VERSION "HNNBNNNYNNNNNNNNNNNNNNNNNNNNNNNNNNNNNNNNNN/4/%%%/4/'%**4NNN///"

NS_ :

BS_:

BU_: Frontradar Frontsensorik

BO_ 930 PSD_02: 8 Vector__XXX
 SG_ PSD_Multiplex M : 0|2@1+ (1,0) [0|3] ""  Frontsensorik
 SG_ PSD_Sys_Segment_ID m0 : 2|6@1+ (1,0) [2|63] ""  Frontsensorik
 SG_ PSD_Abz_Segment_ID m1 : 2|6@1+ (1,0) [2|63] ""  Frontsensorik
 SG_ PSD_Ges_Segment_ID m2 : 2|6@1+ (1,0) [2|63] ""  Frontsensorik
 SG_ PSD_Ort_Laenge_VZ m3 : 2|1@1+ (1,0) [0|1] ""  Frontsensorik
 SG_ PSD_Ort_Laenge m3 : 3|25@1+ (1E-005,0) [0|180] "Unit_DegreOfArc"  Frontsensorik
 SG_ PSD_Sys_Laendercode m0 : 8|8@1+ (1,0) [0|255] ""  Frontsensorik
 SG_ PSD_Abz_Segmentlaenge m1 : 8|7@1+ (2,0) [0|254] "Unit_Meter"  Frontsensorik
 SG_ PSD_Ges_Geschwindigkeit m2 : 8|5@1+ (1,0) [0|31] ""  Frontsensorik
 SG_ PSD_Ges_Geschwindigkeit_Typ m2 : 13|1@1+ (1,0) [0|1] ""  Frontsensorik
 SG_ PSD_Ges_Geschwindigkeit_Gespann m2 : 14|2@1+ (1,0) [0|3] ""  Frontsensorik
 SG_ PSD_Abz_Vorgaenger_Segment_ID m1 : 15|6@1+ (1,0) [2|63] ""  Frontsensorik
 SG_ PSD_Sys_Geschwindigkeit_Einheit m0 : 16|1@1+ (1,0) [0|1] ""  Frontsensorik
 SG_ PSD_Ges_Geschwindigkeit_Witter m2 : 16|2@1+ (1,0) [0|3] ""  Frontsensorik
 SG_ PSD_Sys_Verkehrsrichtung m0 : 17|1@1+ (1,0) [0|1] ""  Frontsensorik
 SG_ PSD_Sys_Release_Monat m0 : 18|4@1+ (1,0) [1|12] "Unit_Month"  Frontsensorik
 SG_ PSD_Ges_Geschwindigkeit_Tag_Anf m2 : 18|3@1+ (1,0) [0|7] ""  Frontsensorik
 SG_ PSD_Abz_Geschwindigkeit m1 : 21|5@1+ (1,0) [0|31] ""  Frontsensorik
 SG_ PSD_Ges_Geschwindigkeit_Tag_Ende m2 : 21|3@1+ (1,0) [0|7] ""  Frontsensorik
 SG_ PSD_Sys_Release_Jahr m0 : 22|5@1+ (1,2000) [2000|2031] "Unit_Year"  Frontsensorik
 SG_ PSD_Ges_Geschwindigkeit_Std_Anf m2 : 24|5@1+ (1,0) [0|24] "Unit_Hours"  Frontsensorik
 SG_ PSD_Abz_Geschwindigkeit_Typ m1 : 26|1@1+ (1,0) [0|1] ""  Frontsensorik
 SG_ PSD_Sys_Tunnel m0 : 27|1@1+ (1,0) [0|1] ""  Frontsensorik
 SG_ PSD_Abz_Strassenklasse m1 : 27|2@1+ (1,0) [0|3] ""  Frontsensorik
 SG_ PSD_Sys_Bruecke m0 : 28|1@1+ (1,0) [0|1] ""  Frontsensorik
 SG_ PSD_Ort_Breite_VZ m3 : 28|1@1+ (1,0) [0|1] ""  Frontsensorik
 SG_ PSD_Sys_Fahrsp_Gegenr m0 : 29|2@1+ (1,0) [0|3] ""  Frontsensorik
 SG_ PSD_Abz_ADAS_Qualitaet m1 : 29|1@1+ (1,0) [0|1] ""  Frontsensorik
 SG_ PSD_Ges_Geschwindigkeit_Std_Ende m2 : 29|5@1+ (1,0) [0|24] "Unit_Hours"  Frontsensorik
 SG_ PSD_Ort_Breite m3 : 29|24@1+ (1E-005,0) [0|90] "Unit_DegreOfArc"  Frontsensorik
 SG_ PSD_Abz_Abzweigerichtung m1 : 30|1@1+ (1,0) [0|1] ""  Frontsensorik
 SG_ PSD_Sys_TMC_Baustelle m0 : 31|1@1+ (1,0) [0|1] ""  Frontsensorik
 SG_ PSD_Abz_Abzweigewinkel m1 : 31|4@1+ (1,0) [0|15] ""  Frontsensorik
 SG_ PSD_Sys_TMC_Stau m0 : 32|1@1+ (1,0) [0|1] ""  Frontsensorik
 SG_ PSD_Sys_Bauliche_Trennung m0 : 33|2@1+ (1,0) [0|3] ""  Frontsensorik
 SG_ PSD_Ges_alter_Geschw m2 : 34|5@1+ (1,0) [0|31] ""  Frontsensorik
 SG_ PSD_Sys_Geometrieguete m0 : 35|2@1+ (1,0) [0|3] ""  Frontsensorik
 SG_ PSD_Abz_Rampe m1 : 35|2@1+ (1,0) [0|3] ""  Frontsensorik
 SG_ PSD_Sys_Maut m0 : 37|1@1+ (1,0) [0|1] ""  Frontsensorik
 SG_ PSD_Abz_Anfangskruemmung m1 : 37|8@1+ (1,0) [0|254] "Unit_None"  Frontsensorik
 SG_ PSD_Sys_Strassensituation m0 : 38|2@1+ (1,0) [0|3] ""  Frontsensorik
 SG_ PSD_Ges_alter_Geschw_Gespann m2 : 39|2@1+ (1,0) [0|3] ""  Frontsensorik
 SG_ PSD_Sys_StrKlassen_erweitert m0 : 40|3@1+ (1,0) [0|7] ""  Frontsensorik
 SG_ PSD_Ges_alter_Geschw_Witter m2 : 41|2@1+ (1,0) [0|3] ""  Frontsensorik
 SG_ PSD_Sys_Ortsschild m0 : 43|1@1+ (1,0) [0|1] ""  Frontsensorik
 SG_ PSD_Ges_alter_Geschw_Tag_Anf m2 : 43|3@1+ (1,0) [0|7] ""  Frontsensorik
 SG_ PSD_Abz_Anfangskruemmung_Vorz m1 : 45|1@1+ (1,0) [0|1] ""  Frontsensorik
 SG_ PSD_Sys_Anfangskruemmung m0 : 46|8@1+ (1,0) [0|254] "Unit_None"  Frontsensorik
 SG_ PSD_Abz_Endkruemmung m1 : 46|8@1+ (1,0) [0|254] "Unit_None"  Frontsensorik
 SG_ PSD_Ges_alter_Geschw_Tag_Ende m2 : 46|3@1+ (1,0) [0|7] ""  Frontsensorik
 SG_ PSD_Ges_alter_Geschw_Std_Anf m2 : 49|5@1+ (1,0) [0|24] "Unit_Hours"  Frontsensorik
 SG_ PSD_Ort_Hoehe m3 : 53|11@1+ (5,-1000) [-1000|8000] "Unit_Meter"  Frontsensorik
 SG_ PSD_Sys_Anfangskruemmung_Vorz m0 : 54|1@1+ (1,0) [0|1] ""  Frontsensorik
 SG_ PSD_Abz_Endkruemmung_Vorz m1 : 54|1@1+ (1,0) [0|1] ""  Frontsensorik
 SG_ PSD_Ges_alter_Geschw_Std_Ende m2 : 54|5@1+ (1,0) [0|24] "Unit_Hours"  Frontsensorik
 SG_ PSD_Sys_Anfangssteigung m0 : 55|5@1+ (0.5,0) [0|14.5] "Unit_PerCent"  Frontsensorik
 SG_ PSD_Abz_Endsteigung m1 : 55|5@1+ (0.5,0) [0|14.5] "Unit_PerCent"  Frontsensorik
 SG_ PSD_Ges_Ueberholverbot m2 : 59|2@1+ (1,0) [0|3] ""  Frontsensorik
 SG_ PSD_Sys_Anfangssteigung_Vorz m0 : 60|1@1+ (1,0) [0|1] ""  Frontsensorik
 SG_ PSD_Abz_Endsteigung_Vorz m1 : 60|1@1+ (1,0) [0|1] ""  Frontsensorik
 SG_ PSD_Sys_Ortschaft m0 : 61|1@1+ (1,0) [0|1] ""  Frontsensorik
 SG_ PSD_Abz_Fahrspuren m1 : 61|2@1+ (1,0) [0|3] ""  Frontsensorik
 SG_ PSD_Ges_Wechselverkehrszeichen m2 : 61|3@1+ (1,0) [0|7] ""  Frontsensorik
 SG_ PSD_Sys_Digitalisierung m0 : 62|1@1+ (1,0) [0|1] ""  Frontsensorik
 SG_ PSD_Sys_Zielfuehrung m0 : 63|1@1+ (1,0) [0|1] ""  Frontsensorik
 SG_ PSD_Abz_wahrscheinlichster_Pfad m1 : 63|1@1+ (1,0) [0|1] ""  Frontsensorik

BO_ 1122 PSD_04: 8 Vector__XXX
 SG_ PSD_Segment_ID : 0|6@1+ (1,0) [2|63] ""  Frontradar,Frontsensorik
 SG_ PSD_Vorgaenger_Segment_ID : 6|6@1+ (1,0) [2|63] ""  Frontradar,Frontsensorik
 SG_ PSD_Segmentlaenge : 12|7@1+ (2,0) [0|254] "Unit_Meter"  Frontradar,Frontsensorik
 SG_ PSD_Strassenkategorie : 19|3@1+ (1,0) [0|7] ""  Frontradar,Frontsensorik
 SG_ PSD_Endkruemmung : 22|8@1+ (1,0) [0|254] "Unit_None"  Frontradar,Frontsensorik
 SG_ PSD_Endkruemmung_Vorz : 30|1@1+ (1,0) [0|1] ""  Frontradar,Frontsensorik
 SG_ PSD_Idenditaets_ID : 31|6@1+ (1,0) [2|63] ""  Frontradar,Frontsensorik
 SG_ PSD_ADAS_Qualitaet : 37|1@1+ (1,0) [0|1] ""  Frontradar,Frontsensorik
 SG_ PSD_wahrscheinlichster_Pfad : 38|1@1+ (1,0) [0|1] ""  Frontradar,Frontsensorik
 SG_ PSD_Geradester_Pfad : 39|1@1+ (1,0) [0|1] ""  Frontradar,Frontsensorik
 SG_ PSD_Fahrspuren_Anzahl : 40|3@1+ (1,0) [0|7] ""  Frontradar,Frontsensorik
 SG_ PSD_Bebauung : 43|1@1+ (1,0) [0|1] ""  Frontradar,Frontsensorik
 SG_ PSD_Segment_Komplett : 44|1@1+ (1,0) [0|1] ""  Frontradar,Frontsensorik
 SG_ PSD_Rampe : 45|2@1+ (1,0) [0|3] ""  Frontradar,Frontsensorik
 SG_ PSD_Anfangskruemmung : 47|8@1+ (1,0) [0|254] ""  Frontradar,Frontsensorik
 SG_ PSD_Anfangskruemmung_Vorz : 55|1@1+ (1,0) [0|1] ""  Frontradar,Frontsensorik
 SG_ PSD_Abzweigerichtung : 56|1@1+ (1,0) [0|1] ""  Frontradar,Frontsensorik
 SG_ PSD_Abzweigewinkel : 57|7@1+ (1.417323,0) [0|180.000021] ""  Frontradar,Frontsensorik

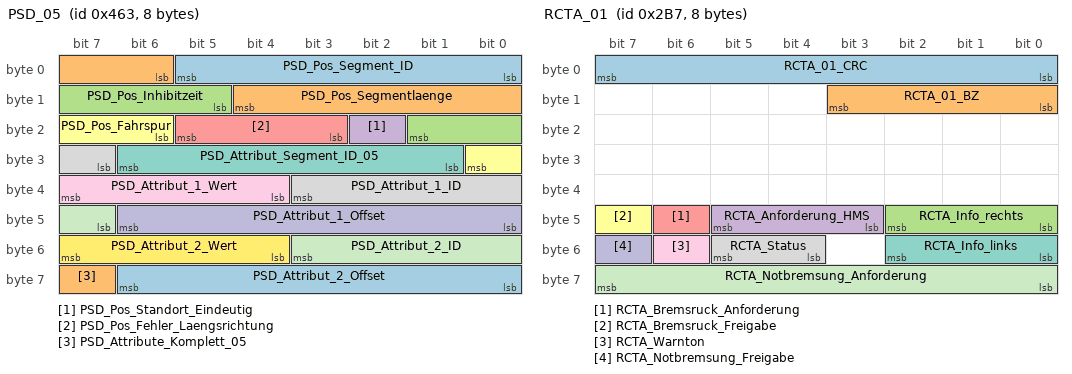
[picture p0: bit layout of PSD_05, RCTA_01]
BO_ 1123 PSD_05: 8 Vector__XXX
 SG_ PSD_Pos_Segment_ID : 0|6@1+ (1,0) [2|63] ""  Frontradar,Frontsensorik
 SG_ PSD_Pos_Segmentlaenge : 6|7@1+ (2,0) [0|254] "Unit_Meter"  Frontradar,Frontsensorik
 SG_ PSD_Pos_Inhibitzeit : 13|5@1+ (10,0) [0|310] "Unit_MilliSecon"  Frontradar,Frontsensorik
 SG_ PSD_Pos_Standort_Eindeutig : 18|1@1+ (1,0) [0|1] ""  Frontradar,Frontsensorik
 SG_ PSD_Pos_Fehler_Laengsrichtung : 19|3@1+ (1,0) [0|7] ""  Frontradar,Frontsensorik
 SG_ PSD_Pos_Fahrspur : 22|3@1+ (1,0) [0|7] ""  Frontradar,Frontsensorik
 SG_ PSD_Attribut_Segment_ID_05 : 25|6@1+ (1,0) [2|63] ""  Frontradar,Frontsensorik
 SG_ PSD_Attribut_1_ID : 31|5@1+ (1,0) [1|31] ""  Frontradar,Frontsensorik
 SG_ PSD_Attribut_1_Wert : 36|4@1+ (1,0) [0|15] ""  Frontradar,Frontsensorik
 SG_ PSD_Attribut_1_Offset : 40|7@1+ (2,0) [0|254] "Unit_Meter"  Frontradar,Frontsensorik
 SG_ PSD_Attribut_2_ID : 47|5@1+ (1,0) [1|31] ""  Frontradar,Frontsensorik
 SG_ PSD_Attribut_2_Wert : 52|4@1+ (1,0) [0|15] ""  Frontradar,Frontsensorik
 SG_ PSD_Attribut_2_Offset : 56|7@1+ (2,0) [0|254] "Unit_Meter"  Frontradar,Frontsensorik
 SG_ PSD_Attribute_Komplett_05 : 63|1@1+ (1,0) [0|1] ""  Frontradar,Frontsensorik

BO_ 1124 PSD_06: 8 Vector__XXX
 SG_ PSD_06_Mux M : 0|3@1+ (1,0) [0|7] ""  Frontradar,Frontsensorik
 SG_ PSD_Sys_Segment_ID m0 : 3|6@1+ (1,0) [2|63] ""  Frontradar,Frontsensorik
 SG_ PSD_Attribut_Segment_ID m1 : 3|6@1+ (1,0) [2|63] ""  Frontradar,Frontsensorik
 SG_ PSD_Ges_Segment_ID m2 : 3|6@1+ (1,0) [2|63] ""  Frontradar,Frontsensorik
 SG_ PSD_Baum_Laenge_VZ m3 : 3|1@1+ (1,0) [0|1] ""  Frontradar,Frontsensorik
 SG_ PSD_Steigung_1_Segment_ID m4 : 3|6@1+ (1,0) [2|63] ""  Frontradar,Frontsensorik
 SG_ PSD_Baum_Laenge m3 : 4|25@1+ (1E-005,0) [0|180] "Unit_DegreOfArc"  Frontradar,Frontsensorik
 SG_ PSD_Sys_Laendercode m0 : 9|8@1+ (1,0) [0|255] ""  Frontradar,Frontsensorik
 SG_ PSD_Attribut_3_ID m1 : 9|5@1+ (1,0) [1|31] ""  Frontradar,Frontsensorik
 SG_ PSD_Ges_Offset m2 : 9|7@1+ (2,0) [0|254] "Unit_Meter"  Frontradar,Frontsensorik
 SG_ PSD_Steigung_1_A_Steigung m4 : 9|7@1+ (0.12,0) [0|15] "Unit_PerCent"  Frontradar,Frontsensorik
 SG_ PSD_Attribut_3_Offset m1 : 14|7@1+ (2,0) [0|254] "Unit_Meter"  Frontradar,Frontsensorik
 SG_ PSD_Ges_Geschwindigkeit m2 : 16|5@1+ (1,0) [0|31] ""  Frontradar,Frontsensorik
 SG_ PSD_Steigung_1_A_Vorz m4 : 16|1@1+ (1,0) [0|1] ""  Frontradar,Frontsensorik
 SG_ PSD_Sys_Geschwindigkeit_Einheit m0 : 17|1@1+ (1,0) [0|1] ""  Frontradar,Frontsensorik
 SG_ PSD_Steigung_1_A_Offset m4 : 17|7@1+ (2,0) [0|254] "Unit_Meter"  Frontradar,Frontsensorik
 SG_ PSD_Sys_Verkehrsrichtung m0 : 18|1@1+ (1,0) [0|1] ""  Frontradar,Frontsensorik
 SG_ PSD_Sys_Geometrieguete m0 : 19|2@1+ (1,0) [0|3] ""  Frontradar,Frontsensorik
 SG_ PSD_Sys_Mapmatchingguete m0 : 21|2@1+ (1,0) [0|3] ""  Frontradar,Frontsensorik
 SG_ PSD_Attribut_3_Wert m1 : 21|4@1+ (1,0) [0|15] ""  Frontradar,Frontsensorik
 SG_ PSD_Ges_Typ m2 : 21|2@1+ (1,0) [0|3] ""  Frontradar,Frontsensorik
 SG_ PSD_Sys_Alter_Karte m0 : 23|3@1+ (1,0) [0|7] ""  Frontradar,Frontsensorik
 SG_ PSD_Ges_Spur_Geschw_Begrenzung m2 : 23|6@1+ (1,0) [0|63] ""  Frontradar,Frontsensorik
 SG_ PSD_Steigung_1_B_Steigung m4 : 24|7@1+ (0.12,0) [0|15] "Unit_PerCent"  Frontradar,Frontsensorik
 SG_ PSD_Attribut_4_ID m1 : 25|5@1+ (1,0) [1|31] ""  Frontradar,Frontsensorik
 SG_ PSD_Sys_Zielfuehrung m0 : 26|1@1+ (1,0) [0|1] ""  Frontradar,Frontsensorik
 SG_ PSD_Sys_US_State m0 : 27|6@1+ (1,0) [0|63] ""  Frontradar,Frontsensorik
 SG_ PSD_Ges_Geschwindigkeit_Gespann m2 : 29|2@1+ (1,0) [0|3] ""  Frontradar,Frontsensorik
 SG_ PSD_Baum_Breite_VZ m3 : 29|1@1+ (1,0) [0|1] ""  Frontradar,Frontsensorik
 SG_ PSD_Attribut_4_Wert m1 : 30|4@1+ (1,0) [0|15] ""  Frontradar,Frontsensorik
 SG_ PSD_Baum_Breite m3 : 30|24@1+ (1E-005,0) [0|90] "Unit_DegreOfArc"  Frontradar,Frontsensorik
 SG_ PSD_Ges_Geschwindigkeit_Witter m2 : 31|2@1+ (1,0) [0|3] ""  Frontradar,Frontsensorik
 SG_ PSD_Steigung_1_B_Vorz m4 : 31|1@1+ (1,0) [0|1] ""  Frontradar,Frontsensorik
 SG_ PSD_Steigung_1_B_Offset m4 : 32|7@1+ (2,0) [0|254] "Unit_Meter"  Frontradar,Frontsensorik
 SG_ PSD_Ges_Geschwindigkeit_Tag_Anf m2 : 33|3@1+ (1,0) [0|7] ""  Frontradar,Frontsensorik
 SG_ PSD_Attribut_4_Offset m1 : 34|7@1+ (2,0) [0|254] "Unit_Meter"  Frontradar,Frontsensorik
 SG_ PSD_Ges_Geschwindigkeit_Tag_Ende m2 : 36|3@1+ (1,0) [0|7] ""  Frontradar,Frontsensorik
 SG_ PSD_Ges_Geschwindigkeit_Std_Anf m2 : 39|5@1+ (1,0) [0|24] "Unit_Hours"  Frontradar,Frontsensorik
 SG_ PSD_Steigung_1_Attribute_kompl m4 : 39|1@1+ (1,0) [0|1] ""  Frontradar,Frontsensorik
 SG_ PSD_Steigung_2_Segment_ID m4 : 40|6@1+ (1,0) [2|63] ""  Frontradar,Frontsensorik
 SG_ PSD_Attribut_5_ID m1 : 41|5@1+ (1,0) [1|31] ""  Frontradar,Frontsensorik
 SG_ PSD_Ges_Geschwindigkeit_Std_Ende m2 : 44|5@1+ (1,0) [0|24] "Unit_Hours"  Frontradar,Frontsensorik
 SG_ PSD_Attribut_5_Offset m1 : 46|7@1+ (2,0) [0|254] "Unit_Meter"  Frontradar,Frontsensorik
 SG_ PSD_Steigung_2_Steigung m4 : 46|7@1+ (0.12,0) [0|15] "Unit_PerCent"  Frontradar,Frontsensorik
 SG_ PSD_Ges_Ueberholverbot m2 : 49|2@1+ (1,0) [0|3] ""  Frontradar,Frontsensorik
 SG_ PSD_Ges_Wechselverkehrszeichen m2 : 51|3@1+ (1,0) [0|7] ""  Frontradar,Frontsensorik
 SG_ PSD_Attribut_5_Wert m1 : 53|4@1+ (1,0) [0|15] ""  Frontradar,Frontsensorik
 SG_ PSD_Steigung_2_Vorz m4 : 53|1@1+ (1,0) [0|1] ""  Frontradar,Frontsensorik
 SG_ PSD_Wechselverkehrszeichen_Typ m2 : 54|2@1+ (1,0) [0|3] ""  Frontradar,Frontsensorik
 SG_ PSD_Baum_Ausrichtung m3 : 54|10@1+ (0.3515625,0) [0|359.6484375] "Unit_DegreOfArc"  Frontradar,Frontsensorik
 SG_ PSD_Steigung_2_Offset m4 : 54|7@1+ (2,0) [0|254] "Unit_Meter"  Frontradar,Frontsensorik
 SG_ PSD_Ges_Gesetzlich_Kategorie m2 : 56|3@1+ (1,0) [0|7] ""  Frontradar,Frontsensorik
 SG_ PSD_Attribute_Komplett_06 m1 : 57|1@1+ (1,0) [0|1] ""  Frontradar,Frontsensorik
 SG_ PSD_Ges_Gesetzlich_Zusatz m2 : 59|2@1+ (1,0) [0|3] ""  Frontradar,Frontsensorik
 SG_ PSD_Ges_Verkehrszeichen_Quelle m2 : 61|2@1+ (1,0) [0|3] ""  Frontradar,Frontsensorik
 SG_ PSD_Steigung_2_Attribute_kompl m4 : 61|1@1+ (1,0) [0|1] ""  Frontradar,Frontsensorik
 SG_ PSD_Ges_Attribute_Komplett m2 : 63|1@1+ (1,0) [0|1] ""  Frontradar,Frontsensorik

BO_ 695 RCTA_01: 8 Vector__XXX
 SG_ RCTA_01_CRC : 0|8@1+ (1,0) [0|255] "" Vector__XXX
 SG_ RCTA_01_BZ : 8|4@1+ (1,0) [0|15] "" Vector__XXX
 SG_ RCTA_Info_rechts : 40|3@1+ (1,0) [0|7] "" Vector__XXX
 SG_ RCTA_Anforderung_HMS : 43|3@1+ (1,0) [0|7] "" Vector__XXX
 SG_ RCTA_Bremsruck_Anforderung : 46|1@1+ (1,0) [0|1] "" Vector__XXX
 SG_ RCTA_Bremsruck_Freigabe : 47|1@1+ (1,0) [0|1] "" Vector__XXX
 SG_ RCTA_Info_links : 48|3@1+ (1,0) [0|7] "" Vector__XXX
 SG_ RCTA_Status : 52|2@1+ (1,0) [0|3] "" Vector__XXX
 SG_ RCTA_Warnton : 54|1@1+ (1,0) [0|1] "" Vector__XXX
 SG_ RCTA_Notbremsung_Freigabe : 55|1@1+ (1,0) [0|1] "" Vector__XXX
 SG_ RCTA_Notbremsung_Anforderung : 56|8@1+ (0.078,-19.812) [-19.734|0] "Unit_MeterPerSeconSquar" Vector__XXX

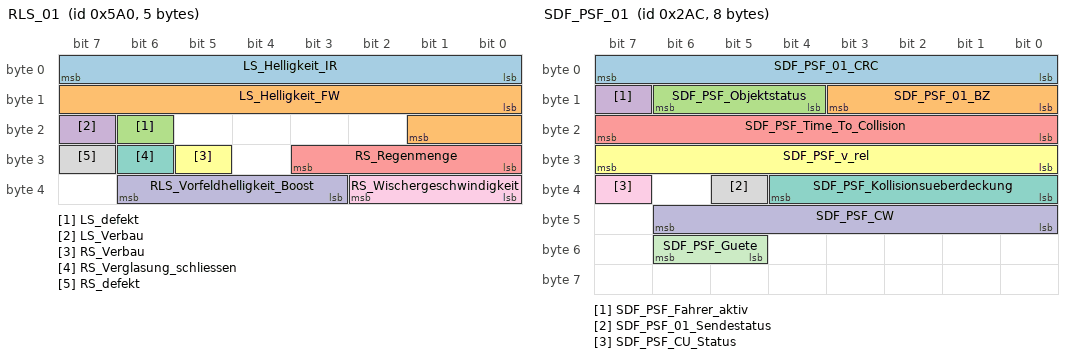
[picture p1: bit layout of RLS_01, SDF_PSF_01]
BO_ 1440 RLS_01: 5 Vector__XXX
 SG_ LS_Helligkeit_IR : 0|8@1+ (400,0) [0|101200] "Unit_Lux" Vector__XXX
 SG_ LS_Helligkeit_FW : 8|10@1+ (6,0) [0|6126] "Unit_Lux" Vector__XXX
 SG_ LS_defekt : 22|1@1+ (1,0) [0|1] "" Vector__XXX
 SG_ LS_Verbau : 23|1@1+ (1,0) [0|1] "" Vector__XXX
 SG_ RS_Regenmenge : 24|4@1+ (10,0) [0|100] "Unit_PerCent"  Frontsensorik
 SG_ RS_Verbau : 29|1@1+ (1,0) [0|1] "" Vector__XXX
 SG_ RS_Verglasung_schliessen : 30|1@1+ (1,0) [0|1] "" Vector__XXX
 SG_ RS_defekt : 31|1@1+ (1,0) [0|1] "" Vector__XXX
 SG_ RS_Wischergeschwindigkeit : 32|3@1+ (1,0) [0|7] ""  Frontsensorik
 SG_ RLS_Vorfeldhelligkeit_Boost : 35|4@1+ (1,0) [0|15] "" Vector__XXX

BO_ 684 SDF_PSF_01: 8 Frontradar
 SG_ SDF_PSF_01_CRC : 0|8@1+ (1,0) [0|255] "" Vector__XXX
 SG_ SDF_PSF_01_BZ : 8|4@1+ (1,0) [0|15] "" Vector__XXX
 SG_ SDF_PSF_Objektstatus : 12|3@1+ (1,0) [0|7] "" Vector__XXX
 SG_ SDF_PSF_Fahrer_aktiv : 15|1@1+ (1,0) [0|1] "" Vector__XXX
 SG_ SDF_PSF_Time_To_Collision : 16|8@1+ (0.01,0) [0|2.5] "Unit_Secon" Vector__XXX
 SG_ SDF_PSF_v_rel : 24|8@1+ (0.4,0) [0.4|101.2] "Unit_MeterPerSecon" Vector__XXX
 SG_ SDF_PSF_Kollisionsueberdeckung : 32|5@1+ (0.1,0) [0.1|2.8] "Unit_Meter" Vector__XXX
 SG_ SDF_PSF_01_Sendestatus : 37|1@1+ (1,0) [0|1] "" Vector__XXX
 SG_ SDF_PSF_CU_Status : 39|1@1+ (1,0) [0|1] "" Vector__XXX
 SG_ SDF_PSF_CW : 40|7@1+ (1,0) [0|100] "" Vector__XXX
 SG_ SDF_PSF_Guete : 53|2@1+ (1,0) [0|3] "" Vector__XXX

BO_ 783 SWA_01: 8 Vector__XXX
 SG_ SWA_01_CRC : 0|8@1+ (1,0) [0|255] ""  Frontradar
 SG_ SWA_01_BZ : 8|4@1+ (1,0) [0|15] ""  Frontradar
 SG_ SWA_Anzeigen : 12|4@1+ (1,0) [0|15] "" Vector__XXX
 SG_ SWA_Blindheit_erkannt : 16|1@1+ (1,0) [0|1] ""  Frontradar
 SG_ SWA_rel_Nichtverf : 17|1@1+ (1,0) [0|1] ""  Frontradar
 SG_ SWA_rel_Fehler : 18|1@1+ (1,0) [0|1] ""  Frontradar
 SG_ SWA_Sta_aktiv : 19|1@1+ (1,0) [0|1] "" Vector__XXX
 SG_ SWA_Sta_passiv : 20|1@1+ (1,0) [0|1] "" Vector__XXX
 SG_ SWA_FT_RueckLED : 21|1@1+ (1,0) [0|1] "" Vector__XXX
 SG_ ASW_Status : 22|2@1+ (1,0) [0|3] "" Vector__XXX
 SG_ SWA_Standziele_li : 24|1@1+ (1,0) [0|1] ""  Frontradar
 SG_ SWA_Kolonne_li : 25|1@1+ (1,0) [0|1] ""  Frontradar
 SG_ SWA_Infostufe_SWA_li : 26|1@1+ (1,0) [0|1] ""  Frontradar,Frontsensorik
 SG_ SWA_Warnung_SWA_li : 27|1@1+ (1,0) [0|1] ""  Frontradar,Frontsensorik
 SG_ ASW_Warnung_FS : 28|1@1+ (1,0) [0|1] "" Vector__XXX
 SG_ ASW_Warnung_BFS : 29|1@1+ (1,0) [0|1] "" Vector__XXX
 SG_ ASW_Kombitexte : 30|3@1+ (1,0) [0|7] "" Vector__XXX
 SG_ SWA_Kolonne_mi : 33|1@1+ (1,0) [0|1] ""  Frontradar
 SG_ SWA_Standziele_re : 40|1@1+ (1,0) [0|1] ""  Frontradar
 SG_ SWA_Kolonne_re : 41|1@1+ (1,0) [0|1] ""  Frontradar
 SG_ SWA_Infostufe_SWA_re : 42|1@1+ (1,0) [0|1] ""  Frontradar,Frontsensorik
 SG_ SWA_Warnung_SWA_re : 43|1@1+ (1,0) [0|1] ""  Frontradar,Frontsensorik
 SG_ HRE_Anzeigetexte : 44|4@1+ (1,0) [0|15] "" Vector__XXX
 SG_ SWA_Gischtzaehler : 48|7@1+ (1,0) [0|100] "Unit_PerCent"  Frontsensorik
 SG_ Heckradar_Kombitexte : 56|5@1+ (1,0) [0|31] "" Vector__XXX
 SG_ RCTA_Kombitexte : 61|3@1+ (1,0) [0|7] "" Vector__XXX

BO_ 1413 Systeminfo_01: 8 Vector__XXX
 SG_ SI_Sammel_SG_Fehler : 0|6@1+ (1,0) [0|60] "" Vector__XXX
 SG_ SI_Diagnose_Aktiv : 7|1@1+ (1,0) [0|1] "" Vector__XXX
 SG_ SI_QRS_Mode : 8|1@1+ (1,0) [0|1] "" Vector__XXX
 SG_ SI_T_Mode : 9|1@1+ (1,0) [0|1] "" Vector__XXX
 SG_ SI_NWDF : 10|1@1+ (1,0) [0|1] ""  Frontradar,Frontsensorik
 SG_ SI_NWDF_gueltig : 11|1@1+ (1,0) [0|1] ""  Frontradar,Frontsensorik
 SG_ SI_Sammelfehler : 12|1@1+ (1,0) [0|1] "" Vector__XXX
 SG_ GW_KD_Fehler : 13|1@1+ (1,0) [0|1] "" Vector__XXX
 SG_ SI_T_Schutz : 14|1@1+ (1,0) [0|1] ""  Frontradar
 SG_ SI_BUS_01 : 16|1@1+ (1,0) [0|1] "" Vector__XXX
 SG_ SI_BUS_02 : 17|1@1+ (1,0) [0|1] "" Vector__XXX
 SG_ SI_BUS_03 : 18|1@1+ (1,0) [0|1] "" Vector__XXX
 SG_ SI_BUS_04 : 19|1@1+ (1,0) [0|1] "" Vector__XXX
 SG_ SI_BUS_05 : 20|1@1+ (1,0) [0|1] "" Vector__XXX
 SG_ SI_BUS_06 : 21|1@1+ (1,0) [0|1] "" Vector__XXX
 SG_ SI_BUS_07 : 22|1@1+ (1,0) [0|1] "" Vector__XXX
 SG_ SI_BUS_08 : 23|1@1+ (1,0) [0|1] "" Vector__XXX
 SG_ SI_BUS_09 : 24|1@1+ (1,0) [0|1] "" Vector__XXX
 SG_ SI_BUS_10 : 25|1@1+ (1,0) [0|1] "" Vector__XXX
 SG_ SI_BUS_11 : 26|1@1+ (1,0) [0|1] "" Vector__XXX
 SG_ SI_BUS_12 : 27|1@1+ (1,0) [0|1] "" Vector__XXX
 SG_ SI_BUS_13 : 28|1@1+ (1,0) [0|1] "" Vector__XXX
 SG_ SI_BUS_14 : 29|1@1+ (1,0) [0|1] "" Vector__XXX
 SG_ SI_BUS_15 : 30|1@1+ (1,0) [0|1] "" Vector__XXX
 SG_ SI_Bus_Identifikation : 32|8@1+ (1,0) [0|255] "" Vector__XXX

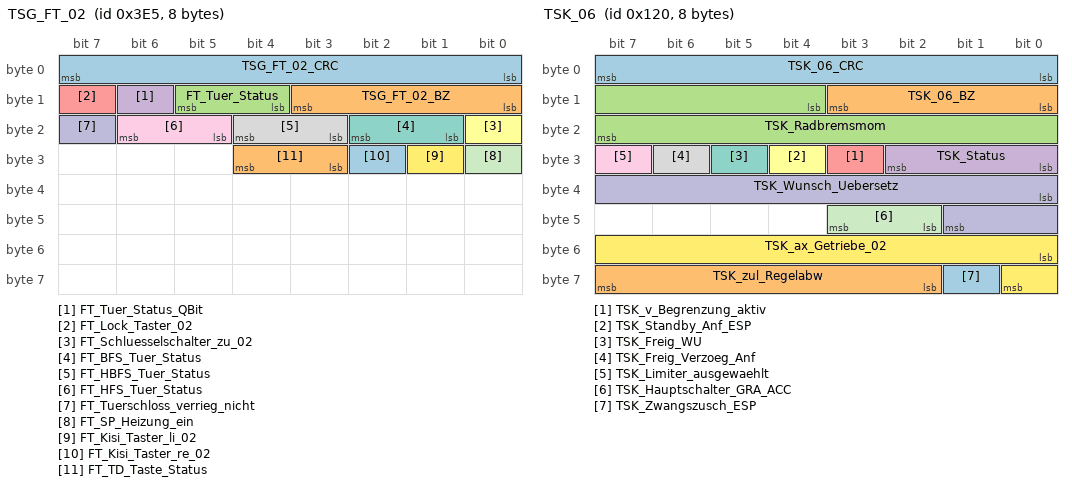
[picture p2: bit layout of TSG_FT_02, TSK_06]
BO_ 997 TSG_FT_02: 8 Vector__XXX
 SG_ TSG_FT_02_CRC : 0|8@1+ (1,0) [0|255] ""  Frontradar
 SG_ TSG_FT_02_BZ : 8|4@1+ (1,0) [0|15] ""  Frontradar
 SG_ FT_Tuer_Status : 12|2@1+ (1,0) [0|3] ""  Frontradar
 SG_ FT_Tuer_Status_QBit : 14|1@1+ (1,0) [0|1] ""  Frontradar
 SG_ FT_Lock_Taster_02 : 15|1@1+ (1,0) [0|1] "" Vector__XXX
 SG_ FT_Schluesselschalter_zu_02 : 16|1@1+ (1,0) [0|1] "" Vector__XXX
 SG_ FT_BFS_Tuer_Status : 17|2@1+ (1,0) [0|3] "" Vector__XXX
 SG_ FT_HBFS_Tuer_Status : 19|2@1+ (1,0) [0|3] "" Vector__XXX
 SG_ FT_HFS_Tuer_Status : 21|2@1+ (1,0) [0|3] "" Vector__XXX
 SG_ FT_Tuerschloss_verrieg_nicht : 23|1@1+ (1,0) [0|1] "" Vector__XXX
 SG_ FT_SP_Heizung_ein : 24|1@1+ (1,0) [0|1] "" Vector__XXX
 SG_ FT_Kisi_Taster_li_02 : 25|1@1+ (1,0) [0|1] "" Vector__XXX
 SG_ FT_Kisi_Taster_re_02 : 26|1@1+ (1,0) [0|1] "" Vector__XXX
 SG_ FT_TD_Taste_Status : 27|2@1+ (1,0) [0|3] "" Vector__XXX

BO_ 288 TSK_06: 8 Vector__XXX
 SG_ TSK_06_CRC : 0|8@1+ (1,0) [0|255] ""  Frontradar,Frontsensorik
 SG_ TSK_06_BZ : 8|4@1+ (1,0) [0|15] ""  Frontradar,Frontsensorik
 SG_ TSK_Radbremsmom : 12|12@1+ (8,0) [0|32760] "Unit_NewtoMeter" Vector__XXX
 SG_ TSK_Status : 24|3@1+ (1,0) [0|7] ""  Frontradar,Frontsensorik
 SG_ TSK_v_Begrenzung_aktiv : 27|1@1+ (1,0) [0|1] "" Vector__XXX
 SG_ TSK_Standby_Anf_ESP : 28|1@1+ (1,0) [0|1] "" Vector__XXX
 SG_ TSK_Freig_WU : 29|1@1+ (1,0) [0|1] "" Vector__XXX
 SG_ TSK_Freig_Verzoeg_Anf : 30|1@1+ (1,0) [0|1] "" Vector__XXX
 SG_ TSK_Limiter_ausgewaehlt : 31|1@1+ (1,0) [0|1] ""  Frontradar
 SG_ TSK_Wunsch_Uebersetz : 32|10@1+ (0.0245,0) [0.0245|25.0635] "" Vector__XXX
 SG_ TSK_Hauptschalter_GRA_ACC : 42|2@1+ (1,0) [0|3] ""  Frontradar
 SG_ TSK_ax_Getriebe_02 : 48|9@1+ (0.024,-2.016) [-2.016|10.224] "Unit_MeterPerSeconSquar" Vector__XXX
 SG_ TSK_Zwangszusch_ESP : 57|1@1+ (1,0) [0|1] "" Vector__XXX
 SG_ TSK_zul_Regelabw : 58|6@1+ (0.024,0) [0|1.512] "Unit_MeterPerSeconSquar" Vector__XXX

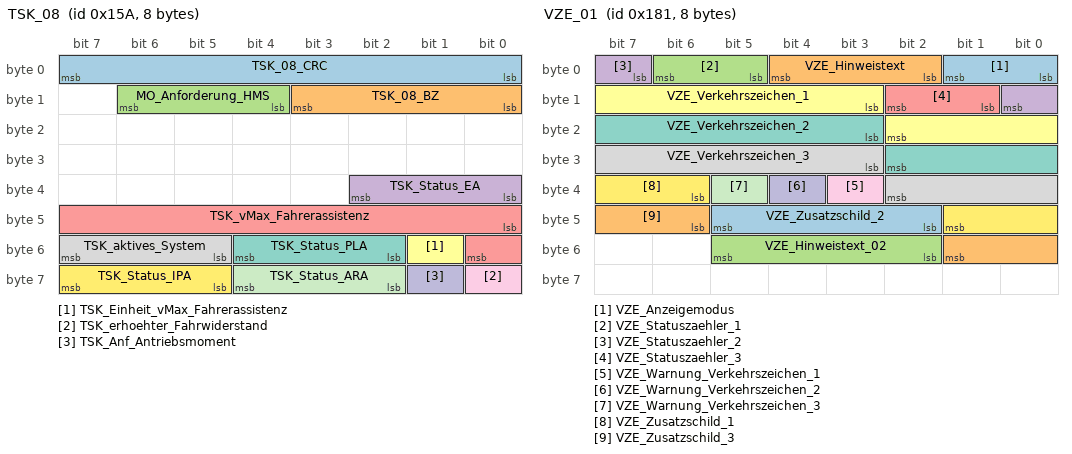
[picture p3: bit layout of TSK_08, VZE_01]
BO_ 346 TSK_08: 8 Vector__XXX
 SG_ TSK_08_CRC : 0|8@1+ (1,0) [0|255] ""  Frontradar
 SG_ TSK_08_BZ : 8|4@1+ (1,0) [0|15] ""  Frontradar
 SG_ MO_Anforderung_HMS : 12|3@1+ (1,0) [0|7] "" Vector__XXX
 SG_ TSK_Status_EA : 32|3@1+ (1,0) [0|7] "" Vector__XXX
 SG_ TSK_vMax_Fahrerassistenz : 40|9@1+ (1,0) [0|510] ""  Frontradar
 SG_ TSK_Einheit_vMax_Fahrerassistenz : 49|1@1+ (1,0) [0|1] ""  Frontradar
 SG_ TSK_Status_PLA : 50|3@1+ (1,0) [0|7] "" Vector__XXX
 SG_ TSK_aktives_System : 53|3@1+ (1,0) [0|7] "" Vector__XXX
 SG_ TSK_erhoehter_Fahrwiderstand : 56|1@1+ (1,0) [0|1] "" Vector__XXX
 SG_ TSK_Anf_Antriebsmoment : 57|1@1+ (1,0) [0|1] "" Vector__XXX
 SG_ TSK_Status_ARA : 58|3@1+ (1,0) [0|7] "" Vector__XXX
 SG_ TSK_Status_IPA : 61|3@1+ (1,0) [0|7] "" Vector__XXX

BO_ 1019 TSK_Ausrollkurve_01: 8 Vector__XXX
 SG_ TSK_Ausrollkurve_Schub_Reku_01 m0 : 0|7@1+ (2,0) [0|252] "Unit_KiloMeterPerHour"  Frontradar
 SG_ TSK_Ausrollkurve_Schub_Reku_05 m1 : 0|7@1+ (2,0) [0|252] "Unit_KiloMeterPerHour"  Frontradar
 SG_ TSK_Ausrollkurve_Schub_Reku_09 m2 : 0|7@1+ (2,0) [0|252] "Unit_KiloMeterPerHour"  Frontradar
 SG_ TSK_Ausrollkurve_Schub_Reku_13 m3 : 0|7@1+ (2,0) [0|252] "Unit_KiloMeterPerHour"  Frontradar
 SG_ TSK_Ausrollkurve_Schub_Reku_17 m4 : 0|7@1+ (2,0) [0|252] "Unit_KiloMeterPerHour"  Frontradar
 SG_ TSK_Ausrollkurve_Schub_Reku_02 m0 : 7|7@1+ (2,0) [0|252] "Unit_KiloMeterPerHour"  Frontradar
 SG_ TSK_Ausrollkurve_Schub_Reku_06 m1 : 7|7@1+ (2,0) [0|252] "Unit_KiloMeterPerHour"  Frontradar
 SG_ TSK_Ausrollkurve_Schub_Reku_10 m2 : 7|7@1+ (2,0) [0|252] "Unit_KiloMeterPerHour"  Frontradar
 SG_ TSK_Ausrollkurve_Schub_Reku_14 m3 : 7|7@1+ (2,0) [0|252] "Unit_KiloMeterPerHour"  Frontradar
 SG_ TSK_Ausrollkurve_Schub_Reku_18 m4 : 7|7@1+ (2,0) [0|252] "Unit_KiloMeterPerHour"  Frontradar
 SG_ TSK_Ausrollkurve_Schub_Reku_03 m0 : 14|7@1+ (2,0) [0|252] "Unit_KiloMeterPerHour"  Frontradar
 SG_ TSK_Ausrollkurve_Schub_Reku_07 m1 : 14|7@1+ (2,0) [0|252] "Unit_KiloMeterPerHour"  Frontradar
 SG_ TSK_Ausrollkurve_Schub_Reku_11 m2 : 14|7@1+ (2,0) [0|252] "Unit_KiloMeterPerHour"  Frontradar
 SG_ TSK_Ausrollkurve_Schub_Reku_15 m3 : 14|7@1+ (2,0) [0|252] "Unit_KiloMeterPerHour"  Frontradar
 SG_ TSK_Ausrollkurve_Schub_Reku_19 m4 : 14|7@1+ (2,0) [0|252] "Unit_KiloMeterPerHour"  Frontradar
 SG_ TSK_Ausrollkurve_Schub_Reku_04 m0 : 21|7@1+ (2,0) [0|252] "Unit_KiloMeterPerHour"  Frontradar
 SG_ TSK_Ausrollkurve_Schub_Reku_08 m1 : 21|7@1+ (2,0) [0|252] "Unit_KiloMeterPerHour"  Frontradar
 SG_ TSK_Ausrollkurve_Schub_Reku_12 m2 : 21|7@1+ (2,0) [0|252] "Unit_KiloMeterPerHour"  Frontradar
 SG_ TSK_Ausrollkurve_Schub_Reku_16 m3 : 21|7@1+ (2,0) [0|252] "Unit_KiloMeterPerHour"  Frontradar
 SG_ TSK_Ausrollkurve_Schub_Reku_20 m4 : 21|7@1+ (2,0) [0|252] "Unit_KiloMeterPerHour"  Frontradar
 SG_ TSK_Ausrollkurve_Segeln_01 m0 : 28|7@1+ (2,0) [0|252] "Unit_KiloMeterPerHour"  Frontradar
 SG_ TSK_Ausrollkurve_Segeln_05 m1 : 28|7@1+ (2,0) [0|252] "Unit_KiloMeterPerHour"  Frontradar
 SG_ TSK_Ausrollkurve_Segeln_09 m2 : 28|7@1+ (2,0) [0|252] "Unit_KiloMeterPerHour"  Frontradar
 SG_ TSK_Ausrollkurve_Segeln_13 m3 : 28|7@1+ (2,0) [0|252] "Unit_KiloMeterPerHour"  Frontradar
 SG_ TSK_Ausrollkurve_Segeln_17 m4 : 28|7@1+ (2,0) [0|252] "Unit_KiloMeterPerHour"  Frontradar
 SG_ TSK_Ausrollkurve_Segeln_02 m0 : 35|7@1+ (2,0) [0|252] "Unit_KiloMeterPerHour"  Frontradar
 SG_ TSK_Ausrollkurve_Segeln_06 m1 : 35|7@1+ (2,0) [0|252] "Unit_KiloMeterPerHour"  Frontradar
 SG_ TSK_Ausrollkurve_Segeln_10 m2 : 35|7@1+ (2,0) [0|252] "Unit_KiloMeterPerHour"  Frontradar
 SG_ TSK_Ausrollkurve_Segeln_14 m3 : 35|7@1+ (2,0) [0|252] "Unit_KiloMeterPerHour"  Frontradar
 SG_ TSK_Ausrollkurve_Segeln_18 m4 : 35|7@1+ (2,0) [0|252] "Unit_KiloMeterPerHour"  Frontradar
 SG_ TSK_Ausrollkurve_Segeln_03 m0 : 42|7@1+ (2,0) [0|252] "Unit_KiloMeterPerHour"  Frontradar
 SG_ TSK_Ausrollkurve_Segeln_07 m1 : 42|7@1+ (2,0) [0|252] "Unit_KiloMeterPerHour"  Frontradar
 SG_ TSK_Ausrollkurve_Segeln_11 m2 : 42|7@1+ (2,0) [0|252] "Unit_KiloMeterPerHour"  Frontradar
 SG_ TSK_Ausrollkurve_Segeln_15 m3 : 42|7@1+ (2,0) [0|252] "Unit_KiloMeterPerHour"  Frontradar
 SG_ TSK_Ausrollkurve_Segeln_19 m4 : 42|7@1+ (2,0) [0|252] "Unit_KiloMeterPerHour"  Frontradar
 SG_ TSK_Ausrollkurve_Segeln_04 m0 : 49|7@1+ (2,0) [0|252] "Unit_KiloMeterPerHour"  Frontradar
 SG_ TSK_Ausrollkurve_Segeln_08 m1 : 49|7@1+ (2,0) [0|252] "Unit_KiloMeterPerHour"  Frontradar
 SG_ TSK_Ausrollkurve_Segeln_12 m2 : 49|7@1+ (2,0) [0|252] "Unit_KiloMeterPerHour"  Frontradar
 SG_ TSK_Ausrollkurve_Segeln_16 m3 : 49|7@1+ (2,0) [0|252] "Unit_KiloMeterPerHour"  Frontradar
 SG_ TSK_Ausrollkurve_Segeln_20 m4 : 49|7@1+ (2,0) [0|252] "Unit_KiloMeterPerHour"  Frontradar
 SG_ TSK_Ausrollkurve_Mux M : 56|3@1+ (1,0) [0|7] ""  Frontradar
 SG_ TSK_Ausrollkurve_Reku : 59|1@1+ (1,0) [0|1] ""  Frontradar
 SG_ TSK_Ausrollkurve_Schrittweite : 60|1@1+ (1,0) [0|1] ""  Frontradar
 SG_ TSK_Ausrollkurve_Zaehler : 61|2@1+ (1,0) [0|3] ""  Frontradar

BO_ 1716 VIN_01: 8 Vector__XXX
 SG_ VIN_01_MUX M : 0|2@1+ (1,0) [0|3] ""  Frontradar,Frontsensorik
 SG_ KS_Geheimnis_1 m0 : 8|8@1+ (1,0) [0|255] ""  Frontradar
 SG_ VIN_4 m1 : 8|8@1+ (1,0) [0|255] ""  Frontradar,Frontsensorik
 SG_ VIN_11 m2 : 8|8@1+ (1,0) [0|255] ""  Frontradar,Frontsensorik
 SG_ KS_Geheimnis_2 m0 : 16|8@1+ (1,0) [0|255] ""  Frontradar
 SG_ VIN_5 m1 : 16|8@1+ (1,0) [0|255] ""  Frontradar,Frontsensorik
 SG_ VIN_12 m2 : 16|8@1+ (1,0) [0|255] ""  Frontradar,Frontsensorik
 SG_ KS_Geheimnis_3 m0 : 24|8@1+ (1,0) [0|255] ""  Frontradar
 SG_ VIN_6 m1 : 24|8@1+ (1,0) [0|255] ""  Frontradar,Frontsensorik
 SG_ VIN_13 m2 : 24|8@1+ (1,0) [0|255] ""  Frontradar,Frontsensorik
 SG_ KS_Geheimnis_4 m0 : 32|8@1+ (1,0) [0|255] ""  Frontradar
 SG_ VIN_7 m1 : 32|8@1+ (1,0) [0|255] ""  Frontradar,Frontsensorik
 SG_ VIN_14 m2 : 32|8@1+ (1,0) [0|255] ""  Frontradar,Frontsensorik
 SG_ VIN_1 m0 : 40|8@1+ (1,0) [0|255] ""  Frontradar,Frontsensorik
 SG_ VIN_8 m1 : 40|8@1+ (1,0) [0|255] ""  Frontradar,Frontsensorik
 SG_ VIN_15 m2 : 40|8@1+ (1,0) [0|255] ""  Frontradar,Frontsensorik
 SG_ VIN_2 m0 : 48|8@1+ (1,0) [0|255] ""  Frontradar,Frontsensorik
 SG_ VIN_9 m1 : 48|8@1+ (1,0) [0|255] ""  Frontradar,Frontsensorik
 SG_ VIN_16 m2 : 48|8@1+ (1,0) [0|255] ""  Frontradar,Frontsensorik
 SG_ VIN_3 m0 : 56|8@1+ (1,0) [0|255] ""  Frontradar,Frontsensorik
 SG_ VIN_10 m1 : 56|8@1+ (1,0) [0|255] ""  Frontradar,Frontsensorik
 SG_ VIN_17 m2 : 56|8@1+ (1,0) [0|255] ""  Frontradar,Frontsensorik

BO_ 385 VZE_01: 8 Vector__XXX
 SG_ VZE_Anzeigemodus : 0|2@1+ (1,0) [0|3] ""  Frontradar
 SG_ VZE_Hinweistext : 2|3@1+ (1,0) [1|7] ""  Frontradar
 SG_ VZE_Statuszaehler_1 : 5|2@1+ (1,0) [0|3] ""  Frontradar
 SG_ VZE_Statuszaehler_2 : 7|2@1+ (1,0) [0|3] ""  Frontradar
 SG_ VZE_Statuszaehler_3 : 9|2@1+ (1,0) [0|3] ""  Frontradar
 SG_ VZE_Verkehrszeichen_1 : 11|8@1+ (1,0) [1|255] ""  Frontradar
 SG_ VZE_Verkehrszeichen_2 : 19|8@1+ (1,0) [1|255] ""  Frontradar
 SG_ VZE_Verkehrszeichen_3 : 27|8@1+ (1,0) [1|255] ""  Frontradar
 SG_ VZE_Warnung_Verkehrszeichen_1 : 35|1@1+ (1,0) [0|1] ""  Frontradar
 SG_ VZE_Warnung_Verkehrszeichen_2 : 36|1@1+ (1,0) [0|1] ""  Frontradar
 SG_ VZE_Warnung_Verkehrszeichen_3 : 37|1@1+ (1,0) [0|1] ""  Frontradar
 SG_ VZE_Zusatzschild_1 : 38|4@1+ (1,0) [1|15] ""  Frontradar
 SG_ VZE_Zusatzschild_2 : 42|4@1+ (1,0) [1|15] ""  Frontradar
 SG_ VZE_Zusatzschild_3 : 46|4@1+ (1,0) [1|15] ""  Frontradar
 SG_ VZE_Hinweistext_02 : 50|4@1+ (1,0) [1|15] ""  Frontradar

BO_ 668 VZE_02: 8 Vector__XXX
 SG_ VZE_Statuszaehler_4 : 5|2@1+ (1,0) [0|3] ""  Frontradar
 SG_ VZE_Statuszaehler_5 : 7|2@1+ (1,0) [0|3] ""  Frontradar
 SG_ VZE_Zeichen_05_KameraWied : 9|1@1+ (1,0) [0|1] "" Vector__XXX
 SG_ VZE_Zeichen_05_Kamera : 10|1@1+ (1,0) [0|1] "" Vector__XXX
 SG_ VZE_Verkehrszeichen_4 : 11|8@1+ (1,0) [1|255] ""  Frontradar
 SG_ VZE_Verkehrszeichen_5 : 19|8@1+ (1,0) [1|255] ""  Frontradar
 SG_ VZE_Anhaenger_Vmax : 27|4@1+ (10,10) [10|140] "Unit_KiloMeterPerHour" Vector__XXX
 SG_ VZE_Zeichen_04_Gesetz : 31|1@1+ (1,0) [0|1] "" Vector__XXX
 SG_ VZE_Zeichen_04_Kamera : 32|1@1+ (1,0) [0|1] "" Vector__XXX
 SG_ VZE_Zeichen_04_KameraWied : 33|1@1+ (1,0) [0|1] "" Vector__XXX
 SG_ VZE_Zeichen_04_Karte : 34|1@1+ (1,0) [0|1] "" Vector__XXX
 SG_ VZE_Warnung_Verkehrszeichen_4 : 35|1@1+ (1,0) [0|1] ""  Frontradar
 SG_ VZE_Warnung_Verkehrszeichen_5 : 36|1@1+ (1,0) [0|1] ""  Frontradar
 SG_ VZE_Zeichen_05_Gesetz : 37|1@1+ (1,0) [0|1] "" Vector__XXX
 SG_ VZE_Zusatzschild_4 : 38|4@1+ (1,0) [1|15] ""  Frontradar
 SG_ VZE_Zusatzschild_5 : 42|4@1+ (1,0) [1|15] ""  Frontradar
 SG_ VZE_Baustelle : 46|2@1+ (1,0) [0|3] "" Vector__XXX
 SG_ VZE_Zeichen_05_Karte : 48|1@1+ (1,0) [0|1] "" Vector__XXX

CM_ BO_ 930 "Auf diese Botschaft darf bis auf Weiteres keine Botschaftsüberwachung durchgeführt werden (unsicherer Quellbus).";
CM_ SG_ 930 PSD_Multiplex "Identifieziert den Multiplex der Botschaft.";
CM_ SG_ 930 PSD_Sys_Segment_ID "Identifier des prädiktiven Streckensegments ab dem die Systeminformationen gültig sind.
";
CM_ SG_ 930 PSD_Abz_Segment_ID "Identifier des prädiktiven abzweigenden Streckensegments.
";
CM_ SG_ 930 PSD_Ges_Segment_ID "Identifier des prädiktiven Streckensegments ab dem die Geschwindigkeitsbegrenzungen und mögliche Einschränkungen gelten.
";
CM_ SG_ 930 PSD_Ort_Laenge_VZ "Vorzeichen Laengengrad";
CM_ SG_ 930 PSD_Ort_Laenge "Laengengrad in WGS84 aus Koppelnavigation";
CM_ SG_ 930 PSD_Sys_Laendercode "Ländercode
";
CM_ SG_ 930 PSD_Abz_Segmentlaenge "Länge des aktuell übermittelten Streckensegments der Abzweigung.

";
CM_ SG_ 930 PSD_Ges_Geschwindigkeit_Typ "Typ der Geschwindigkeitsbegrenzung";
CM_ SG_ 930 PSD_Ges_Geschwindigkeit_Gespann "Gilt diese Einschränkung der Geschwindigkeit für alle Fahrzeuge oder ausschließlich für PKW mit Gespann oder für LKW, Buss, etc.";
CM_ SG_ 930 PSD_Abz_Vorgaenger_Segment_ID "Identifier des prädiktiven Streckensegments an dessen Ende die Abzweigung angeheftet ist.
";
CM_ SG_ 930 PSD_Sys_Geschwindigkeit_Einheit "Unterscheidung zwischen km/h und miles/h";
CM_ SG_ 930 PSD_Ges_Geschwindigkeit_Witter "Witterungsabhängigkeit der Geschwindigkeitsbegrenzung";
CM_ SG_ 930 PSD_Sys_Verkehrsrichtung "Unterscheidung zwischen Linksverkehr und Rechtsverkehr";
CM_ SG_ 930 PSD_Sys_Release_Monat "Release Datum der Daten DVD: Monat 01¿12";
CM_ SG_ 930 PSD_Ges_Geschwindigkeit_Tag_Anf "Wochentag, an dem die tägliche Geschwindigkeitsbegrenzung beginnt";
CM_ SG_ 930 PSD_Ges_Geschwindigkeit_Tag_Ende "Wochentag, an dem die tägliche Geschwindigkeitsbegrenzung endet";
CM_ SG_ 930 PSD_Sys_Release_Jahr "Release Datum der Daten DVD Jahr 2000 - 2031
";
CM_ SG_ 930 PSD_Ges_Geschwindigkeit_Std_Anf "Stunde, zu der die stündliche Geschwindigkeitsbegrenzung beginnt
0h.. 24h";
CM_ SG_ 930 PSD_Abz_Geschwindigkeit_Typ "Typ der Geschwindigkeitsbegrenzung";
CM_ SG_ 930 PSD_Sys_Tunnel "Tunnel";
CM_ SG_ 930 PSD_Abz_Strassenklasse "Die Klassifizierung des abzweigenden Streckensegments.";
CM_ SG_ 930 PSD_Sys_Bruecke "Bruecke";
CM_ SG_ 930 PSD_Sys_Fahrsp_Gegenr "Fahrspuren in Gegenrichtung";
CM_ SG_ 930 PSD_Abz_ADAS_Qualitaet "ADAS Qualtität des abzweigenden Streckensegments.";
CM_ SG_ 930 PSD_Ges_Geschwindigkeit_Std_Ende "Stunde, an der die stündliche Geschwindigkeitsbegrenzung endet
0h.. 24h";
CM_ SG_ 930 PSD_Ort_Breite "Breitengrad in WGS84 aus Koppelnavigation";
CM_ SG_ 930 PSD_Abz_Abzweigerichtung "Richtung, in die die Abzweigung von der Hauptroute abzweigt.";
CM_ SG_ 930 PSD_Sys_TMC_Baustelle "TMC Signal fuer Baustellenbereich";
CM_ SG_ 930 PSD_Abz_Abzweigewinkel "Winkel, unter dem die Abzweigung von der Hauptroute abzweigt.";
CM_ SG_ 930 PSD_Sys_TMC_Stau "TMC Signal fuer Stauinformation";
CM_ SG_ 930 PSD_Sys_Bauliche_Trennung "Trennung der Spuren in Fahrtrichtung zu den Spuren in Gegenrichtung.";
CM_ SG_ 930 PSD_Sys_Geometrieguete "Maß für die Güte der Klothoidengeometrie.";
CM_ SG_ 930 PSD_Sys_Maut "Erkennen von Mautstellen.";
CM_ SG_ 930 PSD_Abz_Anfangskruemmung "Anfangskrümmung des abzweigenden Streckensegments.
Krümmung = 1/(1+0,155*x²)  [1/m]";
CM_ SG_ 930 PSD_Sys_Strassensituation "Besondere Straßensituationen, wie z.B. Kreisverkehr, Parkbuchten, etc.";
CM_ SG_ 930 PSD_Ges_alter_Geschw_Gespann "Gilt diese alternative Einschränkung der Geschwindigkeit für alle Fahrzeuge oder ausschließlich für PKW mit Gespann oder LKW, Busse, etc. 
0x0 = alle Fahrzeuge
0x1 = PKW mit Gespann
0x2 = LKW, Busse, etc.";
CM_ SG_ 930 PSD_Sys_StrKlassen_erweitert "Differenzierte Strassenklassen Aufteilung";
CM_ SG_ 930 PSD_Ges_alter_Geschw_Witter "Witterungsabhängigkeit der alternativen Geschwindigkeitsbegrenzung.";
CM_ SG_ 930 PSD_Sys_Ortsschild "Ortsschild als Begrenzung von Ortschaften.";
CM_ SG_ 930 PSD_Ges_alter_Geschw_Tag_Anf "Wochentag, an dem die tägliche alternative Geschwindigkeitsbegrenzung beginnt";
CM_ SG_ 930 PSD_Sys_Anfangskruemmung "Anfangskrümmung des entsprechenden Streckensegments.
Krümmung = 1/(1+0,155*x²)  [1/m]

";
CM_ SG_ 930 PSD_Abz_Endkruemmung "Endkrümmung des abzweigenden Streckensegments.
Krümmung = 1/(1+0,155*x²)  [1/m]";
CM_ SG_ 930 PSD_Ges_alter_Geschw_Tag_Ende "Wochentag, an dem die tägliche alternative Geschwindigkeitsbegrenzung endet.";
CM_ SG_ 930 PSD_Ges_alter_Geschw_Std_Anf "Stunde, zu der die stündliche alternative Geschwindigkeitsbegrenzung beginnt
0h.. 24h.";
CM_ SG_ 930 PSD_Ort_Hoehe "Hoehe ueber NN an der";
CM_ SG_ 930 PSD_Ges_alter_Geschw_Std_Ende "Stunde an der die stündliche alternative Geschwindigkeitsbegrenzung endet
0h.. 24h";
CM_ SG_ 930 PSD_Sys_Anfangssteigung "Anfangssteigung des Streckensegments. ";
CM_ SG_ 930 PSD_Abz_Endsteigung "Endsteigung des Streckensegments. ";
CM_ SG_ 930 PSD_Sys_Ortschaft "Die Grenze wird nicht durch das Ortsschild, sondern durch den Beginn der Bebauung markiert.";
CM_ SG_ 930 PSD_Abz_Fahrspuren "Fahrspuren der abzweigenden Strecke in Fahrtrichtung.";
CM_ SG_ 930 PSD_Ges_Wechselverkehrszeichen "Am Beginn des Segments ist ein Wechselverkehrszeichen angebracht.";
CM_ SG_ 930 PSD_Sys_Digitalisierung "Qualität des Kartenmaterials.
In digitalisierten Karten sind sämtliche Straßen erfasst. 
In teildigitalisierten Karten können einzelne Straßen nicht erfasst sein. Dies kann zu Fehlinterpretationen beim MapMatching innerhalb des Navigationssystems führen";
CM_ SG_ 930 PSD_Sys_Zielfuehrung "Zielfuehrung im Navigationssystem. Damit lässt sich der wahrscheinlichste Pfad des Fahrzeuges zuverlässig angeben.";
CM_ SG_ 930 PSD_Abz_wahrscheinlichster_Pfad "Identifiziert den vom Navigationssystem berechneten wahrscheinlichsten Pfad des Fahrzeuges für die abzweigende Strecke.";
CM_ SG_ 1122 PSD_Segment_ID "Identifier des prädiktiven Streckensegments
";
CM_ SG_ 1122 PSD_Vorgaenger_Segment_ID "An dem Streckensegment mit diesem Identifier schließt sich das neue Segment mit der ID 'PSD_01_Segment_ID' an.
";
CM_ SG_ 1122 PSD_Segmentlaenge "Gesamtlänge des prädiktiven Streckensegments";
CM_ SG_ 1122 PSD_Strassenkategorie "Klassifizierung der Straße des beschriebenen Segments
";
CM_ SG_ 1122 PSD_Endkruemmung "'Endkrümmung der Klotoide des übermittelten Streckensegments. Die Anfangskrümmung des folgenden Streckensegments entspricht der Endkrümmung dieses Segments. Krümmung = 1/(1+0.155 * x²) [1/m]

";
CM_ SG_ 1122 PSD_Idenditaets_ID "Identifier auf ein Streckensegment, dass mit dem aktuell übertragenen geometrisch identisch ist.";
CM_ SG_ 1122 PSD_ADAS_Qualitaet "ADAS Qualtität des Streckensegments.";
CM_ SG_ 1122 PSD_wahrscheinlichster_Pfad "Identifiziert den vom Navigationssystem berechneten wahrscheinlichsten Pfad des Fahrzeuges. ";
CM_ SG_ 1122 PSD_Geradester_Pfad "Segment ist Teil des geradesten Pfades";
CM_ SG_ 1122 PSD_Fahrspuren_Anzahl "Anzahl der Fahrspuren in Fahrtrichtung
";
CM_ SG_ 1122 PSD_Bebauung "Segement befindet sich innerhalb bebauten Gebietes";
CM_ SG_ 1122 PSD_Segment_Komplett "Zeigt, ob alle Attribute für das Segment übertragen worden sind
";
CM_ SG_ 1122 PSD_Anfangskruemmung "Startkrümmung der Klothoide des übermittelten abzweigenden Streckensegments. 
1/(1+0.155 * x^2) {1/m}'
";
CM_ SG_ 1122 PSD_Anfangskruemmung_Vorz "Vorzeichen für die Startkrümmung bei Abzweigungen
";
CM_ SG_ 1122 PSD_Abzweigerichtung "Richtung, in der die Abzweigung von der Hauptroute abzweigt
";
CM_ SG_ 1122 PSD_Abzweigewinkel "Winkel, unter dem die Abzweigung von der Hauptroute abzweigt.
";
CM_ SG_ 1123 PSD_Pos_Segment_ID "Identifier des Streckensegments, auf dem sich das Fahrzeug aktuell befindet
";
CM_ SG_ 1123 PSD_Pos_Segmentlaenge "Verbleibende Länge des Streckensegments, auf dem sich das Fahrzeug aktuell befindet
";
CM_ SG_ 1123 PSD_Pos_Inhibitzeit "Zeitspanne zwischen Generierung der PSD Daten im Navigationssystem und Versand der Daten auf den Most
";
CM_ SG_ 1123 PSD_Pos_Standort_Eindeutig "Ist die Position des Fahrzeugs eindeutig dem aktuelle Segment zugeordnet, oder gibt es fahrbare alternative Segmente, die bei akteller GPS-Position ebenfalls als aktuelles Segment möglich wären.";
CM_ SG_ 1123 PSD_Pos_Fehler_Laengsrichtung "Laengsfehler der Positionierung";
CM_ SG_ 1123 PSD_Pos_Fahrspur "Spur, auf der sich das Fahrzeug aktuell befindet";
CM_ SG_ 1123 PSD_Attribut_Segment_ID_05 "Identifier des Streckensegments, für das die weiteren Attribute in der Botschaft gültig sind";
CM_ SG_ 1123 PSD_Attribut_1_ID "Identifier des ersten Attributes";
CM_ SG_ 1123 PSD_Attribut_1_Wert "Wert des ersten Attributes";
CM_ SG_ 1123 PSD_Attribut_1_Offset "Positionsoffset im Segment für die Position des Attributs";
CM_ SG_ 1123 PSD_Attribut_2_ID "Identifier des zweiten Attributes";
CM_ SG_ 1123 PSD_Attribut_2_Wert "Wert des zweiten Attributes";
CM_ SG_ 1123 PSD_Attribut_2_Offset "Positionsoffset im Segment für die Position des Attributs";
CM_ SG_ 1123 PSD_Attribute_Komplett_05 "Zeigt, ob alle Attribute für das Segment übertragen worden sind";
CM_ SG_ 1124 PSD_06_Mux "Multiplex Zähler für die PSD_06-Botschaft";
CM_ SG_ 1124 PSD_Sys_Segment_ID "Identifier des prädiktiven Streckensegments ab dem die Systeminformationen gültig sind.
";
CM_ SG_ 1124 PSD_Attribut_Segment_ID "Identifier des Streckensegments,für das die weiteren Attribute in der Botschaft gültig sind";
CM_ SG_ 1124 PSD_Ges_Segment_ID "Identifier des prädiktiven Streckensegments ab dem die Geschwindigkeitsbegrenzungen und mögliche Einschränkungen gelten.
";
CM_ SG_ 1124 PSD_Baum_Laenge_VZ "Vorzeichen WGS84 Laenge des Fahrzeugsegments";
CM_ SG_ 1124 PSD_Steigung_1_Segment_ID "Identifier des prädiktiven Streckensegments, zu dem die  ersten beiden Steigungswerte dieser Botschaft gehören";
CM_ SG_ 1124 PSD_Baum_Laenge "WGS84 Laenge des Fahrzeugsegments";
CM_ SG_ 1124 PSD_Sys_Laendercode "Ländercode
";
CM_ SG_ 1124 PSD_Attribut_3_ID "Identifier des dritten Attributes";
CM_ SG_ 1124 PSD_Ges_Offset "Positionsoffset im Segment für die Position des Attributs";
CM_ SG_ 1124 PSD_Steigung_1_A_Steigung "Steigung des Segments ab Offset 1A";
CM_ SG_ 1124 PSD_Attribut_3_Offset "Positionsoffset im Segment für die Position des Attributs";
CM_ SG_ 1124 PSD_Steigung_1_A_Vorz "Vorzeichen für Steigung 1 A";
CM_ SG_ 1124 PSD_Sys_Geschwindigkeit_Einheit "Unterscheidung zwischen km/h und miles/h";
CM_ SG_ 1124 PSD_Steigung_1_A_Offset "Positionsoffset im Segment für die Position der Steigung 1 A";
CM_ SG_ 1124 PSD_Sys_Verkehrsrichtung "Unterscheidung zwischen Linksverkehr und Rechtsverkehr";
CM_ SG_ 1124 PSD_Sys_Geometrieguete "Maß für die Güte der Klothoidengeometrie.";
CM_ SG_ 1124 PSD_Sys_Mapmatchingguete "Güte des Mapmatchings";
CM_ SG_ 1124 PSD_Attribut_3_Wert "Wert des dritten Attributes";
CM_ SG_ 1124 PSD_Ges_Typ "Typ der Geschwindigkeitsbegrenzung
";
CM_ SG_ 1124 PSD_Sys_Alter_Karte "Alter der Karte";
CM_ SG_ 1124 PSD_Ges_Spur_Geschw_Begrenzung "Definition der Spuren, für die das übertragene Gebot gilt";
CM_ SG_ 1124 PSD_Steigung_1_B_Steigung "Steigung des Segments ab Offset 1B";
CM_ SG_ 1124 PSD_Attribut_4_ID "Typ von Attribut 4";
CM_ SG_ 1124 PSD_Sys_Zielfuehrung "Zielfuehrung im Navigationssystem. Damit lässt sich der wahrscheinlichste Pfad des Fahrzeuges zuverlässig angeben.";
CM_ SG_ 1124 PSD_Sys_US_State "Name des USA-State";
CM_ SG_ 1124 PSD_Ges_Geschwindigkeit_Gespann "Gilt diese Einschränkung der Geschwindigkeit für alle Fahrzeuge oder ausschließlich für PKW mit Gespann oder für LKW, Buss, etc.";
CM_ SG_ 1124 PSD_Baum_Breite_VZ "Vorzeichen WGS84 Breite des Fahrzeugsegments";
CM_ SG_ 1124 PSD_Attribut_4_Wert "Wert von Attribut 4";
CM_ SG_ 1124 PSD_Baum_Breite "WGS84 Breite des Fahrzeugsegments";
CM_ SG_ 1124 PSD_Ges_Geschwindigkeit_Witter "Witterungsabhängigkeit der Geschwindigkeitsbegrenzung";
CM_ SG_ 1124 PSD_Steigung_1_B_Vorz "Vorzeichen für Steigung 1 B";
CM_ SG_ 1124 PSD_Steigung_1_B_Offset "Positionsoffset im Segment für die Position der Steigung 1 B";
CM_ SG_ 1124 PSD_Ges_Geschwindigkeit_Tag_Anf "Wochentag, an dem die tägliche Geschwindigkeitsbegrenzung beginnt";
CM_ SG_ 1124 PSD_Attribut_4_Offset "Offset von Attribut 4";
CM_ SG_ 1124 PSD_Ges_Geschwindigkeit_Tag_Ende "Wochentag, an dem die tägliche Geschwindigkeitsbegrenzung endet";
CM_ SG_ 1124 PSD_Ges_Geschwindigkeit_Std_Anf "Stunde, zu der die stündliche Geschwindigkeitsbegrenzung beginnt
0h.. 24h";
CM_ SG_ 1124 PSD_Steigung_1_Attribute_kompl "Alle Steigungsdaten für dieses Segment gesendet";
CM_ SG_ 1124 PSD_Steigung_2_Segment_ID "Identifier des prädiktiven Streckensegments, zu dem der dritte Steigungswert dieser Botschaft gehört";
CM_ SG_ 1124 PSD_Attribut_5_ID "Typ von Attribut 5";
CM_ SG_ 1124 PSD_Ges_Geschwindigkeit_Std_Ende "Stunde, an der die stündliche Geschwindigkeitsbegrenzung endet
0h.. 24h";
CM_ SG_ 1124 PSD_Attribut_5_Offset "Offset von Attribut 5";
CM_ SG_ 1124 PSD_Steigung_2_Steigung "Steigung des Segments ab Offset 2";
CM_ SG_ 1124 PSD_Ges_Wechselverkehrszeichen "Am Beginn des Segments ist ein Wechselverkehrszeichen angebracht.";
CM_ SG_ 1124 PSD_Attribut_5_Wert "Wert von Attribut 5";
CM_ SG_ 1124 PSD_Steigung_2_Vorz "Vorzeichen für Steigung 2";
CM_ SG_ 1124 PSD_Wechselverkehrszeichen_Typ "Typ des Wechselverkehrszeichen";
CM_ SG_ 1124 PSD_Baum_Ausrichtung "Ausrichtung des Fahrzeugsegments zu Nord";
CM_ SG_ 1124 PSD_Steigung_2_Offset "Positionsoffset im Segment für die Position der Steigung 2";
CM_ SG_ 1124 PSD_Ges_Gesetzlich_Kategorie "Kategorie für das legale Gebot";
CM_ SG_ 1124 PSD_Attribute_Komplett_06 "Zeigt, ob alle Attribute für das Segment übertragen worden sind
";
CM_ SG_ 1124 PSD_Ges_Gesetzlich_Zusatz "Zusatz für das legale Gebot";
CM_ SG_ 1124 PSD_Ges_Verkehrszeichen_Quelle "Quelle der Verkehrszeicheninformation";
CM_ SG_ 1124 PSD_Steigung_2_Attribute_kompl "Alle Steigungsdaten für dieses Segment gesendet";
CM_ SG_ 1124 PSD_Ges_Attribute_Komplett "Zeigt, ob alle Attribute für das Segment übertragen worden sind";
CM_ BO_ 695 "Rear Cross Traffic Assist";
CM_ SG_ 695 RCTA_01_CRC "Für MLB:
'Berechnung siehe Lastenheft 'Kommunikationsabsicherung für FlexRay und CAN''

Ab MQB und MLBevo:
'Berechnung siehe Lastenheft 'End-to-End Kommunikationsabsicherung''

Endwerte siehe Begleitdokument 'S-PDU Kennungsfolgen'";
CM_ SG_ 695 RCTA_01_BZ "4bit-Botschaftszaehler, wird in jeder Sendebotschaft inkrementiert";
CM_ SG_ 695 RCTA_Info_rechts "Das alte RCTA_Info wird aufgeteilt in RCTA_Info_links und RCTA_Info_rechts. Damit sollen Richtungsblinken oder ähnliches aufgrund der RCTA-Funtkion möglich gemacht werden.

Dieser Parameter ist eine zusätzliche Information zu RCTA. Andere Systeme können";
CM_ SG_ 695 RCTA_Anforderung_HMS "Nach einer Notbremsung durch RCTA muss das Fahrzeug halten. Deshalb ist eine HMS-Anforderung mit der Notbremsung erforderlich.";
CM_ SG_ 695 RCTA_Bremsruck_Anforderung "RCTA_Bremsruck_Anforderung  ist die Anforderung an das Bremssystem einen kurzen Bremsruck auszuführen. Mit dem Signal 'RCTA_Bremsruck_Freigabe' zusammen wird der Ruck ausgeführt. Dadurch soll der Fahrer auf eine mögliche Kollision hingewiesen und zum Brem";
CM_ SG_ 695 RCTA_Bremsruck_Freigabe "RCTA_Bremsruck_Freigabe ist die eigentliche Auforderung (mit dem Signal 'RCTA_Bremsruck_Anforderung') an das Bremssystem einen kurzen Bremsruck auszuführen. Dadurch soll der Fahrer auf eine mögliche Kollision hingewiesen und zum Bremsen animiert werden.";
CM_ SG_ 695 RCTA_Info_links "Das alte RCTA_Info wird aufgeteilt in RCTA_Info_links und RCTA_Info_rechts. Damit sollen Richtungsblinken oder ähnliches aufgrund der RCTA-Funtkion möglich gemacht werden.

Dieser Parameter ist eine zusätzliche Information zu RCTA. Andere Systeme können";
CM_ SG_ 695 RCTA_Status "RCTA_Status ist die Rückmeldung, ob das System überhaupt aktiv ist. Mögliche Zustände sind: Das System ist aus; Das System ist nur passiv (läuft, ist aber ohne Funktionalität); Das System ist aktiv; Das System ist fehlerhaft";
CM_ SG_ 695 RCTA_Warnton "Ansteuerung APS Tongeber für  Warnton von RCTA. (Dauerton)";
CM_ SG_ 695 RCTA_Notbremsung_Freigabe "RCTA_Notbremsung_Freigabe ist die eigentliche Auforderung (mit dem Signal 'Notbremsung_Anforderung_Wert') an das Bremssystem eine Notfallbremsung einzuleiten. Dadurch sollen größere Schäden am Fahrzeug vermieden werden.";
CM_ SG_ 695 RCTA_Notbremsung_Anforderung "RCTA_Notbremsung_Anforderung  ist die Anforderung der Funktion RCTA an das Bremssystem. Mit dem Signal 'Notbremsung_Freigabe' zusammen wird die Bremsung eingeleitet. Dadurch sollen größere Schäden am Fahrzeug verhindert werden.";
CM_ BO_ 1440 "LIN-CAN (1:1) Botschaften werden geroutet
-  wenn entsprechender Slave codiert ist
-  wenn fehlerfreie Kommunikation zum Slave besteht
-  bei fehlerhafter Kommunikation zum Slave wird die Botschaft für 4s mit den letzten gültigen Werten versendet

";
CM_ SG_ 1440 LS_defekt "Fehlererkennung Lichtsensor
";
CM_ SG_ 1440 LS_Verbau "Verbauinfo Lichtsensor
";
CM_ SG_ 1440 RS_Regenmenge "Regenmenge für intel. Heckleuchte ";
CM_ SG_ 1440 RS_Verbau "Verbauinfo Regensensor";
CM_ SG_ 1440 RS_Verglasung_schliessen "Anforderung: Verglasung schliessen
";
CM_ SG_ 1440 RS_defekt "Fehlererkennung Regensensor";
CM_ SG_ 1440 RS_Wischergeschwindigkeit "Wischergeschwindigkeit (Hübe/min)";
CM_ SG_ 1440 RLS_Vorfeldhelligkeit_Boost "erweiterte Helligkeitssensierung für HUD";
CM_ SG_ 684 SDF_PSF_01_CRC "Für MLB:
'Berechnung siehe Lastenheft 'Kommunikationsabsicherung für FlexRay und CAN''

Ab MQB und MLBevo:
'Berechnung siehe Lastenheft 'End-to-End Kommunikationsabsicherung''

Endwerte siehe Begleitdokument 'S-PDU Kennungsfolgen'";
CM_ SG_ 684 SDF_PSF_Objektstatus "Objektstatus";
CM_ SG_ 684 SDF_PSF_Fahrer_aktiv "Fahreraktivität";
CM_ SG_ 684 SDF_PSF_Time_To_Collision "Zeit bis zur Kollision";
CM_ SG_ 684 SDF_PSF_v_rel "Prädizierte Aufprallgeschwindigkeit";
CM_ SG_ 684 SDF_PSF_Kollisionsueberdeckung "Kollisionsueberdeckung in y-Richtung";
CM_ SG_ 684 SDF_PSF_01_Sendestatus "Gibt den Sendestatus der Botschaft SDF_PSF_01 an (notwendig für IL-Unterstützung)";
CM_ SG_ 684 SDF_PSF_CU_Status "Kollisionsvermeidbarkeit";
CM_ SG_ 684 SDF_PSF_CW "Kollisionswahrscheinlichkeit";
CM_ SG_ 684 SDF_PSF_Guete "Guete des Objektes";
CM_ BO_ 783 "ab MQB mit CRC-8";
CM_ SG_ 783 SWA_01_CRC "Für MLB:
'Berechnung siehe Lastenheft 'Kommunikationsabsicherung für FlexRay und CAN''

Ab MQB und MLBevo:
'Berechnung siehe Lastenheft 'End-to-End Kommunikationsabsicherung''

Endwerte siehe Begleitdokument 'S-PDU Kennungsfolgen'";
CM_ SG_ 783 SWA_01_BZ "Fehlende Beschreibung (Import)";
CM_ SG_ 783 SWA_Anzeigen "SWA- Texte und -Akustik zur Anzeige im Kombiinstrument
0x5-0xF = reserviert
";
CM_ SG_ 783 SWA_Blindheit_erkannt "SWA erkennt selbständig eigene Blindheit durch äußere Einflüsse.";
CM_ SG_ 783 SWA_rel_Nichtverf "SWA erkennt eine Nichtverfuegbarkeit, die Objektdetektion betreffend, ohne FSP-Eintrag";
CM_ SG_ 783 SWA_rel_Fehler "SWA erkennt einen Fehler, die Objektdetektion betreffend, mit FSP-Eintrag.";
CM_ SG_ 783 SWA_Sta_aktiv "SWA Status aktiv; Lampenansteuerung im Kombi";
CM_ SG_ 783 SWA_Sta_passiv "SWA Status passiv; Lampenansteuerung im Kombi";
CM_ SG_ 783 SWA_FT_RueckLED "SWA/ASW Rückmelde-LED. Zeigt den Aktivierungszustand der Funktionen SWA/ASW";
CM_ SG_ 783 ASW_Status "Funktionsstatus Ausstiegswarnung (ASW)";
CM_ SG_ 783 SWA_Standziele_li "Abstand zwischen Fahrzeug und Standziele links geringer als ein applizierbarer Wert.";
CM_ SG_ 783 SWA_Kolonne_li "Info, dass auf der entspr. Spur mehr als zwei Fahrzeuge zu finden sind. ";
CM_ SG_ 783 SWA_Infostufe_SWA_li "Aktion der SWA-Funktion auf der entsprechenden Fahrzeugseite";
CM_ SG_ 783 SWA_Warnung_SWA_li "Aktion der SWA-Funktion auf der entsprechenden Fahrzeugseite";
CM_ SG_ 783 ASW_Warnung_FS "Modus Beifahrerseite der Funktion Ausstiegswarnung (ASW)";
CM_ SG_ 783 ASW_Warnung_BFS "Modus Beifahrerseite der Funktion Ausstiegswarnung (ASW)";
CM_ SG_ 783 ASW_Kombitexte "ASW_Kombitexte bestimmt welcher Text im Kombi angezeigt wird. Darüber hinaus werden auch Kombi-Akkustik durch dieses Signal ausgelöst.

Dieses Signal ersetzt SWA_Anzeigen für den ASW-Anteil. Der SWA-Anteil des alten Signals findet sich in SWA-Kombitexte";
CM_ SG_ 783 SWA_Kolonne_mi "Info, dass auf der entspr. Spur mehr als zwei Fahrzeuge zu finden sind. ";
CM_ SG_ 783 SWA_Standziele_re "Abstand zwischen Fahrzeug und Standziele links geringer als ein applizierbarer Wert.";
CM_ SG_ 783 SWA_Kolonne_re "Info, dass auf der entspr. Spur mehr als zwei Fahrzeuge zu finden sind. ";
CM_ SG_ 783 SWA_Infostufe_SWA_re "Aktion der SWA-Funktion auf der entsprechenden Fahrzeugseite";
CM_ SG_ 783 SWA_Warnung_SWA_re "Aktion der SWA-Funktion auf der entsprechenden Fahrzeugseite";
CM_ SG_ 783 HRE_Anzeigetexte "HRE-Texte und -Akustik zur Anzeige im Kombiinstrument

0x9  - 0xF = reserviert";
CM_ SG_ 783 SWA_Gischtzaehler "Zähler, der die eigene Gischt bei nasser Fahrbahn misst (Kennwert)";
CM_ SG_ 783 Heckradar_Kombitexte "Heckradar_Kombitexte bestimmt welcher Text im Kombi angezeigt wird. Darüber hinaus werden auch Kombi-Akkustik durch dieses Signal ausgelöst.

Dieses Signal ersetzt SWA_Anzeigen und deckt alle Kombinationsmöglichkeiten der Heckradarfunktionen ab. Die Fun";
CM_ SG_ 783 RCTA_Kombitexte "RCTA_Kombitexte bestimmt welcher Text im Kombi angezeigt wird. Darüber hinaus werden auch Kombi-Akkustik durch dieses Signal ausgelöst.

0x7 =  reserviert";
CM_ BO_ 1413 "MQB, MLBevo";
CM_ SG_ 1413 SI_Sammel_SG_Fehler "Anzahl der gesetzten KD-Fehler direkt angeschlossener Steuergeräte der DK3 und DK4 gemäß 80127.
Hinweis: Ein Subbusmaster stellt nur die gesammelte Information der an ihn angeschlossenen Steuergeräte der DK3 und DK4 zur Verfügung.

Für ServiceKey Auswe";
CM_ SG_ 1413 SI_Diagnose_Aktiv "Gibt an ob Diagnose-Botschaften empfangen werden und somit eine Diagnose aktiv ist";
CM_ SG_ 1413 SI_T_Mode "0x0: Transportmodus nicht aktiv
0x1: Transportmodus aktiv";
CM_ SG_ 1413 SI_NWDF "Netzwerk-Diagnose Freigebe zur zentralen Aktivierung der Netzwerkdiagnose";
CM_ SG_ 1413 SI_NWDF_gueltig "Gültigkeitsbit zu SI_NWDF gemäß Lastenheft: Zentrale Aktivierung Netzwerkdiagnose";
CM_ SG_ 1413 SI_Sammelfehler "Sammelfehlermeldung zur Anzeige im Kombi - siehe Spez. Sammelfehlermeldung
Hinweis: Einzelne Steuergeräte können zur Anpassung an den Produktionsprozess im Gateway auskodiert werden!";
CM_ SG_ 1413 GW_KD_Fehler "Kundendienstfehlerbit Gateway zur Anzeige eines im Gateway abgelegten Fehlerspeichereintrages.";
CM_ SG_ 1413 SI_T_Schutz "Transportschutz-Signal, das bei Transportmodus und Motorlauf aktiv bleibt
0x0: Transportschutz nicht aktiv
0x1: Transportschutz aktiv";
CM_ SG_ 1413 SI_BUS_01 "MQB/PQ26: ACAN
MLBevo: HCAN";
CM_ SG_ 1413 SI_BUS_02 "MQB: FCAN
MLBevo: Frei";
CM_ SG_ 1413 SI_BUS_03 "MQB/PQ26: KCAN
MLBevo: KCAN";
CM_ SG_ 1413 SI_BUS_04 "MQB: ICAN
MLBevo: ICAN";
CM_ SG_ 1413 SI_BUS_05 "MQB/PQ26: DiagCAN
MLBevo: DiagCAN";
CM_ SG_ 1413 SI_BUS_06 "MQB/PQ26: ECAN
MLBevo: ECAN";
CM_ SG_ 1413 SI_BUS_07 "MQB: LIN1 (Energie)
MLBevo: LIN1 (Energie)";
CM_ SG_ 1413 SI_BUS_08 "MQB: LIN2 (MFL)
MLBevo: LIN2 (MFL)";
CM_ SG_ 1413 SI_BUS_09 "MQB: LIN3 (unbelegt)
MLBevo: LIN3 (Energie2)";
CM_ SG_ 1413 SI_BUS_10 "MLBevo: Flexray";
CM_ SG_ 1413 SI_BUS_11 "MLBevo: Ethernet";
CM_ SG_ 1413 SI_BUS_12 "MQB: unbelegt
MLBevo: K2CAN";
CM_ SG_ 1413 SI_BUS_13 "MQB: unbelegt
MLBevo: DCAN";
CM_ SG_ 1413 SI_Bus_Identifikation "Das Signal identifiziert den Bus eindeutig. Das Signal ist konstant auf jedem Bus.
Der Signalwert entspricht dem Wert 'Busnummer' aus der VW80127 Gateway_component_list_databus_identification (0x2A2D) 'Bus-Identifier'.";
CM_ SG_ 997 TSG_FT_02_CRC "Für MLB:
'Berechnung siehe Lastenheft 'Kommunikationsabsicherung für FlexRay und CAN''

Ab MQB und MLBevo:
'Berechnung siehe Lastenheft 'End-to-End Kommunikationsabsicherung''

Endwerte siehe Begleitdokument 'S-PDU Kennungsfolgen'";
CM_ SG_ 997 TSG_FT_02_BZ "4bit Botschaftszaehler, wird mit jeder Sendebotschaft inkrementiert";
CM_ SG_ 997 FT_Tuer_Status "Tür geöffnet oder Tür geschlossen";
CM_ SG_ 997 FT_Tuer_Status_QBit "Dieses Bit gibt die Zuverlässigkeit des Türkontakts an.";
CM_ SG_ 997 FT_Lock_Taster_02 "Lock-Taster betätigt";
CM_ SG_ 997 FT_Schluesselschalter_zu_02 "Schlüsselschalter für Schließen betätigt";
CM_ SG_ 997 FT_BFS_Tuer_Status "Gesammelte Türstatusbotschaft";
CM_ SG_ 997 FT_HBFS_Tuer_Status "Türstatus mit Fehler und Initwert";
CM_ SG_ 997 FT_HFS_Tuer_Status "Türstatus mit Fehler und Initwert";
CM_ SG_ 997 FT_Tuerschloss_verrieg_nicht "Die Fahrertür kann nicht verriegelt werden.";
CM_ SG_ 997 FT_SP_Heizung_ein "Dieses Signal zeigt die tatsächliche Ansteuerung der  Spiegelheizung incl. PWM an. 
Zudem wird aufgrund des Teilnetzbetriebs das Signal zur Ansteuerung der Beifahrer-Spiegelheizung benutzt.

";
CM_ SG_ 997 FT_Kisi_Taster_li_02 "Der Kindersicherungstaster hinten links aktiv.";
CM_ SG_ 997 FT_Kisi_Taster_re_02 "Der Kindersicherungstaster hinten rechts aktiv.";
CM_ SG_ 997 FT_TD_Taste_Status "Status Taste für Tankdeckel";
CM_ BO_ 288 "Vorschlag TSK-Schnittstelle MQB";
CM_ SG_ 288 TSK_06_CRC "Für MLB:
'Berechnung siehe Lastenheft 'Kommunikationsabsicherung für FlexRay und CAN''

Ab MQB und MLBevo:
'Berechnung siehe Lastenheft 'End-to-End Kommunikationsabsicherung''

Endwerte siehe Begleitdokument 'S-PDU Kennungsfolgen'";
CM_ SG_ 288 TSK_Radbremsmom "Bei der Schnittstelle vom TSK zum ESP soll in Folgeprojekten des B8 und insbesondere bei VW-Projekten die Ansteuerung der Bremse nicht über Sollbeschleunigung sondern Bremsmoment erfolgen.  Es handelt sich genauer um das Summenradbremsmoment, welches die ";
CM_ SG_ 288 TSK_Status "Betriebszustand des TSK-Reglers";
CM_ SG_ 288 TSK_v_Begrenzung_aktiv "Limiter oder HGB begrenzen die Beschleunigung/das Moment";
CM_ SG_ 288 TSK_Standby_Anf_ESP "Mit diesem Bit wird das aktive Bremssystem auf eine anstehende TSK-Verzögerungsanforderung vorbereitet (Überfahren Leerweg, Anlegen Bremsbeläge)";
CM_ SG_ 288 TSK_Freig_WU "Freigabe des TSK_Übersetzungswunsches bei ACC/GRA Betrieb bergab für die Verstellung nach kurz bzw. Rückschaltung im Getriebe.";
CM_ SG_ 288 TSK_Freig_Verzoeg_Anf "Freigabe der Verzögerungsanforderung der ACC oder ggf. GRA+ Funktion für ECD Regelung im ESP";
CM_ SG_ 288 TSK_Limiter_ausgewaehlt "ACC/GRA-Betrieb nur bei nicht ausgewähltem Limiter möglich";
CM_ SG_ 288 TSK_Wunsch_Uebersetz "Bei ACC/GRA Betrieb bergab teilt der TSK dem Getriebe mit, dass eine Drehzahlerhöhung erwünscht ist, um mehr Schleppmoment und damit verbunden die nötige Verzögerung zu erzeugen, um die Geschwindigkeit konstant zu halten. 

Nutzung im VL: das Getriebe v";
CM_ SG_ 288 TSK_Hauptschalter_GRA_ACC "Stellung des GRA/ACC Hauptschalters. Das Signal wird auch bei Fehlerabschaltungen von GRA/ACC weiterhin bedient und ermöglicht für ACC die Steuerung der ACC-Anzeige auch in Fehlerfällen.";
CM_ SG_ 288 TSK_ax_Getriebe_02 "Beschleunigungsanforderung des Beschleunigungsreglers (u. a. für ACC, GRA, Speed Limiter). Das Signal wird vom Getriebe benutzt, um die von GRA/ACC geforderte Sollbeschleunigung in dem verbrauchsgünstigsten Gang einzustellen.
MQB: Im MQB wird die Sollbes";
CM_ SG_ 288 TSK_Zwangszusch_ESP "Mit diesem Bit wird das ESP/ASR zwangsweise aktiviert. Bei gesetztem Bit ist ein ausgetastetes ESP (oder ASR) wieder aktiviert bzw. wird die Austastung verhindert.";
CM_ SG_ 288 TSK_zul_Regelabw "Anforderung der zulässigen Regelabweichung vom Triebstrangkoordinator. Zulässiger Betrag der Abweichung zwischen angeforderter 'TSK_Sollbeschleunigung_Getriebe' und umzusetzender Sollbeschleunigung  im Getriebe. Im TSK wird, abhängig vom Arbeitspunkt die ";
CM_ SG_ 346 TSK_08_CRC "Für MLB:
'Berechnung siehe Lastenheft 'Kommunikationsabsicherung für FlexRay und CAN''

Ab MQB und MLBevo:
'Berechnung siehe Lastenheft 'End-to-End Kommunikationsabsicherung''

Endwerte siehe Begleitdokument 'S-PDU Kennungsfolgen'";
CM_ SG_ 346 MO_Anforderung_HMS "Halteanforderung vom Motor an HMS";
CM_ SG_ 346 TSK_Status_EA "Funktionsstatus des Triebstrangkoordinators für den Anforderer Emergency Assist";
CM_ SG_ 346 TSK_vMax_Fahrerassistenz "maximale Sollgeschwindigkeit für GRA/ACC/Limiter
Hinweis: Signal ist mit Signal TSK_Einheit_vMax_Fahrerassistenz zu interpretieren.  Das Signal wird abwechselnd in km/h und mph gesendet.";
CM_ SG_ 346 TSK_Einheit_vMax_Fahrerassistenz "Einheit zu Signal TSK_vMax_Fahrerassistenz";
CM_ SG_ 346 TSK_Status_PLA "Funktionsstatus des Triebstrangkoordinators für den Speedlimiter des Parkassistenten";
CM_ SG_ 346 TSK_aktives_System "Anzeige der in der TSK-Längsführung aktiven Funktion";
CM_ SG_ 346 TSK_erhoehter_Fahrwiderstand "Rückmeldung vom Triebstrangkoordinator, dass eine große Reglerdifferenz detektiert wurde. Soll ermöglichen, einen ggfs. unbekannten Fahrwiderstand am Boden zu erkennen.";
CM_ SG_ 346 TSK_Anf_Antriebsmoment "Das Signal zeigt an, ob die TSK-Längsregelung aktuell Antriebsmoment anfordert, zur Verwendung in der ASR/EDS-Funktion";
CM_ SG_ 346 TSK_Status_ARA "Funktionsstatus des Triebstrangkoordinators für den Anhängerrangierassistenten";
CM_ SG_ 346 TSK_Status_IPA "Funktionsstatus des Triebstrangkoordinators für die Längsführung des Einparkassistenten";
CM_ SG_ 1019 TSK_Ausrollkurve_Schub_Reku_01 "Dieses Signal sendet die Stützstelle 1 der Schub-/Rekuausrollkurve.";
CM_ SG_ 1019 TSK_Ausrollkurve_Schub_Reku_05 "Dieses Signal sendet die Stützstelle 5 der Schub-/Rekuausrollkurve.";
CM_ SG_ 1019 TSK_Ausrollkurve_Schub_Reku_09 "Dieses Signal sendet die Stützstelle 9 der Schub-/Rekuausrollkurve.";
CM_ SG_ 1019 TSK_Ausrollkurve_Schub_Reku_13 "Dieses Signal sendet die Stützstelle 13 der Schub-/Rekuausrollkurve.";
CM_ SG_ 1019 TSK_Ausrollkurve_Schub_Reku_17 "Dieses Signal sendet die Stützstelle 17 der Schub-/Rekuausrollkurve.";
CM_ SG_ 1019 TSK_Ausrollkurve_Schub_Reku_02 "Dieses Signal sendet die Stützstelle 2 der Schub-/Rekuausrollkurve.";
CM_ SG_ 1019 TSK_Ausrollkurve_Schub_Reku_06 "Dieses Signal sendet die Stützstelle 6 der Schub-/Rekuausrollkurve.";
CM_ SG_ 1019 TSK_Ausrollkurve_Schub_Reku_10 "Dieses Signal sendet die Stützstelle 10 der Schub-/Rekuausrollkurve.";
CM_ SG_ 1019 TSK_Ausrollkurve_Schub_Reku_14 "Dieses Signal sendet die Stützstelle 14 der Schub-/Rekuausrollkurve.";
CM_ SG_ 1019 TSK_Ausrollkurve_Schub_Reku_18 "Dieses Signal sendet die Stützstelle 18 der Schub-/Rekuausrollkurve.";
CM_ SG_ 1019 TSK_Ausrollkurve_Schub_Reku_03 "Dieses Signal sendet die Stützstelle 3 der Schub-/Rekuausrollkurve.";
CM_ SG_ 1019 TSK_Ausrollkurve_Schub_Reku_07 "Dieses Signal sendet die Stützstelle 7 der Schub-/Rekuausrollkurve.";
CM_ SG_ 1019 TSK_Ausrollkurve_Schub_Reku_11 "Dieses Signal sendet die Stützstelle 11 der Schub-/Rekuausrollkurve.";
CM_ SG_ 1019 TSK_Ausrollkurve_Schub_Reku_15 "Dieses Signal sendet die Stützstelle 15 der Schub-/Rekuausrollkurve.";
CM_ SG_ 1019 TSK_Ausrollkurve_Schub_Reku_19 "Dieses Signal sendet die Stützstelle 19 der Schub-/Rekuausrollkurve.";
CM_ SG_ 1019 TSK_Ausrollkurve_Schub_Reku_04 "Dieses Signal sendet die Stützstelle 4 der Schub-/Rekuausrollkurve.";
CM_ SG_ 1019 TSK_Ausrollkurve_Schub_Reku_08 "Dieses Signal sendet die Stützstelle 8 der Schub-/Rekuausrollkurve.";
CM_ SG_ 1019 TSK_Ausrollkurve_Schub_Reku_12 "Dieses Signal sendet die Stützstelle 12 der Schub-/Rekuausrollkurve.";
CM_ SG_ 1019 TSK_Ausrollkurve_Schub_Reku_16 "Dieses Signal sendet die Stützstelle 16 der Schub-/Rekuausrollkurve.";
CM_ SG_ 1019 TSK_Ausrollkurve_Schub_Reku_20 "Dieses Signal sendet die Stützstelle 20 der Schub-/Rekuausrollkurve.";
CM_ SG_ 1019 TSK_Ausrollkurve_Segeln_01 "Dieses Signal sendet die Stützstelle 1 der Segelausrollkurve.";
CM_ SG_ 1019 TSK_Ausrollkurve_Segeln_05 "Dieses Signal sendet die Stützstelle 5 der Segelausrollkurve.";
CM_ SG_ 1019 TSK_Ausrollkurve_Segeln_09 "Dieses Signal sendet die Stützstelle 9 der Segelausrollkurve.";
CM_ SG_ 1019 TSK_Ausrollkurve_Segeln_13 "Dieses Signal sendet die Stützstelle 13 der Segelausrollkurve.";
CM_ SG_ 1019 TSK_Ausrollkurve_Segeln_17 "Dieses Signal sendet die Stützstelle 17 der Segelausrollkurve.";
CM_ SG_ 1019 TSK_Ausrollkurve_Segeln_02 "Dieses Signal sendet die Stützstelle 2 der Segelausrollkurve.";
CM_ SG_ 1019 TSK_Ausrollkurve_Segeln_06 "Dieses Signal sendet die Stützstelle 6 der Segelausrollkurve.";
CM_ SG_ 1019 TSK_Ausrollkurve_Segeln_10 "Dieses Signal sendet die Stützstelle 10 der Segelausrollkurve.";
CM_ SG_ 1019 TSK_Ausrollkurve_Segeln_14 "Dieses Signal sendet die Stützstelle 14 der Segelausrollkurve.";
CM_ SG_ 1019 TSK_Ausrollkurve_Segeln_18 "Dieses Signal sendet die Stützstelle 18 der Segelausrollkurve.";
CM_ SG_ 1019 TSK_Ausrollkurve_Segeln_03 "Dieses Signal sendet die Stützstelle 3 der Segelausrollkurve.";
CM_ SG_ 1019 TSK_Ausrollkurve_Segeln_07 "Dieses Signal sendet die Stützstelle 7 der Segelausrollkurve.";
CM_ SG_ 1019 TSK_Ausrollkurve_Segeln_11 "Dieses Signal sendet die Stützstelle 11 der Segelausrollkurve.";
CM_ SG_ 1019 TSK_Ausrollkurve_Segeln_15 "Dieses Signal sendet die Stützstelle 15 der Segelausrollkurve.";
CM_ SG_ 1019 TSK_Ausrollkurve_Segeln_19 "Dieses Signal sendet die Stützstelle 19 der Segelausrollkurve.";
CM_ SG_ 1019 TSK_Ausrollkurve_Segeln_04 "Dieses Signal sendet die Stützstelle 4 der Segelausrollkurve.";
CM_ SG_ 1019 TSK_Ausrollkurve_Segeln_08 "Dieses Signal sendet die Stützstelle 8 der Segelausrollkurve.";
CM_ SG_ 1019 TSK_Ausrollkurve_Segeln_12 "Dieses Signal sendet die Stützstelle 12 der Segelausrollkurve.";
CM_ SG_ 1019 TSK_Ausrollkurve_Segeln_16 "Dieses Signal sendet die Stützstelle 16 der Segelausrollkurve.";
CM_ SG_ 1019 TSK_Ausrollkurve_Segeln_20 "Dieses Signal sendet die Stützstelle 20 der Segelausrollkurve.";
CM_ SG_ 1019 TSK_Ausrollkurve_Mux "Dieses Signal dient als Multiplexzähler für die Segel- bzw. Schub-/RekuAusrollkurve";
CM_ SG_ 1019 TSK_Ausrollkurve_Reku "Dieses Signal zeigt an, ob bei der Schub-/Rekuausrollkurve aktuell Rekuperation berücksichtigt wird.";
CM_ SG_ 1019 TSK_Ausrollkurve_Schrittweite "Dieses Signal dient dient zur Umschaltung der Stützstellenschrittweite der Segel- bzw. Schub-/Rekuausrollkurve";
CM_ SG_ 1019 TSK_Ausrollkurve_Zaehler "Dieses Signal ermöglicht die Unterscheidung der Ausrollkurven. Es wird nach der vollständigen Übertragung einer Kennlinie inkrementiert.";
CM_ BO_ 1716 "200ms bei D4 und folgende";
CM_ SG_ 1716 VIN_01_MUX "Achtung:
Die Botschaft ist nicht linear gemultiplext!!!
Sondern 0,1,0,2,0, usw.";
CM_ SG_ 1716 VIN_4 "Initwert:
0x2D bei Fahrzeugen mit Wegfahrsperrengeneration >= 5 
0x58 bei Fahrzeugen mit Wegfahrsperrengeneration < 5 (z.B. WFS-4)";
CM_ SG_ 1716 VIN_11 "Initwert:
0x2D bei Fahrzeugen mit Wegfahrsperrengeneration >= 5 
0x58 bei Fahrzeugen mit Wegfahrsperrengeneration < 5 (z.B. WFS-4)";
CM_ SG_ 1716 VIN_5 "Initwert:
0x2D bei Fahrzeugen mit Wegfahrsperrengeneration >= 5 
0x58 bei Fahrzeugen mit Wegfahrsperrengeneration < 5 (z.B. WFS-4)";
CM_ SG_ 1716 VIN_12 "Initwert:
0x2D bei Fahrzeugen mit Wegfahrsperrengeneration >= 5 
0x58 bei Fahrzeugen mit Wegfahrsperrengeneration < 5 (z.B. WFS-4)";
CM_ SG_ 1716 VIN_6 "Initwert:
0x2D bei Fahrzeugen mit Wegfahrsperrengeneration >= 5 
0x58 bei Fahrzeugen mit Wegfahrsperrengeneration < 5 (z.B. WFS-4)";
CM_ SG_ 1716 VIN_13 "Initwert:
0x2D bei Fahrzeugen mit Wegfahrsperrengeneration >= 5 
0x58 bei Fahrzeugen mit Wegfahrsperrengeneration < 5 (z.B. WFS-4)";
CM_ SG_ 1716 VIN_7 "Initwert:
0x2D bei Fahrzeugen mit Wegfahrsperrengeneration >= 5 
0x58 bei Fahrzeugen mit Wegfahrsperrengeneration < 5 (z.B. WFS-4)";
CM_ SG_ 1716 VIN_14 "Initwert:
0x2D bei Fahrzeugen mit Wegfahrsperrengeneration >= 5 
0x58 bei Fahrzeugen mit Wegfahrsperrengeneration < 5 (z.B. WFS-4)";
CM_ SG_ 1716 VIN_1 "Initwert:
0x2D bei Fahrzeugen mit Wegfahrsperrengeneration >= 5 
0x58 bei Fahrzeugen mit Wegfahrsperrengeneration < 5 (z.B. WFS-4)";
CM_ SG_ 1716 VIN_8 "Initwert:
0x2D bei Fahrzeugen mit Wegfahrsperrengeneration >= 5 
0x58 bei Fahrzeugen mit Wegfahrsperrengeneration < 5 (z.B. WFS-4)";
CM_ SG_ 1716 VIN_15 "Initwert:
0x2D bei Fahrzeugen mit Wegfahrsperrengeneration >= 5 
0x58 bei Fahrzeugen mit Wegfahrsperrengeneration < 5 (z.B. WFS-4)";
CM_ SG_ 1716 VIN_2 "Initwert:
0x2D bei Fahrzeugen mit Wegfahrsperrengeneration >= 5 
0x58 bei Fahrzeugen mit Wegfahrsperrengeneration < 5 (z.B. WFS-4)";
CM_ SG_ 1716 VIN_9 "Initwert:
0x2D bei Fahrzeugen mit Wegfahrsperrengeneration >= 5 
0x58 bei Fahrzeugen mit Wegfahrsperrengeneration < 5 (z.B. WFS-4)";
CM_ SG_ 1716 VIN_16 "Initwert:
0x2D bei Fahrzeugen mit Wegfahrsperrengeneration >= 5 
0x58 bei Fahrzeugen mit Wegfahrsperrengeneration < 5 (z.B. WFS-4)";
CM_ SG_ 1716 VIN_3 "Initwert:
0x2D bei Fahrzeugen mit Wegfahrsperrengeneration >= 5 
0x58 bei Fahrzeugen mit Wegfahrsperrengeneration < 5 (z.B. WFS-4)";
CM_ SG_ 1716 VIN_10 "Initwert:
0x2D bei Fahrzeugen mit Wegfahrsperrengeneration >= 5 
0x58 bei Fahrzeugen mit Wegfahrsperrengeneration < 5 (z.B. WFS-4)";
CM_ SG_ 1716 VIN_17 "Initwert:
0x2D bei Fahrzeugen mit Wegfahrsperrengeneration >= 5 
0x58 bei Fahrzeugen mit Wegfahrsperrengeneration < 5 (z.B. WFS-4)";
CM_ SG_ 385 VZE_Anzeigemodus "Steuert die verschiedenen Möglichkeiten der Anzeige, vor allem die Aktivierung sowie die erweiterten Anzeigen im Kombi";
CM_ SG_ 385 VZE_Hinweistext "Über Index wird ein Hinweistext beschrieben, der durch das Kombi dargestellte werden soll.

Wertebereich lt. Hashtabelle";
CM_ SG_ 385 VZE_Statuszaehler_1 "Steuerungssignal zur Steuerung des Distanzzählers von Verkehrszeichen 1";
CM_ SG_ 385 VZE_Statuszaehler_2 "Steuerungssignal zur Steuerung des Distanzzählers von Verkehrszeichen 2";
CM_ SG_ 385 VZE_Statuszaehler_3 "Steuerungssignal zur Steuerung des Distanzzählers von Verkehrszeichen 3";
CM_ SG_ 385 VZE_Verkehrszeichen_1 "Das Signal spiegelt eines der Verkehrszeichen: Geschwindigkeitsgebot, Überholverbot, Aufhebungszeichen wider.

Wertebereich lt. Hashtabelle";
CM_ SG_ 385 VZE_Verkehrszeichen_2 "Das Signal spiegelt eines der Verkehrszeichen: Geschwindigkeitsgebot, Überholverbot, Aufhebungszeichen wider.

Wertebereich lt. Hashtabelle";
CM_ SG_ 385 VZE_Verkehrszeichen_3 "Das Signal spiegelt eines der Verkehrszeichen: Geschwindigkeitsgebot, Überholverbot, Aufhebungszeichen wider.

Wertebereich lt. Hashtabelle";
CM_ SG_ 385 VZE_Warnung_Verkehrszeichen_1 "Ist das Signal gesetzt, so ist für das Verkehrszeichen 1 eine Warnung auszugeben.";
CM_ SG_ 385 VZE_Warnung_Verkehrszeichen_2 "Ist das Signal gesetzt, so ist für das Verkehrszeichen 2 eine Warnung auszugeben.";
CM_ SG_ 385 VZE_Warnung_Verkehrszeichen_3 "Ist das Signal gesetzt, so ist für das Verkehrszeichen 3 eine Warnung auszugeben.";
CM_ SG_ 385 VZE_Zusatzschild_1 "Zusatzsschild, das zu Verkehrszeichen 1 angezeigt werden soll.

Wertebereich lt. Hashtabelle";
CM_ SG_ 385 VZE_Zusatzschild_2 "Zusatzsschild, das zu Verkehrszeichen 2 angezeigt werden soll.

Wertebereich lt. Hashtabelle";
CM_ SG_ 385 VZE_Zusatzschild_3 "Zusatzsschild, das zu Verkehrszeichen 3 angezeigt werden soll.

Wertebereich lt. Hashtabelle";
CM_ SG_ 385 VZE_Hinweistext_02 "Über Index wird ein Hinweistext beschrieben, der durch das Kombi dargestellte werden soll.

Wertebereich lt. Hashtabelle";
CM_ SG_ 668 VZE_Statuszaehler_4 "Steuerungssignal zur Steuerung des Distanzzählers von Verkehrszeichen 4";
CM_ SG_ 668 VZE_Statuszaehler_5 "Steuerungssignal zur Steuerung des Distanzzählers von Verkehrszeichen 5";
CM_ SG_ 668 VZE_Zeichen_05_KameraWied "Das VZE-Tempolimit wurde als Wiederholungsschild von der Kamera erkannt.";
CM_ SG_ 668 VZE_Zeichen_05_Kamera "Das VZE-Tempolimit wurde von der Kamera erkannt.";
CM_ SG_ 668 VZE_Verkehrszeichen_4 "Das Signal spiegelt eines der Verkehrszeichen: Geschwindigkeitsgebot, Überholverbot, Aufhebungszeichen wider.

Wertebereich lt. Hashtabelle";
CM_ SG_ 668 VZE_Verkehrszeichen_5 "Das Signal spiegelt eines der Verkehrszeichen: Geschwindigkeitsgebot, Überholverbot, Aufhebungszeichen wider.

Wertebereich lt. Hashtabelle";
CM_ SG_ 668 VZE_Anhaenger_Vmax "Übertragung der aus Kundeneinstellung und länderspezifischen Regelungen (StVO, Rechtsprechung...) berechneten legalen Höchstgeschwindigkeit für das Gespann.

10+ 0*10 = 10 km/h
10+ 1*10 = 20 km/h
...
10+ 5*10 = 60 km/h
10+ 6*10 = 70 km/h
...
10+ 1";
CM_ SG_ 668 VZE_Zeichen_04_Gesetz "Das VZE-Tempolimit ist das gesetzlich geltende Tempolimit (je Land/Straßenklasse).";
CM_ SG_ 668 VZE_Zeichen_04_Kamera "Das VZE-Tempolimit wurde von der Kamera erkannt.";
CM_ SG_ 668 VZE_Zeichen_04_KameraWied "Das VZE-Tempolimit wurde als Wiederholungsschild von der Kamera erkannt.";
CM_ SG_ 668 VZE_Zeichen_04_Karte "Das VZE-Tempolimit stammt aus den Navigationskartendaten.";
CM_ SG_ 668 VZE_Warnung_Verkehrszeichen_4 "Ist das Signal gesetzt, so ist für das Verkehrszeichen 4 eine Warnung auszugeben.";
CM_ SG_ 668 VZE_Warnung_Verkehrszeichen_5 "Ist das Signal gesetzt, so ist für das Verkehrszeichen 5 eine Warnung auszugeben.";
CM_ SG_ 668 VZE_Zeichen_05_Gesetz "Das VZE-Tempolimit ist das gesetzlich geltende Tempolimit (je Land/Straßenklasse).";
CM_ SG_ 668 VZE_Zusatzschild_4 "Zusatzsschild, das zu Verkehrszeichen 4 angezeigt werden soll.

Wertebereich lt. Hashtabelle";
CM_ SG_ 668 VZE_Zusatzschild_5 "Zusatzsschild, das zu Verkehrszeichen 5 angezeigt werden soll.

Wertebereich lt. Hashtabelle";
CM_ SG_ 668 VZE_Baustelle "Das Signal gibt an, ob aktuell ein Baustellenschild von der VZE erkannt wurde.";
CM_ SG_ 668 VZE_Zeichen_05_Karte "Das VZE-Tempolimit stammt aus den Navigationskartendaten.";
BA_DEF_ BO_  "DiagRequest" ENUM  "No","Yes";
BA_DEF_ BO_  "DiagResponse" ENUM  "No","Yes";
BA_DEF_ BO_  "DiagState" ENUM  "No","Yes";
BA_DEF_ BO_  "GenMsgChkConstant" HEX 0 4095;
BA_DEF_ BO_  "GenMsgCycleTime" INT 0 65535;
BA_DEF_ BO_  "GenMsgCycleTimeFast" INT 0 65535;
BA_DEF_ BO_  "GenMsgDelayTime" INT 0 100000;
BA_DEF_ BO_  "GenMsgILSupport" ENUM  "No","Yes";
BA_DEF_ BO_  "GenMsgNrOfRepetition" INT 0 100;
BA_DEF_ BO_  "GenMsgPDUConstants" STRING ;
BA_DEF_ BO_  "GenMsgSendType" ENUM  "Cyclic","not_used","not_used","not_used","not_used","not_used","not_used","IfActive","NoMsgSendType";
BA_DEF_ BO_  "GenMsgStartDelayTime" INT 0 100000;
BA_DEF_ BO_  "NmMessage" ENUM  "No","Yes";
BA_DEF_ BO_  "NmhMessage" ENUM  "No","Yes";
BA_DEF_ BO_  "MsgType" ENUM  "Application","NM ","NMH","TP2.0","ISO-TP ","BAP","EID","KS";
BA_DEF_ BO_  "VAGTP20_API" HEX 0 255;
BA_DEF_ BO_  "VAGTP20_DynConnection" ENUM  "No","Yes";
BA_DEF_ BO_  "VAGTP20_DynSetup" ENUM  "No","Yes";
BA_DEF_ BO_  "VAGTP20_StatConnection" ENUM  "No","Yes";
BA_DEF_ SG_  "GenSigActiveRepetitions" INT -2147483648 2147483647;
BA_DEF_ SG_  "GenSigInactiveValue" INT -2147483648 2147483647;
BA_DEF_ SG_  "GenSigSendType" ENUM  "Cyclic","OnWrite","OnWriteWithRepetition","OnChange","OnChangeWithRepetition","IfActive","IfActiveWithRepetition","NoSigSendType","OnChangeAndIfActive","OnChangeAndIfActiveWithRepetition";
BA_DEF_ SG_  "GenSigStartValue" INT -2147483648 2147483647;
BA_DEF_ SG_  "NWM-WakeupAllowed" ENUM  "No","Yes";
BA_DEF_ SG_  "GenSigFuncType" ENUM  "NoFunction","MsgCounter","CRC-8","XOR","XOR-2","DatedBit","SW-Kl15","CHK","Constant","Protocol","CRC-8-SAE_J1850";
BA_DEF_ SG_  "GenSigSwitchedByIgnition" ENUM  "No","Yes";
BA_DEF_ SG_  "Fehlerwert" HEX 0 2147483647;
BA_DEF_ SG_  "GenSigMissingSourceValue" HEX 0 2147483647;
BA_DEF_REL_ BU_SG_REL_  "GenSigTimeoutTime" INT 0 65535;
BA_DEF_DEF_REL_ "GenSigTimeoutTime" 0;
BA_DEF_DEF_  "DiagRequest" "No";
BA_DEF_DEF_  "DiagResponse" "No";
BA_DEF_DEF_  "DiagState" "No";
BA_DEF_DEF_  "GenMsgChkConstant" 0;
BA_DEF_DEF_  "GenMsgCycleTime" 0;
BA_DEF_DEF_  "GenMsgCycleTimeFast" 0;
BA_DEF_DEF_  "GenMsgDelayTime" 0;
BA_DEF_DEF_  "GenMsgILSupport" "No";
BA_DEF_DEF_  "GenMsgNrOfRepetition" 0;
BA_DEF_DEF_  "GenMsgPDUConstants" "";
BA_DEF_DEF_  "GenMsgSendType" "NoMsgSendType";
BA_DEF_DEF_  "GenMsgStartDelayTime" 0;
BA_DEF_DEF_  "NmMessage" "No";
BA_DEF_DEF_  "NmhMessage" "No";
BA_DEF_DEF_  "MsgType" "Application";
BA_DEF_DEF_  "VAGTP20_API" 0;
BA_DEF_DEF_  "VAGTP20_DynConnection" "No";
BA_DEF_DEF_  "VAGTP20_DynSetup" "No";
BA_DEF_DEF_  "VAGTP20_StatConnection" "No";
BA_DEF_DEF_  "GenSigActiveRepetitions" 0;
BA_DEF_DEF_  "GenSigInactiveValue" 0;
BA_DEF_DEF_  "GenSigSendType" "NoSigSendType";
BA_DEF_DEF_  "GenSigStartValue" 0;
BA_DEF_DEF_  "NWM-WakeupAllowed" "No";
BA_DEF_DEF_  "GenSigFuncType" "NoFunction";
BA_DEF_DEF_  "GenSigSwitchedByIgnition" "Yes";
BA_DEF_DEF_  "Fehlerwert" 0;
BA_DEF_DEF_  "GenSigMissingSourceValue" 0;
BA_ "GenMsgSendType" BO_ 930 0;
BA_ "GenMsgILSupport" BO_ 930 1;
BA_ "GenMsgCycleTime" BO_ 930 150;
BA_ "GenMsgSendType" BO_ 1122 0;
BA_ "GenMsgILSupport" BO_ 1122 1;
BA_ "GenMsgCycleTime" BO_ 1122 150;
BA_ "GenMsgSendType" BO_ 1123 0;
BA_ "GenMsgILSupport" BO_ 1123 1;
BA_ "GenMsgCycleTime" BO_ 1123 150;
BA_ "GenMsgSendType" BO_ 1124 0;
BA_ "GenMsgILSupport" BO_ 1124 1;
BA_ "GenMsgCycleTime" BO_ 1124 150;
BA_ "GenMsgSendType" BO_ 695 0;
BA_ "GenMsgPDUConstants" BO_ 695 "0x5e,0xc7,0x04,0x11,0x4d,0x27,0x0d,0x31,0x91,0xb8,0x62,0x76,0x64,0x09,0xeb,0xec";
BA_ "GenMsgILSupport" BO_ 695 1;
BA_ "GenMsgCycleTime" BO_ 695 50;
BA_ "GenMsgSendType" BO_ 1440 0;
BA_ "GenMsgILSupport" BO_ 1440 1;
BA_ "GenMsgCycleTime" BO_ 1440 200;
BA_ "GenMsgSendType" BO_ 684 0;
BA_ "GenMsgPDUConstants" BO_ 684 "0x53,0x2b,0x5e,0xbc,0xce,0xc7,0xe0,0xa6,0x04,0x80,0x21,0x11,0xaa,0xe1,0x4d,0x88";
BA_ "GenMsgNrOfRepetition" BO_ 684 5;
BA_ "GenMsgILSupport" BO_ 684 1;
BA_ "GenMsgDelayTime" BO_ 684 20;
BA_ "GenMsgCycleTimeFast" BO_ 684 20;
BA_ "GenMsgCycleTime" BO_ 684 1000;
BA_ "GenMsgSendType" BO_ 783 0;
BA_ "GenMsgPDUConstants" BO_ 783 "0x0c,0x0c,0x0c,0x0c,0x0c,0x0c,0x0c,0x0c,0x0c,0x0c,0x0c,0x0c,0x0c,0x0c,0x0c,0x0c";
BA_ "GenMsgILSupport" BO_ 783 1;
BA_ "GenMsgCycleTime" BO_ 783 50;
BA_ "GenMsgChkConstant" BO_ 783 12;
BA_ "GenMsgSendType" BO_ 1413 0;
BA_ "GenMsgILSupport" BO_ 1413 1;
BA_ "GenMsgDelayTime" BO_ 1413 10;
BA_ "GenMsgCycleTime" BO_ 1413 1000;
BA_ "GenMsgSendType" BO_ 997 0;
BA_ "GenMsgPDUConstants" BO_ 997 "0xc4,0x6a,0x69,0x30,0xcf,0x61,0x58,0x51,0x1b,0x86,0x99,0xd3,0xf6,0x1d,0x9a,0x37";
BA_ "GenMsgILSupport" BO_ 997 1;
BA_ "GenMsgDelayTime" BO_ 997 20;
BA_ "GenMsgCycleTime" BO_ 997 100;
BA_ "GenMsgSendType" BO_ 288 0;
BA_ "GenMsgPDUConstants" BO_ 288 "0xc4,0xe2,0x4f,0xe4,0xf8,0x2f,0x56,0x81,0x9f,0xe5,0x83,0x44,0x05,0x3f,0x97,0xdf";
BA_ "GenMsgILSupport" BO_ 288 1;
BA_ "GenMsgCycleTime" BO_ 288 20;
BA_ "GenMsgSendType" BO_ 346 0;
BA_ "GenMsgPDUConstants" BO_ 346 "0xcf,0x1a,0x84,0x28,0x05,0xcb,0xb3,0x98,0x82,0x53,0xbe,0xa1,0x4a,0x6d,0x41,0xae";
BA_ "GenMsgILSupport" BO_ 346 1;
BA_ "GenMsgDelayTime" BO_ 346 20;
BA_ "GenMsgCycleTime" BO_ 346 100;
BA_ "GenMsgSendType" BO_ 1019 0;
BA_ "GenMsgILSupport" BO_ 1019 1;
BA_ "GenMsgCycleTime" BO_ 1019 80;
BA_ "GenMsgSendType" BO_ 1716 0;
BA_ "GenMsgILSupport" BO_ 1716 1;
BA_ "GenMsgCycleTime" BO_ 1716 200;
BA_ "GenMsgSendType" BO_ 385 0;
BA_ "GenMsgILSupport" BO_ 385 1;
BA_ "GenMsgDelayTime" BO_ 385 40;
BA_ "GenMsgCycleTime" BO_ 385 200;
BA_ "GenMsgSendType" BO_ 668 0;
BA_ "GenMsgILSupport" BO_ 668 1;
BA_ "GenMsgDelayTime" BO_ 668 40;
BA_ "GenMsgCycleTime" BO_ 668 200;
BA_ "GenSigSendType" SG_ 930 PSD_Multiplex 0;
BA_ "GenSigStartValue" SG_ 930 PSD_Abz_Fahrspuren 1;
BA_ "GenSigSendType" SG_ 1122 PSD_Segment_ID 0;
BA_ "GenSigSendType" SG_ 1122 PSD_Vorgaenger_Segment_ID 0;
BA_ "GenSigSendType" SG_ 1122 PSD_Segmentlaenge 0;
BA_ "GenSigSwitchedByIgnition" SG_ 1122 PSD_Strassenkategorie 0;
BA_ "GenSigStartValue" SG_ 1122 PSD_Strassenkategorie 7;
BA_ "GenSigSendType" SG_ 1122 PSD_Strassenkategorie 0;
BA_ "GenSigSendType" SG_ 1122 PSD_Endkruemmung 0;
BA_ "GenSigSendType" SG_ 1122 PSD_Endkruemmung_Vorz 0;
BA_ "Fehlerwert" SG_ 1122 PSD_Idenditaets_ID 1;
BA_ "GenSigSendType" SG_ 1122 PSD_Idenditaets_ID 0;
BA_ "GenSigSendType" SG_ 1122 PSD_ADAS_Qualitaet 0;
BA_ "GenSigSendType" SG_ 1122 PSD_wahrscheinlichster_Pfad 0;
BA_ "GenSigSendType" SG_ 1122 PSD_Geradester_Pfad 0;
BA_ "GenSigSwitchedByIgnition" SG_ 1122 PSD_Fahrspuren_Anzahl 0;
BA_ "GenSigStartValue" SG_ 1122 PSD_Fahrspuren_Anzahl 1;
BA_ "GenSigSendType" SG_ 1122 PSD_Fahrspuren_Anzahl 0;
BA_ "GenSigSendType" SG_ 1122 PSD_Bebauung 0;
BA_ "GenSigSwitchedByIgnition" SG_ 1122 PSD_Segment_Komplett 0;
BA_ "GenSigSendType" SG_ 1122 PSD_Segment_Komplett 0;
BA_ "GenSigSendType" SG_ 1122 PSD_Rampe 0;
BA_ "GenSigSwitchedByIgnition" SG_ 1122 PSD_Anfangskruemmung 0;
BA_ "GenSigSendType" SG_ 1122 PSD_Anfangskruemmung 0;
BA_ "GenSigSwitchedByIgnition" SG_ 1122 PSD_Anfangskruemmung_Vorz 0;
BA_ "GenSigSendType" SG_ 1122 PSD_Anfangskruemmung_Vorz 0;
BA_ "GenSigSwitchedByIgnition" SG_ 1122 PSD_Abzweigerichtung 0;
BA_ "GenSigSendType" SG_ 1122 PSD_Abzweigerichtung 0;
BA_ "GenSigSwitchedByIgnition" SG_ 1122 PSD_Abzweigewinkel 0;
BA_ "GenSigSendType" SG_ 1122 PSD_Abzweigewinkel 0;
BA_ "GenSigSendType" SG_ 1123 PSD_Pos_Segment_ID 0;
BA_ "GenSigSendType" SG_ 1123 PSD_Pos_Segmentlaenge 0;
BA_ "GenSigSendType" SG_ 1123 PSD_Pos_Inhibitzeit 0;
BA_ "GenSigSwitchedByIgnition" SG_ 1123 PSD_Pos_Standort_Eindeutig 0;
BA_ "GenSigSendType" SG_ 1123 PSD_Pos_Standort_Eindeutig 0;
BA_ "GenSigSendType" SG_ 1123 PSD_Pos_Fehler_Laengsrichtung 0;
BA_ "GenSigSendType" SG_ 1123 PSD_Pos_Fahrspur 0;
BA_ "Fehlerwert" SG_ 1123 PSD_Attribut_Segment_ID_05 1;
BA_ "GenSigSendType" SG_ 1123 PSD_Attribut_Segment_ID_05 0;
BA_ "GenSigSendType" SG_ 1123 PSD_Attribut_1_ID 0;
BA_ "GenSigSendType" SG_ 1123 PSD_Attribut_1_Wert 0;
BA_ "GenSigSendType" SG_ 1123 PSD_Attribut_1_Offset 0;
BA_ "GenSigSendType" SG_ 1123 PSD_Attribut_2_ID 0;
BA_ "GenSigSendType" SG_ 1123 PSD_Attribut_2_Wert 0;
BA_ "GenSigSendType" SG_ 1123 PSD_Attribut_2_Offset 0;
BA_ "GenSigSendType" SG_ 1123 PSD_Attribute_Komplett_05 0;
BA_ "GenSigSwitchedByIgnition" SG_ 1124 PSD_06_Mux 0;
BA_ "NWM-WakeupAllowed" SG_ 1124 PSD_06_Mux 1;
BA_ "GenSigSendType" SG_ 1124 PSD_06_Mux 0;
BA_ "Fehlerwert" SG_ 1124 PSD_Attribut_Segment_ID 1;
BA_ "Fehlerwert" SG_ 1124 PSD_Steigung_1_Segment_ID 1;
BA_ "GenSigSwitchedByIgnition" SG_ 1124 PSD_Ges_Typ 0;
BA_ "GenSigStartValue" SG_ 1124 PSD_Ges_Typ 3;
BA_ "GenSigSwitchedByIgnition" SG_ 1124 PSD_Steigung_1_Attribute_kompl 0;
BA_ "Fehlerwert" SG_ 1124 PSD_Steigung_2_Segment_ID 1;
BA_ "GenSigSwitchedByIgnition" SG_ 1124 PSD_Attribute_Komplett_06 0;
BA_ "GenSigSwitchedByIgnition" SG_ 1124 PSD_Steigung_2_Attribute_kompl 0;
BA_ "GenSigFuncType" SG_ 695 RCTA_01_CRC 2;
BA_ "GenSigSendType" SG_ 695 RCTA_01_CRC 0;
BA_ "GenSigFuncType" SG_ 695 RCTA_01_BZ 1;
BA_ "GenSigSendType" SG_ 695 RCTA_01_BZ 0;
BA_ "GenSigSendType" SG_ 695 RCTA_Info_rechts 0;
BA_ "GenSigSendType" SG_ 695 RCTA_Anforderung_HMS 0;
BA_ "GenSigSendType" SG_ 695 RCTA_Bremsruck_Anforderung 0;
BA_ "GenSigSendType" SG_ 695 RCTA_Bremsruck_Freigabe 0;
BA_ "GenSigSendType" SG_ 695 RCTA_Info_links 0;
BA_ "Fehlerwert" SG_ 695 RCTA_Status 3;
BA_ "GenSigSendType" SG_ 695 RCTA_Status 0;
BA_ "GenSigSendType" SG_ 695 RCTA_Warnton 0;
BA_ "GenSigSendType" SG_ 695 RCTA_Notbremsung_Freigabe 0;
BA_ "Fehlerwert" SG_ 695 RCTA_Notbremsung_Anforderung 255;
BA_ "GenSigSendType" SG_ 695 RCTA_Notbremsung_Anforderung 0;
BA_ "GenSigMissingSourceValue" SG_ 1440 LS_Helligkeit_IR 255;
BA_ "Fehlerwert" SG_ 1440 LS_Helligkeit_IR 255;
BA_ "GenSigSwitchedByIgnition" SG_ 1440 LS_Helligkeit_IR 0;
BA_ "GenSigStartValue" SG_ 1440 LS_Helligkeit_IR 254;
BA_ "GenSigSendType" SG_ 1440 LS_Helligkeit_IR 0;
BA_ "GenSigMissingSourceValue" SG_ 1440 LS_Helligkeit_FW 1023;
BA_ "Fehlerwert" SG_ 1440 LS_Helligkeit_FW 1023;
BA_ "GenSigSwitchedByIgnition" SG_ 1440 LS_Helligkeit_FW 0;
BA_ "GenSigStartValue" SG_ 1440 LS_Helligkeit_FW 1022;
BA_ "GenSigSendType" SG_ 1440 LS_Helligkeit_FW 0;
BA_ "GenSigSwitchedByIgnition" SG_ 1440 LS_defekt 0;
BA_ "GenSigSendType" SG_ 1440 LS_defekt 0;
BA_ "GenSigSwitchedByIgnition" SG_ 1440 LS_Verbau 0;
BA_ "GenSigSendType" SG_ 1440 LS_Verbau 0;
BA_ "GenSigMissingSourceValue" SG_ 1440 RS_Regenmenge 15;
BA_ "Fehlerwert" SG_ 1440 RS_Regenmenge 15;
BA_ "GenSigSwitchedByIgnition" SG_ 1440 RS_Regenmenge 0;
BA_ "GenSigStartValue" SG_ 1440 RS_Regenmenge 14;
BA_ "GenSigSendType" SG_ 1440 RS_Regenmenge 0;
BA_ "GenSigSwitchedByIgnition" SG_ 1440 RS_Verbau 0;
BA_ "GenSigSendType" SG_ 1440 RS_Verbau 0;
BA_ "GenSigSwitchedByIgnition" SG_ 1440 RS_Verglasung_schliessen 0;
BA_ "GenSigSendType" SG_ 1440 RS_Verglasung_schliessen 0;
BA_ "GenSigSwitchedByIgnition" SG_ 1440 RS_defekt 0;
BA_ "GenSigSendType" SG_ 1440 RS_defekt 0;
BA_ "GenSigSwitchedByIgnition" SG_ 1440 RS_Wischergeschwindigkeit 0;
BA_ "GenSigSendType" SG_ 1440 RS_Wischergeschwindigkeit 0;
BA_ "GenSigStartValue" SG_ 1440 RLS_Vorfeldhelligkeit_Boost 15;
BA_ "GenSigSendType" SG_ 1440 RLS_Vorfeldhelligkeit_Boost 0;
BA_ "GenSigFuncType" SG_ 684 SDF_PSF_01_CRC 2;
BA_ "GenSigSendType" SG_ 684 SDF_PSF_01_CRC 0;
BA_ "GenSigFuncType" SG_ 684 SDF_PSF_01_BZ 1;
BA_ "GenSigSendType" SG_ 684 SDF_PSF_01_BZ 0;
BA_ "Fehlerwert" SG_ 684 SDF_PSF_Objektstatus 7;
BA_ "GenSigSendType" SG_ 684 SDF_PSF_Objektstatus 0;
BA_ "GenSigStartValue" SG_ 684 SDF_PSF_Fahrer_aktiv 1;
BA_ "GenSigSendType" SG_ 684 SDF_PSF_Fahrer_aktiv 0;
BA_ "Fehlerwert" SG_ 684 SDF_PSF_Time_To_Collision 255;
BA_ "GenSigStartValue" SG_ 684 SDF_PSF_Time_To_Collision 254;
BA_ "GenSigSendType" SG_ 684 SDF_PSF_Time_To_Collision 0;
BA_ "Fehlerwert" SG_ 684 SDF_PSF_v_rel 255;
BA_ "GenSigStartValue" SG_ 684 SDF_PSF_v_rel 254;
BA_ "GenSigSendType" SG_ 684 SDF_PSF_v_rel 0;
BA_ "Fehlerwert" SG_ 684 SDF_PSF_Kollisionsueberdeckung 31;
BA_ "GenSigStartValue" SG_ 684 SDF_PSF_Kollisionsueberdeckung 30;
BA_ "GenSigSendType" SG_ 684 SDF_PSF_Kollisionsueberdeckung 0;
BA_ "GenSigSendType" SG_ 684 SDF_PSF_01_Sendestatus 6;
BA_ "GenSigSendType" SG_ 684 SDF_PSF_CU_Status 0;
BA_ "Fehlerwert" SG_ 684 SDF_PSF_CW 127;
BA_ "GenSigStartValue" SG_ 684 SDF_PSF_CW 126;
BA_ "GenSigSendType" SG_ 684 SDF_PSF_CW 0;
BA_ "GenSigSendType" SG_ 684 SDF_PSF_Guete 0;
BA_ "GenSigFuncType" SG_ 783 SWA_01_CRC 2;
BA_ "GenSigSendType" SG_ 783 SWA_01_CRC 0;
BA_ "GenSigFuncType" SG_ 783 SWA_01_BZ 1;
BA_ "GenSigSendType" SG_ 783 SWA_01_BZ 0;
BA_ "GenSigSendType" SG_ 783 SWA_Anzeigen 0;
BA_ "GenSigSendType" SG_ 783 SWA_Blindheit_erkannt 0;
BA_ "GenSigSendType" SG_ 783 SWA_rel_Nichtverf 0;
BA_ "Fehlerwert" SG_ 783 SWA_rel_Fehler 1;
BA_ "GenSigSendType" SG_ 783 SWA_rel_Fehler 0;
BA_ "GenSigSendType" SG_ 783 SWA_Sta_aktiv 0;
BA_ "GenSigSendType" SG_ 783 SWA_Sta_passiv 0;
BA_ "GenSigSendType" SG_ 783 SWA_FT_RueckLED 0;
BA_ "Fehlerwert" SG_ 783 ASW_Status 2;
BA_ "GenSigSendType" SG_ 783 ASW_Status 0;
BA_ "GenSigSendType" SG_ 783 SWA_Standziele_li 0;
BA_ "GenSigSendType" SG_ 783 SWA_Kolonne_li 0;
BA_ "GenSigSendType" SG_ 783 SWA_Infostufe_SWA_li 0;
BA_ "GenSigSendType" SG_ 783 SWA_Warnung_SWA_li 0;
BA_ "GenSigSendType" SG_ 783 ASW_Warnung_FS 0;
BA_ "GenSigSendType" SG_ 783 ASW_Warnung_BFS 0;
BA_ "GenSigSendType" SG_ 783 ASW_Kombitexte 0;
BA_ "GenSigSendType" SG_ 783 SWA_Kolonne_mi 0;
BA_ "GenSigSendType" SG_ 783 SWA_Standziele_re 0;
BA_ "GenSigSendType" SG_ 783 SWA_Kolonne_re 0;
BA_ "GenSigSendType" SG_ 783 SWA_Infostufe_SWA_re 0;
BA_ "GenSigSendType" SG_ 783 SWA_Warnung_SWA_re 0;
BA_ "GenSigSendType" SG_ 783 HRE_Anzeigetexte 0;
BA_ "GenSigSendType" SG_ 783 SWA_Gischtzaehler 0;
BA_ "GenSigSendType" SG_ 783 Heckradar_Kombitexte 0;
BA_ "GenSigSendType" SG_ 783 RCTA_Kombitexte 0;
BA_ "GenSigSwitchedByIgnition" SG_ 1413 SI_Sammel_SG_Fehler 0;
BA_ "GenSigStartValue" SG_ 1413 SI_Sammel_SG_Fehler 63;
BA_ "GenSigSendType" SG_ 1413 SI_Sammel_SG_Fehler 0;
BA_ "GenSigSwitchedByIgnition" SG_ 1413 SI_Diagnose_Aktiv 0;
BA_ "GenSigSendType" SG_ 1413 SI_Diagnose_Aktiv 3;
BA_ "GenSigSwitchedByIgnition" SG_ 1413 SI_QRS_Mode 0;
BA_ "GenSigSendType" SG_ 1413 SI_QRS_Mode 3;
BA_ "GenSigSwitchedByIgnition" SG_ 1413 SI_T_Mode 0;
BA_ "GenSigSendType" SG_ 1413 SI_T_Mode 3;
BA_ "GenSigSwitchedByIgnition" SG_ 1413 SI_NWDF 0;
BA_ "GenSigSendType" SG_ 1413 SI_NWDF 3;
BA_ "GenSigSwitchedByIgnition" SG_ 1413 SI_NWDF_gueltig 0;
BA_ "GenSigFuncType" SG_ 1413 SI_NWDF_gueltig 8;
BA_ "GenSigSendType" SG_ 1413 SI_NWDF_gueltig 3;
BA_ "GenSigSwitchedByIgnition" SG_ 1413 SI_Sammelfehler 0;
BA_ "GenSigSendType" SG_ 1413 SI_Sammelfehler 3;
BA_ "GenSigSendType" SG_ 1413 GW_KD_Fehler 3;
BA_ "GenSigSwitchedByIgnition" SG_ 1413 SI_T_Schutz 0;
BA_ "GenSigSendType" SG_ 1413 SI_T_Schutz 3;
BA_ "GenSigSwitchedByIgnition" SG_ 1413 SI_BUS_01 0;
BA_ "GenSigStartValue" SG_ 1413 SI_BUS_01 1;
BA_ "GenSigSendType" SG_ 1413 SI_BUS_01 3;
BA_ "GenSigSwitchedByIgnition" SG_ 1413 SI_BUS_02 0;
BA_ "GenSigStartValue" SG_ 1413 SI_BUS_02 1;
BA_ "GenSigSendType" SG_ 1413 SI_BUS_02 3;
BA_ "GenSigSwitchedByIgnition" SG_ 1413 SI_BUS_03 0;
BA_ "GenSigStartValue" SG_ 1413 SI_BUS_03 1;
BA_ "GenSigSendType" SG_ 1413 SI_BUS_03 3;
BA_ "GenSigSwitchedByIgnition" SG_ 1413 SI_BUS_04 0;
BA_ "GenSigStartValue" SG_ 1413 SI_BUS_04 1;
BA_ "GenSigSendType" SG_ 1413 SI_BUS_04 3;
BA_ "GenSigSwitchedByIgnition" SG_ 1413 SI_BUS_05 0;
BA_ "GenSigStartValue" SG_ 1413 SI_BUS_05 1;
BA_ "GenSigSendType" SG_ 1413 SI_BUS_05 3;
BA_ "GenSigSwitchedByIgnition" SG_ 1413 SI_BUS_06 0;
BA_ "GenSigStartValue" SG_ 1413 SI_BUS_06 1;
BA_ "GenSigSendType" SG_ 1413 SI_BUS_06 3;
BA_ "GenSigSwitchedByIgnition" SG_ 1413 SI_BUS_07 0;
BA_ "GenSigStartValue" SG_ 1413 SI_BUS_07 1;
BA_ "GenSigSendType" SG_ 1413 SI_BUS_07 3;
BA_ "GenSigSwitchedByIgnition" SG_ 1413 SI_BUS_08 0;
BA_ "GenSigStartValue" SG_ 1413 SI_BUS_08 1;
BA_ "GenSigSendType" SG_ 1413 SI_BUS_08 3;
BA_ "GenSigSwitchedByIgnition" SG_ 1413 SI_BUS_09 0;
BA_ "GenSigStartValue" SG_ 1413 SI_BUS_09 1;
BA_ "GenSigSendType" SG_ 1413 SI_BUS_09 3;
BA_ "GenSigSwitchedByIgnition" SG_ 1413 SI_BUS_10 0;
BA_ "GenSigStartValue" SG_ 1413 SI_BUS_10 1;
BA_ "GenSigSendType" SG_ 1413 SI_BUS_10 3;
BA_ "GenSigSwitchedByIgnition" SG_ 1413 SI_BUS_11 0;
BA_ "GenSigStartValue" SG_ 1413 SI_BUS_11 1;
BA_ "GenSigSendType" SG_ 1413 SI_BUS_11 3;
BA_ "GenSigSwitchedByIgnition" SG_ 1413 SI_BUS_12 0;
BA_ "GenSigStartValue" SG_ 1413 SI_BUS_12 1;
BA_ "GenSigSendType" SG_ 1413 SI_BUS_12 3;
BA_ "GenSigSwitchedByIgnition" SG_ 1413 SI_BUS_13 0;
BA_ "GenSigStartValue" SG_ 1413 SI_BUS_13 1;
BA_ "GenSigSendType" SG_ 1413 SI_BUS_13 3;
BA_ "GenSigSwitchedByIgnition" SG_ 1413 SI_BUS_14 0;
BA_ "GenSigStartValue" SG_ 1413 SI_BUS_14 1;
BA_ "GenSigSendType" SG_ 1413 SI_BUS_14 3;
BA_ "GenSigSwitchedByIgnition" SG_ 1413 SI_BUS_15 0;
BA_ "GenSigStartValue" SG_ 1413 SI_BUS_15 1;
BA_ "GenSigSendType" SG_ 1413 SI_BUS_15 3;
BA_ "GenSigSwitchedByIgnition" SG_ 1413 SI_Bus_Identifikation 0;
BA_ "GenSigFuncType" SG_ 1413 SI_Bus_Identifikation 8;
BA_ "GenSigSendType" SG_ 1413 SI_Bus_Identifikation 0;
BA_ "GenSigSwitchedByIgnition" SG_ 997 TSG_FT_02_CRC 0;
BA_ "GenSigFuncType" SG_ 997 TSG_FT_02_CRC 2;
BA_ "GenSigSendType" SG_ 997 TSG_FT_02_CRC 0;
BA_ "GenSigSwitchedByIgnition" SG_ 997 TSG_FT_02_BZ 0;
BA_ "GenSigFuncType" SG_ 997 TSG_FT_02_BZ 1;
BA_ "GenSigSendType" SG_ 997 TSG_FT_02_BZ 0;
BA_ "Fehlerwert" SG_ 997 FT_Tuer_Status 3;
BA_ "GenSigSwitchedByIgnition" SG_ 997 FT_Tuer_Status 0;
BA_ "GenSigSendType" SG_ 997 FT_Tuer_Status 3;
BA_ "GenSigSwitchedByIgnition" SG_ 997 FT_Tuer_Status_QBit 0;
BA_ "GenSigSendType" SG_ 997 FT_Tuer_Status_QBit 0;
BA_ "GenSigSwitchedByIgnition" SG_ 997 FT_Lock_Taster_02 0;
BA_ "GenSigSendType" SG_ 997 FT_Lock_Taster_02 0;
BA_ "GenSigSwitchedByIgnition" SG_ 997 FT_Schluesselschalter_zu_02 0;
BA_ "GenSigSendType" SG_ 997 FT_Schluesselschalter_zu_02 0;
BA_ "Fehlerwert" SG_ 997 FT_BFS_Tuer_Status 3;
BA_ "GenSigSwitchedByIgnition" SG_ 997 FT_BFS_Tuer_Status 0;
BA_ "GenSigSendType" SG_ 997 FT_BFS_Tuer_Status 3;
BA_ "Fehlerwert" SG_ 997 FT_HBFS_Tuer_Status 3;
BA_ "GenSigSwitchedByIgnition" SG_ 997 FT_HBFS_Tuer_Status 0;
BA_ "GenSigSendType" SG_ 997 FT_HBFS_Tuer_Status 3;
BA_ "Fehlerwert" SG_ 997 FT_HFS_Tuer_Status 3;
BA_ "GenSigSwitchedByIgnition" SG_ 997 FT_HFS_Tuer_Status 0;
BA_ "GenSigSendType" SG_ 997 FT_HFS_Tuer_Status 3;
BA_ "GenSigSwitchedByIgnition" SG_ 997 FT_Tuerschloss_verrieg_nicht 0;
BA_ "GenSigSendType" SG_ 997 FT_Tuerschloss_verrieg_nicht 0;
BA_ "GenSigSwitchedByIgnition" SG_ 997 FT_SP_Heizung_ein 0;
BA_ "GenSigSendType" SG_ 997 FT_SP_Heizung_ein 3;
BA_ "GenSigSwitchedByIgnition" SG_ 997 FT_Kisi_Taster_li_02 0;
BA_ "GenSigSendType" SG_ 997 FT_Kisi_Taster_li_02 3;
BA_ "GenSigSwitchedByIgnition" SG_ 997 FT_Kisi_Taster_re_02 0;
BA_ "GenSigSendType" SG_ 997 FT_Kisi_Taster_re_02 3;
BA_ "GenSigSwitchedByIgnition" SG_ 997 FT_TD_Taste_Status 0;
BA_ "GenSigSendType" SG_ 997 FT_TD_Taste_Status 3;
BA_ "GenSigSwitchedByIgnition" SG_ 288 TSK_06_CRC 0;
BA_ "GenSigFuncType" SG_ 288 TSK_06_CRC 2;
BA_ "GenSigSendType" SG_ 288 TSK_06_CRC 0;
BA_ "GenSigSwitchedByIgnition" SG_ 288 TSK_06_BZ 0;
BA_ "GenSigFuncType" SG_ 288 TSK_06_BZ 1;
BA_ "GenSigSendType" SG_ 288 TSK_06_BZ 0;
BA_ "GenSigSwitchedByIgnition" SG_ 288 TSK_Radbremsmom 0;
BA_ "GenSigSendType" SG_ 288 TSK_Radbremsmom 0;
BA_ "GenSigSwitchedByIgnition" SG_ 288 TSK_Status 0;
BA_ "GenSigStartValue" SG_ 288 TSK_Status 1;
BA_ "GenSigSendType" SG_ 288 TSK_Status 0;
BA_ "GenSigSwitchedByIgnition" SG_ 288 TSK_v_Begrenzung_aktiv 0;
BA_ "GenSigSendType" SG_ 288 TSK_v_Begrenzung_aktiv 0;
BA_ "GenSigSwitchedByIgnition" SG_ 288 TSK_Standby_Anf_ESP 0;
BA_ "GenSigSendType" SG_ 288 TSK_Standby_Anf_ESP 0;
BA_ "GenSigSwitchedByIgnition" SG_ 288 TSK_Freig_WU 0;
BA_ "GenSigSendType" SG_ 288 TSK_Freig_WU 0;
BA_ "GenSigSwitchedByIgnition" SG_ 288 TSK_Freig_Verzoeg_Anf 0;
BA_ "GenSigSendType" SG_ 288 TSK_Freig_Verzoeg_Anf 0;
BA_ "GenSigSwitchedByIgnition" SG_ 288 TSK_Limiter_ausgewaehlt 0;
BA_ "GenSigSendType" SG_ 288 TSK_Limiter_ausgewaehlt 0;
BA_ "GenSigSwitchedByIgnition" SG_ 288 TSK_Wunsch_Uebersetz 0;
BA_ "GenSigSendType" SG_ 288 TSK_Wunsch_Uebersetz 0;
BA_ "Fehlerwert" SG_ 288 TSK_Hauptschalter_GRA_ACC 3;
BA_ "GenSigSwitchedByIgnition" SG_ 288 TSK_Hauptschalter_GRA_ACC 0;
BA_ "GenSigSendType" SG_ 288 TSK_Hauptschalter_GRA_ACC 0;
BA_ "GenSigSwitchedByIgnition" SG_ 288 TSK_ax_Getriebe_02 0;
BA_ "GenSigStartValue" SG_ 288 TSK_ax_Getriebe_02 511;
BA_ "GenSigSendType" SG_ 288 TSK_ax_Getriebe_02 0;
BA_ "GenSigSwitchedByIgnition" SG_ 288 TSK_Zwangszusch_ESP 0;
BA_ "GenSigSendType" SG_ 288 TSK_Zwangszusch_ESP 0;
BA_ "GenSigSwitchedByIgnition" SG_ 288 TSK_zul_Regelabw 0;
BA_ "GenSigSendType" SG_ 288 TSK_zul_Regelabw 0;
BA_ "GenSigSwitchedByIgnition" SG_ 346 TSK_08_CRC 0;
BA_ "GenSigFuncType" SG_ 346 TSK_08_CRC 2;
BA_ "GenSigSendType" SG_ 346 TSK_08_CRC 0;
BA_ "GenSigSwitchedByIgnition" SG_ 346 TSK_08_BZ 0;
BA_ "GenSigFuncType" SG_ 346 TSK_08_BZ 1;
BA_ "GenSigSendType" SG_ 346 TSK_08_BZ 0;
BA_ "GenSigSwitchedByIgnition" SG_ 346 MO_Anforderung_HMS 0;
BA_ "GenSigSendType" SG_ 346 MO_Anforderung_HMS 3;
BA_ "GenSigSwitchedByIgnition" SG_ 346 TSK_Status_EA 0;
BA_ "GenSigStartValue" SG_ 346 TSK_Status_EA 1;
BA_ "GenSigSendType" SG_ 346 TSK_Status_EA 3;
BA_ "GenSigStartValue" SG_ 346 TSK_vMax_Fahrerassistenz 511;
BA_ "GenSigSendType" SG_ 346 TSK_vMax_Fahrerassistenz 0;
BA_ "GenSigSendType" SG_ 346 TSK_Einheit_vMax_Fahrerassistenz 0;
BA_ "Fehlerwert" SG_ 346 TSK_Status_PLA 7;
BA_ "GenSigSwitchedByIgnition" SG_ 346 TSK_Status_PLA 0;
BA_ "GenSigStartValue" SG_ 346 TSK_Status_PLA 1;
BA_ "GenSigSendType" SG_ 346 TSK_Status_PLA 3;
BA_ "GenSigSwitchedByIgnition" SG_ 346 TSK_aktives_System 0;
BA_ "GenSigSendType" SG_ 346 TSK_aktives_System 3;
BA_ "GenSigSendType" SG_ 346 TSK_erhoehter_Fahrwiderstand 3;
BA_ "GenSigSendType" SG_ 346 TSK_Anf_Antriebsmoment 3;
BA_ "Fehlerwert" SG_ 346 TSK_Status_ARA 7;
BA_ "GenSigSwitchedByIgnition" SG_ 346 TSK_Status_ARA 0;
BA_ "GenSigStartValue" SG_ 346 TSK_Status_ARA 1;
BA_ "GenSigSendType" SG_ 346 TSK_Status_ARA 3;
BA_ "Fehlerwert" SG_ 346 TSK_Status_IPA 7;
BA_ "GenSigSwitchedByIgnition" SG_ 346 TSK_Status_IPA 0;
BA_ "GenSigStartValue" SG_ 346 TSK_Status_IPA 1;
BA_ "GenSigSendType" SG_ 346 TSK_Status_IPA 3;
BA_ "GenSigSwitchedByIgnition" SG_ 1019 TSK_Ausrollkurve_Schub_Reku_01 0;
BA_ "GenSigStartValue" SG_ 1019 TSK_Ausrollkurve_Schub_Reku_01 127;
BA_ "GenSigSwitchedByIgnition" SG_ 1019 TSK_Ausrollkurve_Schub_Reku_05 0;
BA_ "GenSigStartValue" SG_ 1019 TSK_Ausrollkurve_Schub_Reku_05 127;
BA_ "GenSigSwitchedByIgnition" SG_ 1019 TSK_Ausrollkurve_Schub_Reku_09 0;
BA_ "GenSigStartValue" SG_ 1019 TSK_Ausrollkurve_Schub_Reku_09 127;
BA_ "GenSigSwitchedByIgnition" SG_ 1019 TSK_Ausrollkurve_Schub_Reku_13 0;
BA_ "GenSigStartValue" SG_ 1019 TSK_Ausrollkurve_Schub_Reku_13 127;
BA_ "GenSigSwitchedByIgnition" SG_ 1019 TSK_Ausrollkurve_Schub_Reku_17 0;
BA_ "GenSigStartValue" SG_ 1019 TSK_Ausrollkurve_Schub_Reku_17 127;
BA_ "GenSigSwitchedByIgnition" SG_ 1019 TSK_Ausrollkurve_Schub_Reku_02 0;
BA_ "GenSigStartValue" SG_ 1019 TSK_Ausrollkurve_Schub_Reku_02 127;
BA_ "GenSigSwitchedByIgnition" SG_ 1019 TSK_Ausrollkurve_Schub_Reku_06 0;
BA_ "GenSigStartValue" SG_ 1019 TSK_Ausrollkurve_Schub_Reku_06 127;
BA_ "GenSigSwitchedByIgnition" SG_ 1019 TSK_Ausrollkurve_Schub_Reku_10 0;
BA_ "GenSigStartValue" SG_ 1019 TSK_Ausrollkurve_Schub_Reku_10 127;
BA_ "GenSigSwitchedByIgnition" SG_ 1019 TSK_Ausrollkurve_Schub_Reku_14 0;
BA_ "GenSigStartValue" SG_ 1019 TSK_Ausrollkurve_Schub_Reku_14 127;
BA_ "GenSigSwitchedByIgnition" SG_ 1019 TSK_Ausrollkurve_Schub_Reku_18 0;
BA_ "GenSigStartValue" SG_ 1019 TSK_Ausrollkurve_Schub_Reku_18 127;
BA_ "GenSigSwitchedByIgnition" SG_ 1019 TSK_Ausrollkurve_Schub_Reku_03 0;
BA_ "GenSigStartValue" SG_ 1019 TSK_Ausrollkurve_Schub_Reku_03 127;
BA_ "GenSigSwitchedByIgnition" SG_ 1019 TSK_Ausrollkurve_Schub_Reku_07 0;
BA_ "GenSigStartValue" SG_ 1019 TSK_Ausrollkurve_Schub_Reku_07 127;
BA_ "GenSigSwitchedByIgnition" SG_ 1019 TSK_Ausrollkurve_Schub_Reku_11 0;
BA_ "GenSigStartValue" SG_ 1019 TSK_Ausrollkurve_Schub_Reku_11 127;
BA_ "GenSigSwitchedByIgnition" SG_ 1019 TSK_Ausrollkurve_Schub_Reku_15 0;
BA_ "GenSigStartValue" SG_ 1019 TSK_Ausrollkurve_Schub_Reku_15 127;
BA_ "GenSigSwitchedByIgnition" SG_ 1019 TSK_Ausrollkurve_Schub_Reku_19 0;
BA_ "GenSigStartValue" SG_ 1019 TSK_Ausrollkurve_Schub_Reku_19 127;
BA_ "GenSigSwitchedByIgnition" SG_ 1019 TSK_Ausrollkurve_Schub_Reku_04 0;
BA_ "GenSigStartValue" SG_ 1019 TSK_Ausrollkurve_Schub_Reku_04 127;
BA_ "GenSigSwitchedByIgnition" SG_ 1019 TSK_Ausrollkurve_Schub_Reku_08 0;
BA_ "GenSigStartValue" SG_ 1019 TSK_Ausrollkurve_Schub_Reku_08 127;
BA_ "GenSigSwitchedByIgnition" SG_ 1019 TSK_Ausrollkurve_Schub_Reku_12 0;
BA_ "GenSigStartValue" SG_ 1019 TSK_Ausrollkurve_Schub_Reku_12 127;
BA_ "GenSigSwitchedByIgnition" SG_ 1019 TSK_Ausrollkurve_Schub_Reku_16 0;
BA_ "GenSigStartValue" SG_ 1019 TSK_Ausrollkurve_Schub_Reku_16 127;
BA_ "GenSigSwitchedByIgnition" SG_ 1019 TSK_Ausrollkurve_Schub_Reku_20 0;
BA_ "GenSigStartValue" SG_ 1019 TSK_Ausrollkurve_Schub_Reku_20 127;
BA_ "GenSigSwitchedByIgnition" SG_ 1019 TSK_Ausrollkurve_Segeln_01 0;
BA_ "GenSigStartValue" SG_ 1019 TSK_Ausrollkurve_Segeln_01 127;
BA_ "GenSigSwitchedByIgnition" SG_ 1019 TSK_Ausrollkurve_Segeln_05 0;
BA_ "GenSigStartValue" SG_ 1019 TSK_Ausrollkurve_Segeln_05 127;
BA_ "GenSigSwitchedByIgnition" SG_ 1019 TSK_Ausrollkurve_Segeln_09 0;
BA_ "GenSigStartValue" SG_ 1019 TSK_Ausrollkurve_Segeln_09 127;
BA_ "GenSigSwitchedByIgnition" SG_ 1019 TSK_Ausrollkurve_Segeln_13 0;
BA_ "GenSigStartValue" SG_ 1019 TSK_Ausrollkurve_Segeln_13 127;
BA_ "GenSigSwitchedByIgnition" SG_ 1019 TSK_Ausrollkurve_Segeln_17 0;
BA_ "GenSigStartValue" SG_ 1019 TSK_Ausrollkurve_Segeln_17 127;
BA_ "GenSigSwitchedByIgnition" SG_ 1019 TSK_Ausrollkurve_Segeln_02 0;
BA_ "GenSigStartValue" SG_ 1019 TSK_Ausrollkurve_Segeln_02 127;
BA_ "GenSigSwitchedByIgnition" SG_ 1019 TSK_Ausrollkurve_Segeln_06 0;
BA_ "GenSigStartValue" SG_ 1019 TSK_Ausrollkurve_Segeln_06 127;
BA_ "GenSigSwitchedByIgnition" SG_ 1019 TSK_Ausrollkurve_Segeln_10 0;
BA_ "GenSigStartValue" SG_ 1019 TSK_Ausrollkurve_Segeln_10 127;
BA_ "GenSigSwitchedByIgnition" SG_ 1019 TSK_Ausrollkurve_Segeln_14 0;
BA_ "GenSigStartValue" SG_ 1019 TSK_Ausrollkurve_Segeln_14 127;
BA_ "GenSigSwitchedByIgnition" SG_ 1019 TSK_Ausrollkurve_Segeln_18 0;
BA_ "GenSigStartValue" SG_ 1019 TSK_Ausrollkurve_Segeln_18 127;
BA_ "GenSigSwitchedByIgnition" SG_ 1019 TSK_Ausrollkurve_Segeln_03 0;
BA_ "GenSigStartValue" SG_ 1019 TSK_Ausrollkurve_Segeln_03 127;
BA_ "GenSigSwitchedByIgnition" SG_ 1019 TSK_Ausrollkurve_Segeln_07 0;
BA_ "GenSigStartValue" SG_ 1019 TSK_Ausrollkurve_Segeln_07 127;
BA_ "GenSigSwitchedByIgnition" SG_ 1019 TSK_Ausrollkurve_Segeln_11 0;
BA_ "GenSigStartValue" SG_ 1019 TSK_Ausrollkurve_Segeln_11 127;
BA_ "GenSigSwitchedByIgnition" SG_ 1019 TSK_Ausrollkurve_Segeln_15 0;
BA_ "GenSigStartValue" SG_ 1019 TSK_Ausrollkurve_Segeln_15 127;
BA_ "GenSigSwitchedByIgnition" SG_ 1019 TSK_Ausrollkurve_Segeln_19 0;
BA_ "GenSigStartValue" SG_ 1019 TSK_Ausrollkurve_Segeln_19 127;
BA_ "GenSigSwitchedByIgnition" SG_ 1019 TSK_Ausrollkurve_Segeln_04 0;
BA_ "GenSigStartValue" SG_ 1019 TSK_Ausrollkurve_Segeln_04 127;
BA_ "GenSigSwitchedByIgnition" SG_ 1019 TSK_Ausrollkurve_Segeln_08 0;
BA_ "GenSigStartValue" SG_ 1019 TSK_Ausrollkurve_Segeln_08 127;
BA_ "GenSigSwitchedByIgnition" SG_ 1019 TSK_Ausrollkurve_Segeln_12 0;
BA_ "GenSigStartValue" SG_ 1019 TSK_Ausrollkurve_Segeln_12 127;
BA_ "GenSigSwitchedByIgnition" SG_ 1019 TSK_Ausrollkurve_Segeln_16 0;
BA_ "GenSigStartValue" SG_ 1019 TSK_Ausrollkurve_Segeln_16 127;
BA_ "GenSigSwitchedByIgnition" SG_ 1019 TSK_Ausrollkurve_Segeln_20 0;
BA_ "GenSigStartValue" SG_ 1019 TSK_Ausrollkurve_Segeln_20 127;
BA_ "GenSigSwitchedByIgnition" SG_ 1019 TSK_Ausrollkurve_Mux 0;
BA_ "GenSigSendType" SG_ 1019 TSK_Ausrollkurve_Mux 0;
BA_ "GenSigSwitchedByIgnition" SG_ 1019 TSK_Ausrollkurve_Reku 0;
BA_ "GenSigSendType" SG_ 1019 TSK_Ausrollkurve_Reku 0;
BA_ "GenSigSwitchedByIgnition" SG_ 1019 TSK_Ausrollkurve_Schrittweite 0;
BA_ "GenSigSendType" SG_ 1019 TSK_Ausrollkurve_Schrittweite 0;
BA_ "GenSigSwitchedByIgnition" SG_ 1019 TSK_Ausrollkurve_Zaehler 0;
BA_ "GenSigSendType" SG_ 1019 TSK_Ausrollkurve_Zaehler 0;
BA_ "GenSigSwitchedByIgnition" SG_ 1716 VIN_01_MUX 0;
BA_ "GenSigSendType" SG_ 1716 VIN_01_MUX 0;
BA_ "GenSigSwitchedByIgnition" SG_ 1716 KS_Geheimnis_1 0;
BA_ "GenSigSwitchedByIgnition" SG_ 1716 VIN_4 0;
BA_ "GenSigStartValue" SG_ 1716 VIN_4 45;
BA_ "GenSigSwitchedByIgnition" SG_ 1716 VIN_11 0;
BA_ "GenSigStartValue" SG_ 1716 VIN_11 45;
BA_ "GenSigSwitchedByIgnition" SG_ 1716 KS_Geheimnis_2 0;
BA_ "GenSigSwitchedByIgnition" SG_ 1716 VIN_5 0;
BA_ "GenSigStartValue" SG_ 1716 VIN_5 45;
BA_ "GenSigSwitchedByIgnition" SG_ 1716 VIN_12 0;
BA_ "GenSigStartValue" SG_ 1716 VIN_12 45;
BA_ "GenSigSwitchedByIgnition" SG_ 1716 KS_Geheimnis_3 0;
BA_ "GenSigSwitchedByIgnition" SG_ 1716 VIN_6 0;
BA_ "GenSigStartValue" SG_ 1716 VIN_6 45;
BA_ "GenSigSwitchedByIgnition" SG_ 1716 VIN_13 0;
BA_ "GenSigStartValue" SG_ 1716 VIN_13 45;
BA_ "GenSigSwitchedByIgnition" SG_ 1716 KS_Geheimnis_4 0;
BA_ "GenSigSwitchedByIgnition" SG_ 1716 VIN_7 0;
BA_ "GenSigStartValue" SG_ 1716 VIN_7 45;
BA_ "GenSigSwitchedByIgnition" SG_ 1716 VIN_14 0;
BA_ "GenSigStartValue" SG_ 1716 VIN_14 45;
BA_ "GenSigSwitchedByIgnition" SG_ 1716 VIN_1 0;
BA_ "GenSigStartValue" SG_ 1716 VIN_1 45;
BA_ "GenSigSwitchedByIgnition" SG_ 1716 VIN_8 0;
BA_ "GenSigStartValue" SG_ 1716 VIN_8 45;
BA_ "GenSigSwitchedByIgnition" SG_ 1716 VIN_15 0;
BA_ "GenSigStartValue" SG_ 1716 VIN_15 45;
BA_ "GenSigSwitchedByIgnition" SG_ 1716 VIN_2 0;
BA_ "GenSigStartValue" SG_ 1716 VIN_2 45;
BA_ "GenSigSwitchedByIgnition" SG_ 1716 VIN_9 0;
BA_ "GenSigStartValue" SG_ 1716 VIN_9 45;
BA_ "GenSigSwitchedByIgnition" SG_ 1716 VIN_16 0;
BA_ "GenSigStartValue" SG_ 1716 VIN_16 45;
BA_ "GenSigSwitchedByIgnition" SG_ 1716 VIN_3 0;
BA_ "GenSigStartValue" SG_ 1716 VIN_3 45;
BA_ "GenSigSwitchedByIgnition" SG_ 1716 VIN_10 0;
BA_ "GenSigStartValue" SG_ 1716 VIN_10 45;
BA_ "GenSigSwitchedByIgnition" SG_ 1716 VIN_17 0;
BA_ "GenSigStartValue" SG_ 1716 VIN_17 45;
BA_ "GenSigSendType" SG_ 385 VZE_Anzeigemodus 3;
BA_ "GenSigSendType" SG_ 385 VZE_Hinweistext 3;
BA_ "GenSigSendType" SG_ 385 VZE_Statuszaehler_1 3;
BA_ "GenSigSendType" SG_ 385 VZE_Statuszaehler_2 3;
BA_ "GenSigSendType" SG_ 385 VZE_Statuszaehler_3 3;
BA_ "GenSigSendType" SG_ 385 VZE_Verkehrszeichen_1 3;
BA_ "GenSigSendType" SG_ 385 VZE_Verkehrszeichen_2 3;
BA_ "GenSigSendType" SG_ 385 VZE_Verkehrszeichen_3 3;
BA_ "GenSigSendType" SG_ 385 VZE_Warnung_Verkehrszeichen_1 3;
BA_ "GenSigSendType" SG_ 385 VZE_Warnung_Verkehrszeichen_2 3;
BA_ "GenSigSendType" SG_ 385 VZE_Warnung_Verkehrszeichen_3 3;
BA_ "GenSigSendType" SG_ 385 VZE_Zusatzschild_1 3;
BA_ "GenSigSendType" SG_ 385 VZE_Zusatzschild_2 3;
BA_ "GenSigSendType" SG_ 385 VZE_Zusatzschild_3 3;
BA_ "GenSigSendType" SG_ 385 VZE_Hinweistext_02 0;
BA_ "GenSigSendType" SG_ 668 VZE_Statuszaehler_4 3;
BA_ "GenSigSendType" SG_ 668 VZE_Statuszaehler_5 3;
BA_ "GenSigSendType" SG_ 668 VZE_Zeichen_05_KameraWied 3;
BA_ "GenSigSendType" SG_ 668 VZE_Zeichen_05_Kamera 3;
BA_ "GenSigSendType" SG_ 668 VZE_Verkehrszeichen_4 3;
BA_ "GenSigSendType" SG_ 668 VZE_Verkehrszeichen_5 3;
BA_ "Fehlerwert" SG_ 668 VZE_Anhaenger_Vmax 15;
BA_ "GenSigStartValue" SG_ 668 VZE_Anhaenger_Vmax 14;
BA_ "GenSigSendType" SG_ 668 VZE_Anhaenger_Vmax 3;
BA_ "GenSigSendType" SG_ 668 VZE_Zeichen_04_Gesetz 3;
BA_ "GenSigSendType" SG_ 668 VZE_Zeichen_04_Kamera 3;
BA_ "GenSigSendType" SG_ 668 VZE_Zeichen_04_KameraWied 3;
BA_ "GenSigSendType" SG_ 668 VZE_Zeichen_04_Karte 3;
BA_ "GenSigSendType" SG_ 668 VZE_Warnung_Verkehrszeichen_4 3;
BA_ "GenSigSendType" SG_ 668 VZE_Warnung_Verkehrszeichen_5 3;
BA_ "GenSigSendType" SG_ 668 VZE_Zeichen_05_Gesetz 3;
BA_ "GenSigSendType" SG_ 668 VZE_Zusatzschild_4 3;
BA_ "GenSigSendType" SG_ 668 VZE_Zusatzschild_5 3;
BA_ "GenSigSendType" SG_ 668 VZE_Baustelle 3;
BA_ "GenSigSendType" SG_ 668 VZE_Zeichen_05_Karte 3;
BA_REL_ "GenSigTimeoutTime" BU_SG_REL_ Frontsensorik SG_ 930 PSD_Multiplex 1500;
BA_REL_ "GenSigTimeoutTime" BU_SG_REL_ Frontsensorik SG_ 930 PSD_Sys_Segment_ID 1500;
BA_REL_ "GenSigTimeoutTime" BU_SG_REL_ Frontsensorik SG_ 930 PSD_Abz_Segment_ID 1500;
BA_REL_ "GenSigTimeoutTime" BU_SG_REL_ Frontsensorik SG_ 930 PSD_Ges_Segment_ID 1500;
BA_REL_ "GenSigTimeoutTime" BU_SG_REL_ Frontsensorik SG_ 930 PSD_Ort_Laenge_VZ 1500;
BA_REL_ "GenSigTimeoutTime" BU_SG_REL_ Frontsensorik SG_ 930 PSD_Ort_Laenge 1500;
BA_REL_ "GenSigTimeoutTime" BU_SG_REL_ Frontsensorik SG_ 930 PSD_Sys_Laendercode 1500;
BA_REL_ "GenSigTimeoutTime" BU_SG_REL_ Frontsensorik SG_ 930 PSD_Abz_Segmentlaenge 1500;
BA_REL_ "GenSigTimeoutTime" BU_SG_REL_ Frontsensorik SG_ 930 PSD_Ges_Geschwindigkeit 1500;
BA_REL_ "GenSigTimeoutTime" BU_SG_REL_ Frontsensorik SG_ 930 PSD_Ges_Geschwindigkeit_Typ 1500;
BA_REL_ "GenSigTimeoutTime" BU_SG_REL_ Frontsensorik SG_ 930 PSD_Ges_Geschwindigkeit_Gespann 1500;
BA_REL_ "GenSigTimeoutTime" BU_SG_REL_ Frontsensorik SG_ 930 PSD_Abz_Vorgaenger_Segment_ID 1500;
BA_REL_ "GenSigTimeoutTime" BU_SG_REL_ Frontsensorik SG_ 930 PSD_Sys_Geschwindigkeit_Einheit 1500;
BA_REL_ "GenSigTimeoutTime" BU_SG_REL_ Frontsensorik SG_ 930 PSD_Ges_Geschwindigkeit_Witter 1500;
BA_REL_ "GenSigTimeoutTime" BU_SG_REL_ Frontsensorik SG_ 930 PSD_Sys_Verkehrsrichtung 1500;
BA_REL_ "GenSigTimeoutTime" BU_SG_REL_ Frontsensorik SG_ 930 PSD_Sys_Release_Monat 1500;
BA_REL_ "GenSigTimeoutTime" BU_SG_REL_ Frontsensorik SG_ 930 PSD_Ges_Geschwindigkeit_Tag_Anf 1500;
BA_REL_ "GenSigTimeoutTime" BU_SG_REL_ Frontsensorik SG_ 930 PSD_Abz_Geschwindigkeit 1500;
BA_REL_ "GenSigTimeoutTime" BU_SG_REL_ Frontsensorik SG_ 930 PSD_Ges_Geschwindigkeit_Tag_Ende 1500;
BA_REL_ "GenSigTimeoutTime" BU_SG_REL_ Frontsensorik SG_ 930 PSD_Sys_Release_Jahr 1500;
BA_REL_ "GenSigTimeoutTime" BU_SG_REL_ Frontsensorik SG_ 930 PSD_Ges_Geschwindigkeit_Std_Anf 1500;
BA_REL_ "GenSigTimeoutTime" BU_SG_REL_ Frontsensorik SG_ 930 PSD_Abz_Geschwindigkeit_Typ 1500;
BA_REL_ "GenSigTimeoutTime" BU_SG_REL_ Frontsensorik SG_ 930 PSD_Sys_Tunnel 1500;
BA_REL_ "GenSigTimeoutTime" BU_SG_REL_ Frontsensorik SG_ 930 PSD_Abz_Strassenklasse 1500;
BA_REL_ "GenSigTimeoutTime" BU_SG_REL_ Frontsensorik SG_ 930 PSD_Sys_Bruecke 1500;
BA_REL_ "GenSigTimeoutTime" BU_SG_REL_ Frontsensorik SG_ 930 PSD_Ort_Breite_VZ 1500;
BA_REL_ "GenSigTimeoutTime" BU_SG_REL_ Frontsensorik SG_ 930 PSD_Sys_Fahrsp_Gegenr 1500;
BA_REL_ "GenSigTimeoutTime" BU_SG_REL_ Frontsensorik SG_ 930 PSD_Abz_ADAS_Qualitaet 1500;
BA_REL_ "GenSigTimeoutTime" BU_SG_REL_ Frontsensorik SG_ 930 PSD_Ges_Geschwindigkeit_Std_Ende 1500;
BA_REL_ "GenSigTimeoutTime" BU_SG_REL_ Frontsensorik SG_ 930 PSD_Ort_Breite 1500;
BA_REL_ "GenSigTimeoutTime" BU_SG_REL_ Frontsensorik SG_ 930 PSD_Abz_Abzweigerichtung 1500;
BA_REL_ "GenSigTimeoutTime" BU_SG_REL_ Frontsensorik SG_ 930 PSD_Sys_TMC_Baustelle 1500;
BA_REL_ "GenSigTimeoutTime" BU_SG_REL_ Frontsensorik SG_ 930 PSD_Abz_Abzweigewinkel 1500;
BA_REL_ "GenSigTimeoutTime" BU_SG_REL_ Frontsensorik SG_ 930 PSD_Sys_TMC_Stau 1500;
BA_REL_ "GenSigTimeoutTime" BU_SG_REL_ Frontsensorik SG_ 930 PSD_Sys_Bauliche_Trennung 1500;
BA_REL_ "GenSigTimeoutTime" BU_SG_REL_ Frontsensorik SG_ 930 PSD_Ges_alter_Geschw 1500;
BA_REL_ "GenSigTimeoutTime" BU_SG_REL_ Frontsensorik SG_ 930 PSD_Sys_Geometrieguete 1500;
BA_REL_ "GenSigTimeoutTime" BU_SG_REL_ Frontsensorik SG_ 930 PSD_Abz_Rampe 1500;
BA_REL_ "GenSigTimeoutTime" BU_SG_REL_ Frontsensorik SG_ 930 PSD_Sys_Maut 1500;
BA_REL_ "GenSigTimeoutTime" BU_SG_REL_ Frontsensorik SG_ 930 PSD_Abz_Anfangskruemmung 1500;
BA_REL_ "GenSigTimeoutTime" BU_SG_REL_ Frontsensorik SG_ 930 PSD_Sys_Strassensituation 1500;
BA_REL_ "GenSigTimeoutTime" BU_SG_REL_ Frontsensorik SG_ 930 PSD_Ges_alter_Geschw_Gespann 1500;
BA_REL_ "GenSigTimeoutTime" BU_SG_REL_ Frontsensorik SG_ 930 PSD_Sys_StrKlassen_erweitert 1500;
BA_REL_ "GenSigTimeoutTime" BU_SG_REL_ Frontsensorik SG_ 930 PSD_Ges_alter_Geschw_Witter 1500;
BA_REL_ "GenSigTimeoutTime" BU_SG_REL_ Frontsensorik SG_ 930 PSD_Sys_Ortsschild 1500;
BA_REL_ "GenSigTimeoutTime" BU_SG_REL_ Frontsensorik SG_ 930 PSD_Ges_alter_Geschw_Tag_Anf 1500;
BA_REL_ "GenSigTimeoutTime" BU_SG_REL_ Frontsensorik SG_ 930 PSD_Abz_Anfangskruemmung_Vorz 1500;
BA_REL_ "GenSigTimeoutTime" BU_SG_REL_ Frontsensorik SG_ 930 PSD_Sys_Anfangskruemmung 1500;
BA_REL_ "GenSigTimeoutTime" BU_SG_REL_ Frontsensorik SG_ 930 PSD_Abz_Endkruemmung 1500;
BA_REL_ "GenSigTimeoutTime" BU_SG_REL_ Frontsensorik SG_ 930 PSD_Ges_alter_Geschw_Tag_Ende 1500;
BA_REL_ "GenSigTimeoutTime" BU_SG_REL_ Frontsensorik SG_ 930 PSD_Ges_alter_Geschw_Std_Anf 1500;
BA_REL_ "GenSigTimeoutTime" BU_SG_REL_ Frontsensorik SG_ 930 PSD_Ort_Hoehe 1500;
BA_REL_ "GenSigTimeoutTime" BU_SG_REL_ Frontsensorik SG_ 930 PSD_Sys_Anfangskruemmung_Vorz 1500;
BA_REL_ "GenSigTimeoutTime" BU_SG_REL_ Frontsensorik SG_ 930 PSD_Abz_Endkruemmung_Vorz 1500;
BA_REL_ "GenSigTimeoutTime" BU_SG_REL_ Frontsensorik SG_ 930 PSD_Ges_alter_Geschw_Std_Ende 1500;
BA_REL_ "GenSigTimeoutTime" BU_SG_REL_ Frontsensorik SG_ 930 PSD_Sys_Anfangssteigung 1500;
BA_REL_ "GenSigTimeoutTime" BU_SG_REL_ Frontsensorik SG_ 930 PSD_Abz_Endsteigung 1500;
BA_REL_ "GenSigTimeoutTime" BU_SG_REL_ Frontsensorik SG_ 930 PSD_Ges_Ueberholverbot 1500;
BA_REL_ "GenSigTimeoutTime" BU_SG_REL_ Frontsensorik SG_ 930 PSD_Sys_Anfangssteigung_Vorz 1500;
BA_REL_ "GenSigTimeoutTime" BU_SG_REL_ Frontsensorik SG_ 930 PSD_Abz_Endsteigung_Vorz 1500;
BA_REL_ "GenSigTimeoutTime" BU_SG_REL_ Frontsensorik SG_ 930 PSD_Sys_Ortschaft 1500;
BA_REL_ "GenSigTimeoutTime" BU_SG_REL_ Frontsensorik SG_ 930 PSD_Abz_Fahrspuren 1500;
BA_REL_ "GenSigTimeoutTime" BU_SG_REL_ Frontsensorik SG_ 930 PSD_Ges_Wechselverkehrszeichen 1500;
BA_REL_ "GenSigTimeoutTime" BU_SG_REL_ Frontsensorik SG_ 930 PSD_Sys_Digitalisierung 1500;
BA_REL_ "GenSigTimeoutTime" BU_SG_REL_ Frontsensorik SG_ 930 PSD_Sys_Zielfuehrung 1500;
BA_REL_ "GenSigTimeoutTime" BU_SG_REL_ Frontsensorik SG_ 930 PSD_Abz_wahrscheinlichster_Pfad 1500;
BA_REL_ "GenSigTimeoutTime" BU_SG_REL_ Frontradar SG_ 1122 PSD_Segment_ID 1500;
BA_REL_ "GenSigTimeoutTime" BU_SG_REL_ Frontsensorik SG_ 1122 PSD_Segment_ID 1500;
BA_REL_ "GenSigTimeoutTime" BU_SG_REL_ Frontradar SG_ 1122 PSD_Vorgaenger_Segment_ID 1500;
BA_REL_ "GenSigTimeoutTime" BU_SG_REL_ Frontsensorik SG_ 1122 PSD_Vorgaenger_Segment_ID 1500;
BA_REL_ "GenSigTimeoutTime" BU_SG_REL_ Frontradar SG_ 1122 PSD_Segmentlaenge 1500;
BA_REL_ "GenSigTimeoutTime" BU_SG_REL_ Frontsensorik SG_ 1122 PSD_Segmentlaenge 1500;
BA_REL_ "GenSigTimeoutTime" BU_SG_REL_ Frontradar SG_ 1122 PSD_Strassenkategorie 1500;
BA_REL_ "GenSigTimeoutTime" BU_SG_REL_ Frontsensorik SG_ 1122 PSD_Strassenkategorie 1500;
BA_REL_ "GenSigTimeoutTime" BU_SG_REL_ Frontradar SG_ 1122 PSD_Endkruemmung 1500;
BA_REL_ "GenSigTimeoutTime" BU_SG_REL_ Frontsensorik SG_ 1122 PSD_Endkruemmung 1500;
BA_REL_ "GenSigTimeoutTime" BU_SG_REL_ Frontradar SG_ 1122 PSD_Endkruemmung_Vorz 1500;
BA_REL_ "GenSigTimeoutTime" BU_SG_REL_ Frontsensorik SG_ 1122 PSD_Endkruemmung_Vorz 1500;
BA_REL_ "GenSigTimeoutTime" BU_SG_REL_ Frontradar SG_ 1122 PSD_Idenditaets_ID 1500;
BA_REL_ "GenSigTimeoutTime" BU_SG_REL_ Frontsensorik SG_ 1122 PSD_Idenditaets_ID 1500;
BA_REL_ "GenSigTimeoutTime" BU_SG_REL_ Frontradar SG_ 1122 PSD_ADAS_Qualitaet 1500;
BA_REL_ "GenSigTimeoutTime" BU_SG_REL_ Frontsensorik SG_ 1122 PSD_ADAS_Qualitaet 1500;
BA_REL_ "GenSigTimeoutTime" BU_SG_REL_ Frontradar SG_ 1122 PSD_wahrscheinlichster_Pfad 1500;
BA_REL_ "GenSigTimeoutTime" BU_SG_REL_ Frontsensorik SG_ 1122 PSD_wahrscheinlichster_Pfad 1500;
BA_REL_ "GenSigTimeoutTime" BU_SG_REL_ Frontradar SG_ 1122 PSD_Geradester_Pfad 1500;
BA_REL_ "GenSigTimeoutTime" BU_SG_REL_ Frontsensorik SG_ 1122 PSD_Geradester_Pfad 1500;
BA_REL_ "GenSigTimeoutTime" BU_SG_REL_ Frontradar SG_ 1122 PSD_Fahrspuren_Anzahl 1500;
BA_REL_ "GenSigTimeoutTime" BU_SG_REL_ Frontsensorik SG_ 1122 PSD_Fahrspuren_Anzahl 1500;
BA_REL_ "GenSigTimeoutTime" BU_SG_REL_ Frontradar SG_ 1122 PSD_Bebauung 1500;
BA_REL_ "GenSigTimeoutTime" BU_SG_REL_ Frontsensorik SG_ 1122 PSD_Bebauung 1500;
BA_REL_ "GenSigTimeoutTime" BU_SG_REL_ Frontradar SG_ 1122 PSD_Segment_Komplett 1500;
BA_REL_ "GenSigTimeoutTime" BU_SG_REL_ Frontsensorik SG_ 1122 PSD_Segment_Komplett 1500;
BA_REL_ "GenSigTimeoutTime" BU_SG_REL_ Frontradar SG_ 1122 PSD_Rampe 1500;
BA_REL_ "GenSigTimeoutTime" BU_SG_REL_ Frontsensorik SG_ 1122 PSD_Rampe 1500;
BA_REL_ "GenSigTimeoutTime" BU_SG_REL_ Frontradar SG_ 1122 PSD_Anfangskruemmung 1500;
BA_REL_ "GenSigTimeoutTime" BU_SG_REL_ Frontsensorik SG_ 1122 PSD_Anfangskruemmung 1500;
BA_REL_ "GenSigTimeoutTime" BU_SG_REL_ Frontradar SG_ 1122 PSD_Anfangskruemmung_Vorz 1500;
BA_REL_ "GenSigTimeoutTime" BU_SG_REL_ Frontsensorik SG_ 1122 PSD_Anfangskruemmung_Vorz 1500;
BA_REL_ "GenSigTimeoutTime" BU_SG_REL_ Frontradar SG_ 1122 PSD_Abzweigerichtung 1500;
BA_REL_ "GenSigTimeoutTime" BU_SG_REL_ Frontsensorik SG_ 1122 PSD_Abzweigerichtung 1500;
BA_REL_ "GenSigTimeoutTime" BU_SG_REL_ Frontradar SG_ 1122 PSD_Abzweigewinkel 1500;
BA_REL_ "GenSigTimeoutTime" BU_SG_REL_ Frontsensorik SG_ 1122 PSD_Abzweigewinkel 1500;
BA_REL_ "GenSigTimeoutTime" BU_SG_REL_ Frontradar SG_ 1123 PSD_Pos_Segment_ID 1500;
BA_REL_ "GenSigTimeoutTime" BU_SG_REL_ Frontsensorik SG_ 1123 PSD_Pos_Segment_ID 1500;
BA_REL_ "GenSigTimeoutTime" BU_SG_REL_ Frontradar SG_ 1123 PSD_Pos_Segmentlaenge 1500;
BA_REL_ "GenSigTimeoutTime" BU_SG_REL_ Frontsensorik SG_ 1123 PSD_Pos_Segmentlaenge 1500;
BA_REL_ "GenSigTimeoutTime" BU_SG_REL_ Frontradar SG_ 1123 PSD_Pos_Inhibitzeit 1500;
BA_REL_ "GenSigTimeoutTime" BU_SG_REL_ Frontsensorik SG_ 1123 PSD_Pos_Inhibitzeit 1500;
BA_REL_ "GenSigTimeoutTime" BU_SG_REL_ Frontradar SG_ 1123 PSD_Pos_Standort_Eindeutig 1500;
BA_REL_ "GenSigTimeoutTime" BU_SG_REL_ Frontsensorik SG_ 1123 PSD_Pos_Standort_Eindeutig 1500;
BA_REL_ "GenSigTimeoutTime" BU_SG_REL_ Frontradar SG_ 1123 PSD_Pos_Fehler_Laengsrichtung 1500;
BA_REL_ "GenSigTimeoutTime" BU_SG_REL_ Frontsensorik SG_ 1123 PSD_Pos_Fehler_Laengsrichtung 1500;
BA_REL_ "GenSigTimeoutTime" BU_SG_REL_ Frontradar SG_ 1123 PSD_Pos_Fahrspur 1500;
BA_REL_ "GenSigTimeoutTime" BU_SG_REL_ Frontsensorik SG_ 1123 PSD_Pos_Fahrspur 1500;
BA_REL_ "GenSigTimeoutTime" BU_SG_REL_ Frontradar SG_ 1123 PSD_Attribut_Segment_ID_05 1500;
BA_REL_ "GenSigTimeoutTime" BU_SG_REL_ Frontsensorik SG_ 1123 PSD_Attribut_Segment_ID_05 1500;
BA_REL_ "GenSigTimeoutTime" BU_SG_REL_ Frontradar SG_ 1123 PSD_Attribut_1_ID 1500;
BA_REL_ "GenSigTimeoutTime" BU_SG_REL_ Frontsensorik SG_ 1123 PSD_Attribut_1_ID 1500;
BA_REL_ "GenSigTimeoutTime" BU_SG_REL_ Frontradar SG_ 1123 PSD_Attribut_1_Wert 1500;
BA_REL_ "GenSigTimeoutTime" BU_SG_REL_ Frontsensorik SG_ 1123 PSD_Attribut_1_Wert 1500;
BA_REL_ "GenSigTimeoutTime" BU_SG_REL_ Frontradar SG_ 1123 PSD_Attribut_1_Offset 1500;
BA_REL_ "GenSigTimeoutTime" BU_SG_REL_ Frontsensorik SG_ 1123 PSD_Attribut_1_Offset 1500;
BA_REL_ "GenSigTimeoutTime" BU_SG_REL_ Frontradar SG_ 1123 PSD_Attribut_2_ID 1500;
BA_REL_ "GenSigTimeoutTime" BU_SG_REL_ Frontsensorik SG_ 1123 PSD_Attribut_2_ID 1500;
BA_REL_ "GenSigTimeoutTime" BU_SG_REL_ Frontradar SG_ 1123 PSD_Attribut_2_Wert 1500;
BA_REL_ "GenSigTimeoutTime" BU_SG_REL_ Frontsensorik SG_ 1123 PSD_Attribut_2_Wert 1500;
BA_REL_ "GenSigTimeoutTime" BU_SG_REL_ Frontradar SG_ 1123 PSD_Attribut_2_Offset 1500;
BA_REL_ "GenSigTimeoutTime" BU_SG_REL_ Frontsensorik SG_ 1123 PSD_Attribut_2_Offset 1500;
BA_REL_ "GenSigTimeoutTime" BU_SG_REL_ Frontradar SG_ 1123 PSD_Attribute_Komplett_05 1500;
BA_REL_ "GenSigTimeoutTime" BU_SG_REL_ Frontsensorik SG_ 1123 PSD_Attribute_Komplett_05 1500;
BA_REL_ "GenSigTimeoutTime" BU_SG_REL_ Frontradar SG_ 1124 PSD_06_Mux 1500;
BA_REL_ "GenSigTimeoutTime" BU_SG_REL_ Frontsensorik SG_ 1124 PSD_06_Mux 1500;
BA_REL_ "GenSigTimeoutTime" BU_SG_REL_ Frontradar SG_ 1124 PSD_Sys_Segment_ID 1500;
BA_REL_ "GenSigTimeoutTime" BU_SG_REL_ Frontsensorik SG_ 1124 PSD_Sys_Segment_ID 1500;
BA_REL_ "GenSigTimeoutTime" BU_SG_REL_ Frontradar SG_ 1124 PSD_Attribut_Segment_ID 1500;
BA_REL_ "GenSigTimeoutTime" BU_SG_REL_ Frontsensorik SG_ 1124 PSD_Attribut_Segment_ID 1500;
BA_REL_ "GenSigTimeoutTime" BU_SG_REL_ Frontradar SG_ 1124 PSD_Ges_Segment_ID 1500;
BA_REL_ "GenSigTimeoutTime" BU_SG_REL_ Frontsensorik SG_ 1124 PSD_Ges_Segment_ID 1500;
BA_REL_ "GenSigTimeoutTime" BU_SG_REL_ Frontradar SG_ 1124 PSD_Baum_Laenge_VZ 1500;
BA_REL_ "GenSigTimeoutTime" BU_SG_REL_ Frontsensorik SG_ 1124 PSD_Baum_Laenge_VZ 1500;
BA_REL_ "GenSigTimeoutTime" BU_SG_REL_ Frontradar SG_ 1124 PSD_Steigung_1_Segment_ID 1500;
BA_REL_ "GenSigTimeoutTime" BU_SG_REL_ Frontsensorik SG_ 1124 PSD_Steigung_1_Segment_ID 1500;
BA_REL_ "GenSigTimeoutTime" BU_SG_REL_ Frontradar SG_ 1124 PSD_Baum_Laenge 1500;
BA_REL_ "GenSigTimeoutTime" BU_SG_REL_ Frontsensorik SG_ 1124 PSD_Baum_Laenge 1500;
BA_REL_ "GenSigTimeoutTime" BU_SG_REL_ Frontradar SG_ 1124 PSD_Sys_Laendercode 1500;
BA_REL_ "GenSigTimeoutTime" BU_SG_REL_ Frontsensorik SG_ 1124 PSD_Sys_Laendercode 1500;
BA_REL_ "GenSigTimeoutTime" BU_SG_REL_ Frontradar SG_ 1124 PSD_Attribut_3_ID 1500;
BA_REL_ "GenSigTimeoutTime" BU_SG_REL_ Frontsensorik SG_ 1124 PSD_Attribut_3_ID 1500;
BA_REL_ "GenSigTimeoutTime" BU_SG_REL_ Frontradar SG_ 1124 PSD_Ges_Offset 1500;
BA_REL_ "GenSigTimeoutTime" BU_SG_REL_ Frontsensorik SG_ 1124 PSD_Ges_Offset 1500;
BA_REL_ "GenSigTimeoutTime" BU_SG_REL_ Frontradar SG_ 1124 PSD_Steigung_1_A_Steigung 1500;
BA_REL_ "GenSigTimeoutTime" BU_SG_REL_ Frontsensorik SG_ 1124 PSD_Steigung_1_A_Steigung 1500;
BA_REL_ "GenSigTimeoutTime" BU_SG_REL_ Frontradar SG_ 1124 PSD_Attribut_3_Offset 1500;
BA_REL_ "GenSigTimeoutTime" BU_SG_REL_ Frontsensorik SG_ 1124 PSD_Attribut_3_Offset 1500;
BA_REL_ "GenSigTimeoutTime" BU_SG_REL_ Frontradar SG_ 1124 PSD_Ges_Geschwindigkeit 1500;
BA_REL_ "GenSigTimeoutTime" BU_SG_REL_ Frontsensorik SG_ 1124 PSD_Ges_Geschwindigkeit 1500;
BA_REL_ "GenSigTimeoutTime" BU_SG_REL_ Frontradar SG_ 1124 PSD_Steigung_1_A_Vorz 1500;
BA_REL_ "GenSigTimeoutTime" BU_SG_REL_ Frontsensorik SG_ 1124 PSD_Steigung_1_A_Vorz 1500;
BA_REL_ "GenSigTimeoutTime" BU_SG_REL_ Frontradar SG_ 1124 PSD_Sys_Geschwindigkeit_Einheit 1500;
BA_REL_ "GenSigTimeoutTime" BU_SG_REL_ Frontsensorik SG_ 1124 PSD_Sys_Geschwindigkeit_Einheit 1500;
BA_REL_ "GenSigTimeoutTime" BU_SG_REL_ Frontradar SG_ 1124 PSD_Steigung_1_A_Offset 1500;
BA_REL_ "GenSigTimeoutTime" BU_SG_REL_ Frontsensorik SG_ 1124 PSD_Steigung_1_A_Offset 1500;
BA_REL_ "GenSigTimeoutTime" BU_SG_REL_ Frontradar SG_ 1124 PSD_Sys_Verkehrsrichtung 1500;
BA_REL_ "GenSigTimeoutTime" BU_SG_REL_ Frontsensorik SG_ 1124 PSD_Sys_Verkehrsrichtung 1500;
BA_REL_ "GenSigTimeoutTime" BU_SG_REL_ Frontradar SG_ 1124 PSD_Sys_Geometrieguete 1500;
BA_REL_ "GenSigTimeoutTime" BU_SG_REL_ Frontsensorik SG_ 1124 PSD_Sys_Geometrieguete 1500;
BA_REL_ "GenSigTimeoutTime" BU_SG_REL_ Frontradar SG_ 1124 PSD_Sys_Mapmatchingguete 1500;
BA_REL_ "GenSigTimeoutTime" BU_SG_REL_ Frontsensorik SG_ 1124 PSD_Sys_Mapmatchingguete 1500;
BA_REL_ "GenSigTimeoutTime" BU_SG_REL_ Frontradar SG_ 1124 PSD_Attribut_3_Wert 1500;
BA_REL_ "GenSigTimeoutTime" BU_SG_REL_ Frontsensorik SG_ 1124 PSD_Attribut_3_Wert 1500;
BA_REL_ "GenSigTimeoutTime" BU_SG_REL_ Frontradar SG_ 1124 PSD_Ges_Typ 1500;
BA_REL_ "GenSigTimeoutTime" BU_SG_REL_ Frontsensorik SG_ 1124 PSD_Ges_Typ 1500;
BA_REL_ "GenSigTimeoutTime" BU_SG_REL_ Frontradar SG_ 1124 PSD_Sys_Alter_Karte 1500;
BA_REL_ "GenSigTimeoutTime" BU_SG_REL_ Frontsensorik SG_ 1124 PSD_Sys_Alter_Karte 1500;
BA_REL_ "GenSigTimeoutTime" BU_SG_REL_ Frontradar SG_ 1124 PSD_Ges_Spur_Geschw_Begrenzung 1500;
BA_REL_ "GenSigTimeoutTime" BU_SG_REL_ Frontsensorik SG_ 1124 PSD_Ges_Spur_Geschw_Begrenzung 1500;
BA_REL_ "GenSigTimeoutTime" BU_SG_REL_ Frontradar SG_ 1124 PSD_Steigung_1_B_Steigung 1500;
BA_REL_ "GenSigTimeoutTime" BU_SG_REL_ Frontsensorik SG_ 1124 PSD_Steigung_1_B_Steigung 1500;
BA_REL_ "GenSigTimeoutTime" BU_SG_REL_ Frontradar SG_ 1124 PSD_Attribut_4_ID 1500;
BA_REL_ "GenSigTimeoutTime" BU_SG_REL_ Frontsensorik SG_ 1124 PSD_Attribut_4_ID 1500;
BA_REL_ "GenSigTimeoutTime" BU_SG_REL_ Frontradar SG_ 1124 PSD_Sys_Zielfuehrung 1500;
BA_REL_ "GenSigTimeoutTime" BU_SG_REL_ Frontsensorik SG_ 1124 PSD_Sys_Zielfuehrung 1500;
BA_REL_ "GenSigTimeoutTime" BU_SG_REL_ Frontradar SG_ 1124 PSD_Sys_US_State 1500;
BA_REL_ "GenSigTimeoutTime" BU_SG_REL_ Frontsensorik SG_ 1124 PSD_Sys_US_State 1500;
BA_REL_ "GenSigTimeoutTime" BU_SG_REL_ Frontradar SG_ 1124 PSD_Ges_Geschwindigkeit_Gespann 1500;
BA_REL_ "GenSigTimeoutTime" BU_SG_REL_ Frontsensorik SG_ 1124 PSD_Ges_Geschwindigkeit_Gespann 1500;
BA_REL_ "GenSigTimeoutTime" BU_SG_REL_ Frontradar SG_ 1124 PSD_Baum_Breite_VZ 1500;
BA_REL_ "GenSigTimeoutTime" BU_SG_REL_ Frontsensorik SG_ 1124 PSD_Baum_Breite_VZ 1500;
BA_REL_ "GenSigTimeoutTime" BU_SG_REL_ Frontradar SG_ 1124 PSD_Attribut_4_Wert 1500;
BA_REL_ "GenSigTimeoutTime" BU_SG_REL_ Frontsensorik SG_ 1124 PSD_Attribut_4_Wert 1500;
BA_REL_ "GenSigTimeoutTime" BU_SG_REL_ Frontradar SG_ 1124 PSD_Baum_Breite 1500;
BA_REL_ "GenSigTimeoutTime" BU_SG_REL_ Frontsensorik SG_ 1124 PSD_Baum_Breite 1500;
BA_REL_ "GenSigTimeoutTime" BU_SG_REL_ Frontradar SG_ 1124 PSD_Ges_Geschwindigkeit_Witter 1500;
BA_REL_ "GenSigTimeoutTime" BU_SG_REL_ Frontsensorik SG_ 1124 PSD_Ges_Geschwindigkeit_Witter 1500;
BA_REL_ "GenSigTimeoutTime" BU_SG_REL_ Frontradar SG_ 1124 PSD_Steigung_1_B_Vorz 1500;
BA_REL_ "GenSigTimeoutTime" BU_SG_REL_ Frontsensorik SG_ 1124 PSD_Steigung_1_B_Vorz 1500;
BA_REL_ "GenSigTimeoutTime" BU_SG_REL_ Frontradar SG_ 1124 PSD_Steigung_1_B_Offset 1500;
BA_REL_ "GenSigTimeoutTime" BU_SG_REL_ Frontsensorik SG_ 1124 PSD_Steigung_1_B_Offset 1500;
BA_REL_ "GenSigTimeoutTime" BU_SG_REL_ Frontradar SG_ 1124 PSD_Ges_Geschwindigkeit_Tag_Anf 1500;
BA_REL_ "GenSigTimeoutTime" BU_SG_REL_ Frontsensorik SG_ 1124 PSD_Ges_Geschwindigkeit_Tag_Anf 1500;
BA_REL_ "GenSigTimeoutTime" BU_SG_REL_ Frontradar SG_ 1124 PSD_Attribut_4_Offset 1500;
BA_REL_ "GenSigTimeoutTime" BU_SG_REL_ Frontsensorik SG_ 1124 PSD_Attribut_4_Offset 1500;
BA_REL_ "GenSigTimeoutTime" BU_SG_REL_ Frontradar SG_ 1124 PSD_Ges_Geschwindigkeit_Tag_Ende 1500;
BA_REL_ "GenSigTimeoutTime" BU_SG_REL_ Frontsensorik SG_ 1124 PSD_Ges_Geschwindigkeit_Tag_Ende 1500;
BA_REL_ "GenSigTimeoutTime" BU_SG_REL_ Frontradar SG_ 1124 PSD_Ges_Geschwindigkeit_Std_Anf 1500;
BA_REL_ "GenSigTimeoutTime" BU_SG_REL_ Frontsensorik SG_ 1124 PSD_Ges_Geschwindigkeit_Std_Anf 1500;
BA_REL_ "GenSigTimeoutTime" BU_SG_REL_ Frontradar SG_ 1124 PSD_Steigung_1_Attribute_kompl 1500;
BA_REL_ "GenSigTimeoutTime" BU_SG_REL_ Frontsensorik SG_ 1124 PSD_Steigung_1_Attribute_kompl 1500;
BA_REL_ "GenSigTimeoutTime" BU_SG_REL_ Frontradar SG_ 1124 PSD_Steigung_2_Segment_ID 1500;
BA_REL_ "GenSigTimeoutTime" BU_SG_REL_ Frontsensorik SG_ 1124 PSD_Steigung_2_Segment_ID 1500;
BA_REL_ "GenSigTimeoutTime" BU_SG_REL_ Frontradar SG_ 1124 PSD_Attribut_5_ID 1500;
BA_REL_ "GenSigTimeoutTime" BU_SG_REL_ Frontsensorik SG_ 1124 PSD_Attribut_5_ID 1500;
BA_REL_ "GenSigTimeoutTime" BU_SG_REL_ Frontradar SG_ 1124 PSD_Ges_Geschwindigkeit_Std_Ende 1500;
BA_REL_ "GenSigTimeoutTime" BU_SG_REL_ Frontsensorik SG_ 1124 PSD_Ges_Geschwindigkeit_Std_Ende 1500;
BA_REL_ "GenSigTimeoutTime" BU_SG_REL_ Frontradar SG_ 1124 PSD_Attribut_5_Offset 1500;
BA_REL_ "GenSigTimeoutTime" BU_SG_REL_ Frontsensorik SG_ 1124 PSD_Attribut_5_Offset 1500;
BA_REL_ "GenSigTimeoutTime" BU_SG_REL_ Frontradar SG_ 1124 PSD_Steigung_2_Steigung 1500;
BA_REL_ "GenSigTimeoutTime" BU_SG_REL_ Frontsensorik SG_ 1124 PSD_Steigung_2_Steigung 1500;
BA_REL_ "GenSigTimeoutTime" BU_SG_REL_ Frontradar SG_ 1124 PSD_Ges_Ueberholverbot 1500;
BA_REL_ "GenSigTimeoutTime" BU_SG_REL_ Frontsensorik SG_ 1124 PSD_Ges_Ueberholverbot 1500;
BA_REL_ "GenSigTimeoutTime" BU_SG_REL_ Frontradar SG_ 1124 PSD_Ges_Wechselverkehrszeichen 1500;
BA_REL_ "GenSigTimeoutTime" BU_SG_REL_ Frontsensorik SG_ 1124 PSD_Ges_Wechselverkehrszeichen 1500;
BA_REL_ "GenSigTimeoutTime" BU_SG_REL_ Frontradar SG_ 1124 PSD_Attribut_5_Wert 1500;
BA_REL_ "GenSigTimeoutTime" BU_SG_REL_ Frontsensorik SG_ 1124 PSD_Attribut_5_Wert 1500;
BA_REL_ "GenSigTimeoutTime" BU_SG_REL_ Frontradar SG_ 1124 PSD_Steigung_2_Vorz 1500;
BA_REL_ "GenSigTimeoutTime" BU_SG_REL_ Frontsensorik SG_ 1124 PSD_Steigung_2_Vorz 1500;
BA_REL_ "GenSigTimeoutTime" BU_SG_REL_ Frontradar SG_ 1124 PSD_Wechselverkehrszeichen_Typ 1500;
BA_REL_ "GenSigTimeoutTime" BU_SG_REL_ Frontsensorik SG_ 1124 PSD_Wechselverkehrszeichen_Typ 1500;
BA_REL_ "GenSigTimeoutTime" BU_SG_REL_ Frontradar SG_ 1124 PSD_Baum_Ausrichtung 1500;
BA_REL_ "GenSigTimeoutTime" BU_SG_REL_ Frontsensorik SG_ 1124 PSD_Baum_Ausrichtung 1500;
BA_REL_ "GenSigTimeoutTime" BU_SG_REL_ Frontradar SG_ 1124 PSD_Steigung_2_Offset 1500;
BA_REL_ "GenSigTimeoutTime" BU_SG_REL_ Frontsensorik SG_ 1124 PSD_Steigung_2_Offset 1500;
BA_REL_ "GenSigTimeoutTime" BU_SG_REL_ Frontradar SG_ 1124 PSD_Ges_Gesetzlich_Kategorie 1500;
BA_REL_ "GenSigTimeoutTime" BU_SG_REL_ Frontsensorik SG_ 1124 PSD_Ges_Gesetzlich_Kategorie 1500;
BA_REL_ "GenSigTimeoutTime" BU_SG_REL_ Frontradar SG_ 1124 PSD_Attribute_Komplett_06 1500;
BA_REL_ "GenSigTimeoutTime" BU_SG_REL_ Frontsensorik SG_ 1124 PSD_Attribute_Komplett_06 1500;
BA_REL_ "GenSigTimeoutTime" BU_SG_REL_ Frontradar SG_ 1124 PSD_Ges_Gesetzlich_Zusatz 1500;
BA_REL_ "GenSigTimeoutTime" BU_SG_REL_ Frontsensorik SG_ 1124 PSD_Ges_Gesetzlich_Zusatz 1500;
BA_REL_ "GenSigTimeoutTime" BU_SG_REL_ Frontradar SG_ 1124 PSD_Ges_Verkehrszeichen_Quelle 1500;
BA_REL_ "GenSigTimeoutTime" BU_SG_REL_ Frontsensorik SG_ 1124 PSD_Ges_Verkehrszeichen_Quelle 1500;
BA_REL_ "GenSigTimeoutTime" BU_SG_REL_ Frontradar SG_ 1124 PSD_Steigung_2_Attribute_kompl 1500;
BA_REL_ "GenSigTimeoutTime" BU_SG_REL_ Frontsensorik SG_ 1124 PSD_Steigung_2_Attribute_kompl 1500;
BA_REL_ "GenSigTimeoutTime" BU_SG_REL_ Frontradar SG_ 1124 PSD_Ges_Attribute_Komplett 1500;
BA_REL_ "GenSigTimeoutTime" BU_SG_REL_ Frontsensorik SG_ 1124 PSD_Ges_Attribute_Komplett 1500;
BA_REL_ "GenSigTimeoutTime" BU_SG_REL_ Frontsensorik SG_ 1440 RS_Regenmenge 2000;
BA_REL_ "GenSigTimeoutTime" BU_SG_REL_ Frontsensorik SG_ 1440 RS_Wischergeschwindigkeit 2000;
BA_REL_ "GenSigTimeoutTime" BU_SG_REL_ Frontradar SG_ 783 SWA_01_CRC 500;
BA_REL_ "GenSigTimeoutTime" BU_SG_REL_ Frontradar SG_ 783 SWA_01_BZ 500;
BA_REL_ "GenSigTimeoutTime" BU_SG_REL_ Frontradar SG_ 783 SWA_Blindheit_erkannt 500;
BA_REL_ "GenSigTimeoutTime" BU_SG_REL_ Frontradar SG_ 783 SWA_rel_Nichtverf 500;
BA_REL_ "GenSigTimeoutTime" BU_SG_REL_ Frontradar SG_ 783 SWA_rel_Fehler 500;
BA_REL_ "GenSigTimeoutTime" BU_SG_REL_ Frontradar SG_ 783 SWA_Standziele_li 500;
BA_REL_ "GenSigTimeoutTime" BU_SG_REL_ Frontradar SG_ 783 SWA_Kolonne_li 500;
BA_REL_ "GenSigTimeoutTime" BU_SG_REL_ Frontradar SG_ 783 SWA_Infostufe_SWA_li 500;
BA_REL_ "GenSigTimeoutTime" BU_SG_REL_ Frontsensorik SG_ 783 SWA_Infostufe_SWA_li 500;
BA_REL_ "GenSigTimeoutTime" BU_SG_REL_ Frontradar SG_ 783 SWA_Warnung_SWA_li 500;
BA_REL_ "GenSigTimeoutTime" BU_SG_REL_ Frontsensorik SG_ 783 SWA_Warnung_SWA_li 500;
BA_REL_ "GenSigTimeoutTime" BU_SG_REL_ Frontradar SG_ 783 SWA_Kolonne_mi 500;
BA_REL_ "GenSigTimeoutTime" BU_SG_REL_ Frontradar SG_ 783 SWA_Standziele_re 500;
BA_REL_ "GenSigTimeoutTime" BU_SG_REL_ Frontradar SG_ 783 SWA_Kolonne_re 500;
BA_REL_ "GenSigTimeoutTime" BU_SG_REL_ Frontradar SG_ 783 SWA_Infostufe_SWA_re 500;
BA_REL_ "GenSigTimeoutTime" BU_SG_REL_ Frontsensorik SG_ 783 SWA_Infostufe_SWA_re 500;
BA_REL_ "GenSigTimeoutTime" BU_SG_REL_ Frontradar SG_ 783 SWA_Warnung_SWA_re 500;
BA_REL_ "GenSigTimeoutTime" BU_SG_REL_ Frontsensorik SG_ 783 SWA_Warnung_SWA_re 500;
BA_REL_ "GenSigTimeoutTime" BU_SG_REL_ Frontsensorik SG_ 783 SWA_Gischtzaehler 500;
BA_REL_ "GenSigTimeoutTime" BU_SG_REL_ Frontradar SG_ 1413 SI_NWDF 5000;
BA_REL_ "GenSigTimeoutTime" BU_SG_REL_ Frontsensorik SG_ 1413 SI_NWDF 5000;
BA_REL_ "GenSigTimeoutTime" BU_SG_REL_ Frontradar SG_ 1413 SI_NWDF_gueltig 5000;
BA_REL_ "GenSigTimeoutTime" BU_SG_REL_ Frontsensorik SG_ 1413 SI_NWDF_gueltig 5000;
BA_REL_ "GenSigTimeoutTime" BU_SG_REL_ Frontradar SG_ 1413 SI_T_Schutz 5000;
BA_REL_ "GenSigTimeoutTime" BU_SG_REL_ Frontradar SG_ 997 TSG_FT_02_CRC 1000;
BA_REL_ "GenSigTimeoutTime" BU_SG_REL_ Frontradar SG_ 997 TSG_FT_02_BZ 1000;
BA_REL_ "GenSigTimeoutTime" BU_SG_REL_ Frontradar SG_ 997 FT_Tuer_Status 1000;
BA_REL_ "GenSigTimeoutTime" BU_SG_REL_ Frontradar SG_ 997 FT_Tuer_Status_QBit 1000;
BA_REL_ "GenSigTimeoutTime" BU_SG_REL_ Frontradar SG_ 288 TSK_06_CRC 500;
BA_REL_ "GenSigTimeoutTime" BU_SG_REL_ Frontsensorik SG_ 288 TSK_06_CRC 500;
BA_REL_ "GenSigTimeoutTime" BU_SG_REL_ Frontradar SG_ 288 TSK_06_BZ 500;
BA_REL_ "GenSigTimeoutTime" BU_SG_REL_ Frontsensorik SG_ 288 TSK_06_BZ 500;
BA_REL_ "GenSigTimeoutTime" BU_SG_REL_ Frontradar SG_ 288 TSK_Status 500;
BA_REL_ "GenSigTimeoutTime" BU_SG_REL_ Frontsensorik SG_ 288 TSK_Status 500;
BA_REL_ "GenSigTimeoutTime" BU_SG_REL_ Frontradar SG_ 288 TSK_Limiter_ausgewaehlt 500;
BA_REL_ "GenSigTimeoutTime" BU_SG_REL_ Frontradar SG_ 288 TSK_Hauptschalter_GRA_ACC 500;
BA_REL_ "GenSigTimeoutTime" BU_SG_REL_ Frontradar SG_ 346 TSK_08_CRC 1000;
BA_REL_ "GenSigTimeoutTime" BU_SG_REL_ Frontradar SG_ 346 TSK_08_BZ 1000;
BA_REL_ "GenSigTimeoutTime" BU_SG_REL_ Frontradar SG_ 346 TSK_vMax_Fahrerassistenz 1000;
BA_REL_ "GenSigTimeoutTime" BU_SG_REL_ Frontradar SG_ 346 TSK_Einheit_vMax_Fahrerassistenz 1000;
BA_REL_ "GenSigTimeoutTime" BU_SG_REL_ Frontradar SG_ 1019 TSK_Ausrollkurve_Schub_Reku_01 800;
BA_REL_ "GenSigTimeoutTime" BU_SG_REL_ Frontradar SG_ 1019 TSK_Ausrollkurve_Schub_Reku_05 800;
BA_REL_ "GenSigTimeoutTime" BU_SG_REL_ Frontradar SG_ 1019 TSK_Ausrollkurve_Schub_Reku_09 800;
BA_REL_ "GenSigTimeoutTime" BU_SG_REL_ Frontradar SG_ 1019 TSK_Ausrollkurve_Schub_Reku_13 800;
BA_REL_ "GenSigTimeoutTime" BU_SG_REL_ Frontradar SG_ 1019 TSK_Ausrollkurve_Schub_Reku_17 800;
BA_REL_ "GenSigTimeoutTime" BU_SG_REL_ Frontradar SG_ 1019 TSK_Ausrollkurve_Schub_Reku_02 800;
BA_REL_ "GenSigTimeoutTime" BU_SG_REL_ Frontradar SG_ 1019 TSK_Ausrollkurve_Schub_Reku_06 800;
BA_REL_ "GenSigTimeoutTime" BU_SG_REL_ Frontradar SG_ 1019 TSK_Ausrollkurve_Schub_Reku_10 800;
BA_REL_ "GenSigTimeoutTime" BU_SG_REL_ Frontradar SG_ 1019 TSK_Ausrollkurve_Schub_Reku_14 800;
BA_REL_ "GenSigTimeoutTime" BU_SG_REL_ Frontradar SG_ 1019 TSK_Ausrollkurve_Schub_Reku_18 800;
BA_REL_ "GenSigTimeoutTime" BU_SG_REL_ Frontradar SG_ 1019 TSK_Ausrollkurve_Schub_Reku_03 800;
BA_REL_ "GenSigTimeoutTime" BU_SG_REL_ Frontradar SG_ 1019 TSK_Ausrollkurve_Schub_Reku_07 800;
BA_REL_ "GenSigTimeoutTime" BU_SG_REL_ Frontradar SG_ 1019 TSK_Ausrollkurve_Schub_Reku_11 800;
BA_REL_ "GenSigTimeoutTime" BU_SG_REL_ Frontradar SG_ 1019 TSK_Ausrollkurve_Schub_Reku_15 800;
BA_REL_ "GenSigTimeoutTime" BU_SG_REL_ Frontradar SG_ 1019 TSK_Ausrollkurve_Schub_Reku_19 800;
BA_REL_ "GenSigTimeoutTime" BU_SG_REL_ Frontradar SG_ 1019 TSK_Ausrollkurve_Schub_Reku_04 800;
BA_REL_ "GenSigTimeoutTime" BU_SG_REL_ Frontradar SG_ 1019 TSK_Ausrollkurve_Schub_Reku_08 800;
BA_REL_ "GenSigTimeoutTime" BU_SG_REL_ Frontradar SG_ 1019 TSK_Ausrollkurve_Schub_Reku_12 800;
BA_REL_ "GenSigTimeoutTime" BU_SG_REL_ Frontradar SG_ 1019 TSK_Ausrollkurve_Schub_Reku_16 800;
BA_REL_ "GenSigTimeoutTime" BU_SG_REL_ Frontradar SG_ 1019 TSK_Ausrollkurve_Schub_Reku_20 800;
BA_REL_ "GenSigTimeoutTime" BU_SG_REL_ Frontradar SG_ 1019 TSK_Ausrollkurve_Segeln_01 800;
BA_REL_ "GenSigTimeoutTime" BU_SG_REL_ Frontradar SG_ 1019 TSK_Ausrollkurve_Segeln_05 800;
BA_REL_ "GenSigTimeoutTime" BU_SG_REL_ Frontradar SG_ 1019 TSK_Ausrollkurve_Segeln_09 800;
BA_REL_ "GenSigTimeoutTime" BU_SG_REL_ Frontradar SG_ 1019 TSK_Ausrollkurve_Segeln_13 800;
BA_REL_ "GenSigTimeoutTime" BU_SG_REL_ Frontradar SG_ 1019 TSK_Ausrollkurve_Segeln_17 800;
BA_REL_ "GenSigTimeoutTime" BU_SG_REL_ Frontradar SG_ 1019 TSK_Ausrollkurve_Segeln_02 800;
BA_REL_ "GenSigTimeoutTime" BU_SG_REL_ Frontradar SG_ 1019 TSK_Ausrollkurve_Segeln_06 800;
BA_REL_ "GenSigTimeoutTime" BU_SG_REL_ Frontradar SG_ 1019 TSK_Ausrollkurve_Segeln_10 800;
BA_REL_ "GenSigTimeoutTime" BU_SG_REL_ Frontradar SG_ 1019 TSK_Ausrollkurve_Segeln_14 800;
BA_REL_ "GenSigTimeoutTime" BU_SG_REL_ Frontradar SG_ 1019 TSK_Ausrollkurve_Segeln_18 800;
BA_REL_ "GenSigTimeoutTime" BU_SG_REL_ Frontradar SG_ 1019 TSK_Ausrollkurve_Segeln_03 800;
BA_REL_ "GenSigTimeoutTime" BU_SG_REL_ Frontradar SG_ 1019 TSK_Ausrollkurve_Segeln_07 800;
BA_REL_ "GenSigTimeoutTime" BU_SG_REL_ Frontradar SG_ 1019 TSK_Ausrollkurve_Segeln_11 800;
BA_REL_ "GenSigTimeoutTime" BU_SG_REL_ Frontradar SG_ 1019 TSK_Ausrollkurve_Segeln_15 800;
BA_REL_ "GenSigTimeoutTime" BU_SG_REL_ Frontradar SG_ 1019 TSK_Ausrollkurve_Segeln_19 800;
BA_REL_ "GenSigTimeoutTime" BU_SG_REL_ Frontradar SG_ 1019 TSK_Ausrollkurve_Segeln_04 800;
BA_REL_ "GenSigTimeoutTime" BU_SG_REL_ Frontradar SG_ 1019 TSK_Ausrollkurve_Segeln_08 800;
BA_REL_ "GenSigTimeoutTime" BU_SG_REL_ Frontradar SG_ 1019 TSK_Ausrollkurve_Segeln_12 800;
BA_REL_ "GenSigTimeoutTime" BU_SG_REL_ Frontradar SG_ 1019 TSK_Ausrollkurve_Segeln_16 800;
BA_REL_ "GenSigTimeoutTime" BU_SG_REL_ Frontradar SG_ 1019 TSK_Ausrollkurve_Segeln_20 800;
BA_REL_ "GenSigTimeoutTime" BU_SG_REL_ Frontradar SG_ 1019 TSK_Ausrollkurve_Mux 800;
BA_REL_ "GenSigTimeoutTime" BU_SG_REL_ Frontradar SG_ 1019 TSK_Ausrollkurve_Reku 800;
BA_REL_ "GenSigTimeoutTime" BU_SG_REL_ Frontradar SG_ 1019 TSK_Ausrollkurve_Schrittweite 800;
BA_REL_ "GenSigTimeoutTime" BU_SG_REL_ Frontradar SG_ 1019 TSK_Ausrollkurve_Zaehler 800;
BA_REL_ "GenSigTimeoutTime" BU_SG_REL_ Frontradar SG_ 1716 VIN_01_MUX 2000;
BA_REL_ "GenSigTimeoutTime" BU_SG_REL_ Frontsensorik SG_ 1716 VIN_01_MUX 2000;
BA_REL_ "GenSigTimeoutTime" BU_SG_REL_ Frontradar SG_ 1716 KS_Geheimnis_1 2000;
BA_REL_ "GenSigTimeoutTime" BU_SG_REL_ Frontradar SG_ 1716 VIN_4 2000;
BA_REL_ "GenSigTimeoutTime" BU_SG_REL_ Frontsensorik SG_ 1716 VIN_4 2000;
BA_REL_ "GenSigTimeoutTime" BU_SG_REL_ Frontradar SG_ 1716 VIN_11 2000;
BA_REL_ "GenSigTimeoutTime" BU_SG_REL_ Frontsensorik SG_ 1716 VIN_11 2000;
BA_REL_ "GenSigTimeoutTime" BU_SG_REL_ Frontradar SG_ 1716 KS_Geheimnis_2 2000;
BA_REL_ "GenSigTimeoutTime" BU_SG_REL_ Frontradar SG_ 1716 VIN_5 2000;
BA_REL_ "GenSigTimeoutTime" BU_SG_REL_ Frontsensorik SG_ 1716 VIN_5 2000;
BA_REL_ "GenSigTimeoutTime" BU_SG_REL_ Frontradar SG_ 1716 VIN_12 2000;
BA_REL_ "GenSigTimeoutTime" BU_SG_REL_ Frontsensorik SG_ 1716 VIN_12 2000;
BA_REL_ "GenSigTimeoutTime" BU_SG_REL_ Frontradar SG_ 1716 KS_Geheimnis_3 2000;
BA_REL_ "GenSigTimeoutTime" BU_SG_REL_ Frontradar SG_ 1716 VIN_6 2000;
BA_REL_ "GenSigTimeoutTime" BU_SG_REL_ Frontsensorik SG_ 1716 VIN_6 2000;
BA_REL_ "GenSigTimeoutTime" BU_SG_REL_ Frontradar SG_ 1716 VIN_13 2000;
BA_REL_ "GenSigTimeoutTime" BU_SG_REL_ Frontsensorik SG_ 1716 VIN_13 2000;
BA_REL_ "GenSigTimeoutTime" BU_SG_REL_ Frontradar SG_ 1716 KS_Geheimnis_4 2000;
BA_REL_ "GenSigTimeoutTime" BU_SG_REL_ Frontradar SG_ 1716 VIN_7 2000;
BA_REL_ "GenSigTimeoutTime" BU_SG_REL_ Frontsensorik SG_ 1716 VIN_7 2000;
BA_REL_ "GenSigTimeoutTime" BU_SG_REL_ Frontradar SG_ 1716 VIN_14 2000;
BA_REL_ "GenSigTimeoutTime" BU_SG_REL_ Frontsensorik SG_ 1716 VIN_14 2000;
BA_REL_ "GenSigTimeoutTime" BU_SG_REL_ Frontradar SG_ 1716 VIN_1 2000;
BA_REL_ "GenSigTimeoutTime" BU_SG_REL_ Frontsensorik SG_ 1716 VIN_1 2000;
BA_REL_ "GenSigTimeoutTime" BU_SG_REL_ Frontradar SG_ 1716 VIN_8 2000;
BA_REL_ "GenSigTimeoutTime" BU_SG_REL_ Frontsensorik SG_ 1716 VIN_8 2000;
BA_REL_ "GenSigTimeoutTime" BU_SG_REL_ Frontradar SG_ 1716 VIN_15 2000;
BA_REL_ "GenSigTimeoutTime" BU_SG_REL_ Frontsensorik SG_ 1716 VIN_15 2000;
BA_REL_ "GenSigTimeoutTime" BU_SG_REL_ Frontradar SG_ 1716 VIN_2 2000;
BA_REL_ "GenSigTimeoutTime" BU_SG_REL_ Frontsensorik SG_ 1716 VIN_2 2000;
BA_REL_ "GenSigTimeoutTime" BU_SG_REL_ Frontradar SG_ 1716 VIN_9 2000;
BA_REL_ "GenSigTimeoutTime" BU_SG_REL_ Frontsensorik SG_ 1716 VIN_9 2000;
BA_REL_ "GenSigTimeoutTime" BU_SG_REL_ Frontradar SG_ 1716 VIN_16 2000;
BA_REL_ "GenSigTimeoutTime" BU_SG_REL_ Frontsensorik SG_ 1716 VIN_16 2000;
BA_REL_ "GenSigTimeoutTime" BU_SG_REL_ Frontradar SG_ 1716 VIN_3 2000;
BA_REL_ "GenSigTimeoutTime" BU_SG_REL_ Frontsensorik SG_ 1716 VIN_3 2000;
BA_REL_ "GenSigTimeoutTime" BU_SG_REL_ Frontradar SG_ 1716 VIN_10 2000;
BA_REL_ "GenSigTimeoutTime" BU_SG_REL_ Frontsensorik SG_ 1716 VIN_10 2000;
BA_REL_ "GenSigTimeoutTime" BU_SG_REL_ Frontradar SG_ 1716 VIN_17 2000;
BA_REL_ "GenSigTimeoutTime" BU_SG_REL_ Frontsensorik SG_ 1716 VIN_17 2000;
BA_REL_ "GenSigTimeoutTime" BU_SG_REL_ Frontradar SG_ 385 VZE_Anzeigemodus 2000;
BA_REL_ "GenSigTimeoutTime" BU_SG_REL_ Frontradar SG_ 385 VZE_Hinweistext 2000;
BA_REL_ "GenSigTimeoutTime" BU_SG_REL_ Frontradar SG_ 385 VZE_Statuszaehler_1 2000;
BA_REL_ "GenSigTimeoutTime" BU_SG_REL_ Frontradar SG_ 385 VZE_Statuszaehler_2 2000;
BA_REL_ "GenSigTimeoutTime" BU_SG_REL_ Frontradar SG_ 385 VZE_Statuszaehler_3 2000;
BA_REL_ "GenSigTimeoutTime" BU_SG_REL_ Frontradar SG_ 385 VZE_Verkehrszeichen_1 2000;
BA_REL_ "GenSigTimeoutTime" BU_SG_REL_ Frontradar SG_ 385 VZE_Verkehrszeichen_2 2000;
BA_REL_ "GenSigTimeoutTime" BU_SG_REL_ Frontradar SG_ 385 VZE_Verkehrszeichen_3 2000;
BA_REL_ "GenSigTimeoutTime" BU_SG_REL_ Frontradar SG_ 385 VZE_Warnung_Verkehrszeichen_1 2000;
BA_REL_ "GenSigTimeoutTime" BU_SG_REL_ Frontradar SG_ 385 VZE_Warnung_Verkehrszeichen_2 2000;
BA_REL_ "GenSigTimeoutTime" BU_SG_REL_ Frontradar SG_ 385 VZE_Warnung_Verkehrszeichen_3 2000;
BA_REL_ "GenSigTimeoutTime" BU_SG_REL_ Frontradar SG_ 385 VZE_Zusatzschild_1 2000;
BA_REL_ "GenSigTimeoutTime" BU_SG_REL_ Frontradar SG_ 385 VZE_Zusatzschild_2 2000;
BA_REL_ "GenSigTimeoutTime" BU_SG_REL_ Frontradar SG_ 385 VZE_Zusatzschild_3 2000;
BA_REL_ "GenSigTimeoutTime" BU_SG_REL_ Frontradar SG_ 385 VZE_Hinweistext_02 2000;
BA_REL_ "GenSigTimeoutTime" BU_SG_REL_ Frontradar SG_ 668 VZE_Statuszaehler_4 2000;
BA_REL_ "GenSigTimeoutTime" BU_SG_REL_ Frontradar SG_ 668 VZE_Statuszaehler_5 2000;
BA_REL_ "GenSigTimeoutTime" BU_SG_REL_ Frontradar SG_ 668 VZE_Verkehrszeichen_4 2000;
BA_REL_ "GenSigTimeoutTime" BU_SG_REL_ Frontradar SG_ 668 VZE_Verkehrszeichen_5 2000;
BA_REL_ "GenSigTimeoutTime" BU_SG_REL_ Frontradar SG_ 668 VZE_Warnung_Verkehrszeichen_4 2000;
BA_REL_ "GenSigTimeoutTime" BU_SG_REL_ Frontradar SG_ 668 VZE_Warnung_Verkehrszeichen_5 2000;
BA_REL_ "GenSigTimeoutTime" BU_SG_REL_ Frontradar SG_ 668 VZE_Zusatzschild_4 2000;
BA_REL_ "GenSigTimeoutTime" BU_SG_REL_ Frontradar SG_ 668 VZE_Zusatzschild_5 2000;
VAL_ 930 PSD_Multiplex 0 "für System Informationen, die sich nur langsam ändern" 1 "Informationen über ein Streckensegment" 2 "für Informationen über Geschwindigkeitsbegrenzungen und mögliche Einschränkungen der Geschwindigkeitsbegrenzungen" 3 "Fahrzeugposition aus der Koppelortung" ;
VAL_ 930 PSD_Sys_Segment_ID 0 "keine Segmentinformationen vorhanden" 1 "nicht zulaessig" ;
VAL_ 930 PSD_Abz_Segment_ID 0 "keine Segmentinformationen vorhanden" 1 "nicht zulaessig" ;
VAL_ 930 PSD_Ges_Segment_ID 0 "keine Segmentinformationen vorhanden" 1 "nicht zulaessig" ;
VAL_ 930 PSD_Ort_Laenge_VZ 0 "Ost" 1 "West" ;
VAL_ 930 PSD_Ort_Laenge 33554431 "Keine GPS Position verfuegbar" ;
VAL_ 930 PSD_Ges_Geschwindigkeit 0 "Kein Geschwindigkeitsgebot" 1 "0 km/h < v_max <  5 km/h" 2 "5 km/h < v_max < 10km/h" 3 "10 km/h < v_max < 15 km/h" 4 "15 km/h < v_max < 20 km/h" 5 "20 km/h < v_max < 25 km/h" 6 "25 km/h < v_max < 30 km/h" 7 "30 km/h < v_max < 35 km/h" 8 "35 km/h < v_max < 40 km/h" 9 "40 km/h < v_max < 45 km/h" 10 "45 km/h < v_max < 50 km/h" 11 "50 km/h < v_max < 60 km/h" 12 "60 km/h < v_max < 70 km/h" 13 "70 km/h < v_max < 80 km/h" 14 "80 km/h < v_max < 90 km/h" 15 "90 km/h < v_max < 100 km/h" 16 "100 km/h < v_max < 110 km/h" 17 "110 km/h < v_max < 120 km/h" 18 " 120 km/h < v_max < 130 km/h" 19 "130 km/h < v_max < 140 km/h" 20 "140 km/h < v_max < 150 km/h" 21 "150 km/h < v_max < 160 km/h" 22 "160 km/h < v_max" 23 "Geschwindigkeitsgebot aufgehoben" 24 "..0x1F ungültig" ;
VAL_ 930 PSD_Ges_Geschwindigkeit_Typ 0 "Der Wert im Attribut Geschwindigkeitsbegrenzung entspricht der Geschwindigkeitsklasse von Navteq." 1 "Der Wert im Attribut Geschwindigkeitsbegrenzung entspricht einer explizit angegebenen Begrenzung der Geschwindigkeit." ;
VAL_ 930 PSD_Ges_Geschwindigkeit_Gespann 0 "alle Fahrzeuge" 1 "PKW mit Gespann" 2 "LKW, Busse, etc." ;
VAL_ 930 PSD_Abz_Vorgaenger_Segment_ID 0 "keine Segmentinformationen vorhanden" 1 "nicht zulaessig" ;
VAL_ 930 PSD_Sys_Geschwindigkeit_Einheit 0 "km/h" 1 "mph" ;
VAL_ 930 PSD_Ges_Geschwindigkeit_Witter 0 "Witterungsunabhängig" 1 "Nässe, Regen, Niederschlag" 2 "Glätte" 3 "Nebel" ;
VAL_ 930 PSD_Sys_Verkehrsrichtung 0 "Rechtsverkehr" 1 "Linksverkehr" ;
VAL_ 930 PSD_Ges_Geschwindigkeit_Tag_Anf 0 "kein Beginn definiert" 1 "Montag" 2 "Dienstag" 3 "Mittwoch" 4 "Donnerstag" 5 "Freitag" 6 "Samstag" 7 "Sonntag" ;
VAL_ 930 PSD_Abz_Geschwindigkeit 0 "kein Geschwindigkeitsgebot" 1 "0 km/h < v_max <  5 km/h" 2 "5 km/h ¿ v_max < 10km/h" 3 "10 km/h ¿ v_max < 15 km/h" 4 "15 km/h ¿ v_max < 20 km/h" 5 "20 km/h ¿ v_max < 25 km/h" 6 "25 km/h ¿ v_max < 30 km/h" 7 "30 km/h ¿ v_max < 35 km/h" 8 "35 km/h ¿ v_max < 40 km/h" 9 "40 km/h ¿ v_max < 45 km/h" 10 "45 km/h ¿ v_max < 50 km/h" 11 "50 km/h ¿ v_max < 60 km/h" 12 "60 km/h ¿ v_max < 70 km/h" 13 "70 km/h ¿ v_max < 80 km/h" 14 "80 km/h ¿ v_max < 90 km/h" 15 "90 km/h ¿ v_max < 100 km/h" 16 "100 km/h ¿ v_max < 110 km/h" 17 "110 km/h ¿ v_max < 120 km/h" 18 "120 km/h ¿ v_max < 130 km/h" 19 "130 km/h ¿ v_max < 140 km/h" 20 "140 km/h ¿ v_max < 150 km/h" 21 "150 km/h ¿ v_max < 160 km/h" 22 "160 km/h ¿ v_max" 23 " Geschwindigkeitsgebot aufgehoben" 24 "..0x1F ungültig" ;
VAL_ 930 PSD_Ges_Geschwindigkeit_Tag_Ende 0 "kein Ende definiert" 1 "Montag" 2 "Dienstag" 3 "Mittwoch" 4 "Donnerstag" 5 "Freitag" 6 "Samstag" 7 "Sonntag" ;
VAL_ 930 PSD_Ges_Geschwindigkeit_Std_Anf 25 "kein Beginn für stundenweise Einschränkungen" ;
VAL_ 930 PSD_Abz_Geschwindigkeit_Typ 0 "Der Wert im Attribut Geschwindigkeitsbegrenzung entspricht der Geschwindigkeitsklasse von Navteq." 1 "Der Wert im Attribut Geschwindigkeitsbegrenzung entspricht einer explizit angegebenen Begrenzung der Geschwindigkeit" ;
VAL_ 930 PSD_Sys_Tunnel 0 "kein Tunnel oder keine Information verfuegbar" 1 "Tunnel" ;
VAL_ 930 PSD_Abz_Strassenklasse 0 " Rest (Feldweg, Schotter, Privatweg)" 1 "Ortsstraße" 2 "Bundes-,Landstrasse" 3 "Autobahn" ;
VAL_ 930 PSD_Sys_Bruecke 0 "keine Bruecke oder keine Information verfuegbar" 1 "Bruecke" ;
VAL_ 930 PSD_Ort_Breite_VZ 0 "Nord" 1 "Sued" ;
VAL_ 930 PSD_Sys_Fahrsp_Gegenr 0 "keine Fahrspur" 1 "eine Fahrspur" 2 "mehr als eine Fahrspur" 3 "keine Information verfuegbar" ;
VAL_ 930 PSD_Abz_ADAS_Qualitaet 0 "keine ADAS Qualität" 1 "ADAS Qualität" ;
VAL_ 930 PSD_Ges_Geschwindigkeit_Std_Ende 25 "kein Ende für stundenweise Einschränkungen" ;
VAL_ 930 PSD_Abz_Abzweigerichtung 0 "rechts abzweigende Straße" 1 "links abzweigende Straße" ;
VAL_ 930 PSD_Sys_TMC_Baustelle 0 "keine Baustelle oder keine Information verfuegbar" 1 "Baustelle" ;
VAL_ 930 PSD_Abz_Abzweigewinkel 0 "0¿: Straße verläuft gerade aus" 1 "0¿ < Winkel ¿ 12¿" 2 "12¿ < Winkel ¿ 24¿" 3 "24¿ < Winkel ¿ 36¿" 4 "36¿ < Winkel ¿ 48¿" 5 "48¿ < Winkel ¿ 60¿" 6 "60¿ < Winkel ¿ 72¿" 7 "72¿ < Winkel ¿ 84¿" 8 "84¿ < Winkel ¿ 96¿" 9 "96¿ < Winkel ¿ 108¿" 10 "108¿ < Winkel ¿ 120¿" 11 "120¿ < Winkel ¿ 132¿" 12 "132¿ < Winkel ¿ 144¿" 13 "144¿ < Winkel ¿ 156¿" 14 "156¿ < Winkel ¿ 168¿" 15 "168¿ < Winkel ¿ 180¿" ;
VAL_ 930 PSD_Sys_TMC_Stau 0 "kein Stau oder keine Information verfuegbar" 1 "Stau" ;
VAL_ 930 PSD_Sys_Bauliche_Trennung 0 "Keine_Trennung" 1 "Bauliche_Trennung" 2 "Nicht_bauliche_Trennung" 3 "Unbekannt" ;
VAL_ 930 PSD_Ges_alter_Geschw 0 "Kein Geschwindigkeitsgebot" 1 "0 km/h < v_max <  5 km/h" 2 "5 km/h ¿ v_max < 10km/h" 3 "10 km/h ¿ v_max < 15 km/h" 4 "15 km/h ¿ v_max < 20 km/h" 5 "20 km/h ¿ v_max < 25 km/h" 6 "25 km/h ¿ v_max < 30 km/h" 7 "30 km/h ¿ v_max < 35 km/h" 8 "35 km/h ¿ v_max < 40 km/h" 9 "40 km/h ¿ v_max < 45 km/h" 10 "45 km/h ¿ v_max < 50 km/h" 11 "50 km/h ¿ v_max < 60 km/h" 12 "60 km/h ¿ v_max < 70 km/h" 13 "70 km/h ¿ v_max < 80 km/h" 14 "80 km/h ¿ v_max < 90 km/h" 15 "90 km/h ¿ v_max < 100 km/h" 16 "100 km/h ¿ v_max < 110 km/h" 17 "110 km/h ¿ v_max < 120 km/h" 18 "120 km/h ¿ v_max < 130 km/h" 19 "130 km/h ¿ v_max < 140 km/h" 20 "140 km/h ¿ v_max < 150 km/h" 21 "150 km/h ¿ v_max < 160 km/h" 22 "160 km/h ¿ v_max" 23 "Geschwindigkeitsgebot aufgehoben" 24 "..0x1F ungültig" ;
VAL_ 930 PSD_Sys_Geometrieguete 0 "Geringe_Guete" 1 "tbd" 2 "tbd" 3 "Hohe_Guete" ;
VAL_ 930 PSD_Abz_Rampe 0 "Straße mit Gegenverkehr" 1 "Auffahrt (Einbahnstr.) " 2 "Abfahrt (Einbahnstr.)" 3 "Einbahnstraße" ;
VAL_ 930 PSD_Sys_Maut 0 "Keine_Mautstelle" 1 "Mautstelle" ;
VAL_ 930 PSD_Abz_Anfangskruemmung 255 "Gerade" ;
VAL_ 930 PSD_Sys_Strassensituation 0 "Unbekannt" 1 "Kreisverkehr" 2 "Zufahrt_zu_Services" 3 "tbd" ;
VAL_ 930 PSD_Ges_alter_Geschw_Gespann 0 "alle Fahrzeuge" 1 "PKW mit Gespann" 2 "LKW, Busse, etc." ;
VAL_ 930 PSD_Sys_StrKlassen_erweitert 0 "Rest_Feldweg_Schotterweg_Privatweg" 1 "Ortsstrasse" 2 "Kreisstrasse" 3 "Landstrasse" 4 "Bundesstrasse" 5 "Autobahn" 6 "Unbekannt" 7 "tbd" ;
VAL_ 930 PSD_Ges_alter_Geschw_Witter 0 "Witterungsunabhängig" 1 "Nässe, Regen, Niederschlag" 2 "Glätte" 3 "Nebel" ;
VAL_ 930 PSD_Sys_Ortsschild 0 "Ortausgangsschild_außerorts" 1 "Ortseingangsschild_ innerorts" ;
VAL_ 930 PSD_Ges_alter_Geschw_Tag_Anf 0 "kein Beginn definiert" 1 "Montag" 2 "Dienstag" 3 "Mittwoch" 4 "Donnerstag" 5 "Freitag" 6 "Samstag" 7 "Sonntag" ;
VAL_ 930 PSD_Abz_Anfangskruemmung_Vorz 0 "Krümmung positiv" 1 "Krümmung negativ" ;
VAL_ 930 PSD_Sys_Anfangskruemmung 255 "Gerade" ;
VAL_ 930 PSD_Abz_Endkruemmung 255 "Gerade" ;
VAL_ 930 PSD_Ges_alter_Geschw_Tag_Ende 0 "kein Ende definiert" 1 "Montag" 2 "Dienstag" 3 "Mittwoch" 4 "Donnerstag" 5 "Freitag" 6 "Samstag" 7 "Sonntag" ;
VAL_ 930 PSD_Ges_alter_Geschw_Std_Anf 25 "kein Beginn für stundenweise Einschränkungen" ;
VAL_ 930 PSD_Sys_Anfangskruemmung_Vorz 0 "Krümmung positiv" 1 "Krümmung negativ" ;
VAL_ 930 PSD_Abz_Endkruemmung_Vorz 0 "Krümmung positiv" 1 "Krümmung negativ" ;
VAL_ 930 PSD_Ges_alter_Geschw_Std_Ende 25 "kein Ende für stundenweise Einschränkungen" ;
VAL_ 930 PSD_Sys_Anfangssteigung 30 "gleich oder mehr als 15 % Steigung" 31 "ungültig" ;
VAL_ 930 PSD_Abz_Endsteigung 30 "gleich oder mehr als 15 % Steigung" 31 "ungültig" ;
VAL_ 930 PSD_Ges_Ueberholverbot 0 "kein Überholverbot" 1 "alle Fahrzeuge" 2 "Überholverbot für PKW mit Gespann" 3 "Überholverbot für LKW, Busse, etc." ;
VAL_ 930 PSD_Sys_Anfangssteigung_Vorz 0 "Gefälle " 1 "Steigung" ;
VAL_ 930 PSD_Abz_Endsteigung_Vorz 0 "Gefälle" 1 "Steigung" ;
VAL_ 930 PSD_Sys_Ortschaft 0 "außerhalb der Ortschaft" 1 "innerhalb der Ortschaft" ;
VAL_ 930 PSD_Abz_Fahrspuren 0 "Einbahnstraße in falscher Richtung" 1 "eine Fahrspur" 2 "zwei Fahrspuren" 3 "mehr als 2 Fahrspuren" ;
VAL_ 930 PSD_Ges_Wechselverkehrszeichen 0 "Kein Wechselverkehrszeichen" 1 "Wechselverkehrszeichen links" 2 "Wechselverkehrszeichen rechts" 3 "Wechselverkehrszeichen links und rechts" 4 "Wechselverkerhszeichen über der Fahrbahn" ;
VAL_ 930 PSD_Sys_Digitalisierung 0 "teildigitalisiert" 1 "volldigitalisiert" ;
VAL_ 930 PSD_Sys_Zielfuehrung 0 "Zielfuehrung nicht aktiv" 1 "Zielfuehrung aktiv" ;
VAL_ 930 PSD_Abz_wahrscheinlichster_Pfad 0 "Pfad mit geringer Wahrscheinlichkeit" 1 "wahrscheinlichster Pfad" ;
VAL_ 1122 PSD_Segment_ID 0 "keine Segmentinformationen vorhanden" 1 "Fehlerwert" ;
VAL_ 1122 PSD_Vorgaenger_Segment_ID 0 "keine Segmentinformation vorhanden" 1 "Fehlerwert" ;
VAL_ 1122 PSD_Strassenkategorie 0 "Rest_Feldweg_Schotterweg_Privatweg" 1 "Ortsstraße" 2 "Kreisstraße" 3 "Landstraße" 4 "Bundesstraße" 5 "Autobahn" 7 "Init" ;
VAL_ 1122 PSD_Endkruemmung 255 "Gerade" ;
VAL_ 1122 PSD_Endkruemmung_Vorz 0 "Kruemmung_positiv" 1 "Kruemmung_negativ" ;
VAL_ 1122 PSD_Idenditaets_ID 0 "keine_Segment_Informationen_vorhanden" 1 "Fehler" ;
VAL_ 1122 PSD_ADAS_Qualitaet 0 "keine_ADAS_Qualitaet" 1 "ADAS_Qualitaet" ;
VAL_ 1122 PSD_wahrscheinlichster_Pfad 0 "Pfad_mit_geringer_Wahrscheinlichkeit" 1 "wahrscheinlichster_Pfad" ;
VAL_ 1122 PSD_Geradester_Pfad 0 "nicht_geradester_PFad" 1 "geradester_Pfad" ;
VAL_ 1122 PSD_Fahrspuren_Anzahl 0 "Einbahnstrasse_in_falsche_Richtung" 1 "eine_Fahrspur" 2 "zwei_Fahrspuren" 3 "drei_Fahrspuren" 4 "vier_Fahrspuren" 5 "fuenf_Fahrspuren" 6 "sechs_Fahrspuren" 7 "mehr_als_sechs_Fahrspuren" ;
VAL_ 1122 PSD_Bebauung 0 "ausserhalb_bebauten_Gebietes" 1 "innerhalb_bebauten_Gebietes" ;
VAL_ 1122 PSD_Segment_Komplett 0 "Segment_Attribute_nicht_komplett" 1 "Segment_Attribute_komplett" ;
VAL_ 1122 PSD_Rampe 0 "Strasse_mit_Gegenverkehr" 1 "Auffahrt_Einbahnstr" 2 "Abfahrt_Einbahnstr" 3 "Einbahnstrasse" ;
VAL_ 1122 PSD_Anfangskruemmung 255 "Gerade" ;
VAL_ 1122 PSD_Anfangskruemmung_Vorz 0 "positiv" 1 "negativ" ;
VAL_ 1122 PSD_Abzweigerichtung 0 "rects_abzweigende_Strasse" 1 "links_abzweigende_Strasse" ;
VAL_ 1123 PSD_Pos_Segment_ID 0 "keine Position gegeben" 1 "Fehlerwert" ;
VAL_ 1123 PSD_Pos_Standort_Eindeutig 0 "mehrdeutiger_Standort" 1 "eindeutiger_Standort" ;
VAL_ 1123 PSD_Pos_Fehler_Laengsrichtung 0 "Init" 1 "< 2m" 2 "< 5m" 3 "< 10m" 4 "< 20m" 5 "< 50m" 6 "> 50m" 7 "Off-Road" ;
VAL_ 1123 PSD_Pos_Fahrspur 0 "unbekannt" 1 "Erste_Spur_von_rechts" 2 "Zweite_Spur_von_rechts" 3 "Dritte_Spur_von_rechts" 4 "Vierte_Spur_von_rechts" 5 "Fuenfte_Spur_von_rechts" 6 "Sechte_Spur_von_rechts" 7 "Siebte_oder_weitere_Spur_von_rechts" ;
VAL_ 1123 PSD_Attribut_Segment_ID_05 0 "keine_Segment_Information" 1 "Fehler" ;
VAL_ 1123 PSD_Attribut_1_ID 0 "keine_Information" ;
VAL_ 1123 PSD_Attribut_2_ID 0 "keine_Information" ;
VAL_ 1123 PSD_Attribute_Komplett_05 0 "Attribute_nicht_komplett" 1 "Attribute_komplett" ;
VAL_ 1124 PSD_06_Mux 0 "Init" ;
VAL_ 1124 PSD_Sys_Segment_ID 0 "keine Segmentinformationen vorhanden" 1 "nicht zulaessig" ;
VAL_ 1124 PSD_Attribut_Segment_ID 0 "keine_Segment_Information_vorhanden" 1 "Fehler" ;
VAL_ 1124 PSD_Ges_Segment_ID 0 "keine Segmentinformationen vorhanden" 1 "nicht zulaessig" ;
VAL_ 1124 PSD_Baum_Laenge_VZ 0 "Ost" 1 "West" ;
VAL_ 1124 PSD_Steigung_1_Segment_ID 0 "keine_Segment_Information_vorhanden" 1 "Fehler" ;
VAL_ 1124 PSD_Baum_Laenge 33554431 "keine_GPS_Information" ;
VAL_ 1124 PSD_Attribut_3_ID 0 "keine_Information" ;
VAL_ 1124 PSD_Steigung_1_A_Steigung 126 "mehr_als_15_Prozent" 127 "Steigung_unbekannt" ;
VAL_ 1124 PSD_Ges_Geschwindigkeit 0 "Kein Geschwindigkeitsgebot" 1 "0 km/h < v_max <  5 km/h" 2 "5 km/h < v_max < 10km/h" 3 "10 km/h < v_max < 15 km/h" 4 "15 km/h < v_max < 20 km/h" 5 "20 km/h < v_max < 25 km/h" 6 "25 km/h < v_max < 30 km/h" 7 "30 km/h < v_max < 35 km/h" 8 "35 km/h < v_max < 40 km/h" 9 "40 km/h < v_max < 45 km/h" 10 "45 km/h < v_max < 50 km/h" 11 "50 km/h < v_max < 60 km/h" 12 "60 km/h < v_max < 70 km/h" 13 "70 km/h < v_max < 80 km/h" 14 "80 km/h < v_max < 90 km/h" 15 "90 km/h < v_max < 100 km/h" 16 "100 km/h < v_max < 110 km/h" 17 "110 km/h < v_max < 120 km/h" 18 " 120 km/h < v_max < 130 km/h" 19 "130 km/h < v_max < 140 km/h" 20 "140 km/h < v_max < 150 km/h" 21 "150 km/h < v_max < 160 km/h" 22 "160 km/h < v_max" 23 "Geschwindigkeitsgebot aufgehoben" 24 "..0x1F ungültig" ;
VAL_ 1124 PSD_Steigung_1_A_Vorz 0 "Gefaelle" 1 "Steigung" ;
VAL_ 1124 PSD_Sys_Geschwindigkeit_Einheit 0 "km/h" 1 "mph" ;
VAL_ 1124 PSD_Sys_Verkehrsrichtung 0 "Rechtsverkehr" 1 "Linksverkehr" ;
VAL_ 1124 PSD_Sys_Geometrieguete 0 "Geringe_Guete" 1 "tbd" 2 "tbd" 3 "Hohe_Guete" ;
VAL_ 1124 PSD_Sys_Mapmatchingguete 0 "geringe_Guete" 1 "res" 2 "res" 3 "hohe_Guete" ;
VAL_ 1124 PSD_Ges_Typ 0 "Geschw_Klasse_des_Kartendatensuppliers" 1 "Explizit_abgeleiteten_Begrenzung" 2 "Durch_Gesetzg_vorgeg_allgem_Gebot_fuer_uebertr_Rahmenbed" 3 "Init" ;
VAL_ 1124 PSD_Sys_Alter_Karte 0 "kleiner_1_Jahr" 1 "1_Jahr" 2 "2_Jahre" 3 "3_Jahre" 4 "4_Jahre" 5 "5_Jahre" 6 "6_Jahre" 7 "groesser_7_Jahre" ;
VAL_ 1124 PSD_Ges_Spur_Geschw_Begrenzung 0 "Gebot_fuer_alle_spuren_gueltig" ;
VAL_ 1124 PSD_Steigung_1_B_Steigung 126 "mehr_als_15_Prozent" 127 "Steigung_unbekannt" ;
VAL_ 1124 PSD_Attribut_4_ID 0 "keine_Information" ;
VAL_ 1124 PSD_Sys_Zielfuehrung 0 "Zielfuehrung nicht aktiv" 1 "Zielfuehrung aktiv" ;
VAL_ 1124 PSD_Sys_US_State 0 "kein_US_State" 1 "Alabama" 2 "Alaska" 3 "Arizona" 4 "Arkansas" 5 "California" 6 "Chihuahua" 7 "Colorado" 8 "Connecticut" 9 "Delaware" 10 "Florida" 11 "Georgia" 12 "Hawaii" 13 "Idaho" 14 "Illinois" 15 "Indiana" 16 "Iowa" 17 "Kansas" 18 "Kentucky" 19 "Louisiana" 20 "Maine" 21 "Maryland" 22 "Massachusetts" 23 "Michigan" 24 "Minnesota" 25 "Mississippi" 26 "Missouri" 27 "Montana" 28 "Nebraska" 29 "Nevada" 30 "New_Hampshire" 31 "New_Jersey" 32 "New_Mexico" 33 "New_York" 34 "North_Carolina" 35 "North_Dakota" 36 "Ohio" 37 "Oklahoma" 38 "Oregon" 39 "Pennsylvania" 40 "Rhode_Island" 41 "South_Carolina" 42 "South_Dakota" 43 "Tennessee" 44 "Texas" 45 "Utah" 46 "Vermont" 47 "Virginia" 48 "Washington" 49 "West_Virginia" 50 "Wisconsin" 51 "Wyoming" ;
VAL_ 1124 PSD_Ges_Geschwindigkeit_Gespann 0 "alle Fahrzeuge" 1 "PKW mit Gespann" 2 "LKW, Busse, etc." ;
VAL_ 1124 PSD_Baum_Breite_VZ 0 "Nord" 1 "Sued" ;
VAL_ 1124 PSD_Ges_Geschwindigkeit_Witter 0 "Witterungsunabhängig" 1 "Nässe, Regen, Niederschlag" 2 "Glätte" 3 "Nebel" ;
VAL_ 1124 PSD_Steigung_1_B_Vorz 0 "Gefaelle" 1 "Steigung" ;
VAL_ 1124 PSD_Ges_Geschwindigkeit_Tag_Anf 0 "kein Beginn definiert" 1 "Montag" 2 "Dienstag" 3 "Mittwoch" 4 "Donnerstag" 5 "Freitag" 6 "Samstag" 7 "Sonntag" ;
VAL_ 1124 PSD_Ges_Geschwindigkeit_Tag_Ende 0 "kein Ende definiert" 1 "Montag" 2 "Dienstag" 3 "Mittwoch" 4 "Donnerstag" 5 "Freitag" 6 "Samstag" 7 "Sonntag" ;
VAL_ 1124 PSD_Ges_Geschwindigkeit_Std_Anf 25 "kein Beginn für stundenweise Einschränkungen" ;
VAL_ 1124 PSD_Steigung_1_Attribute_kompl 0 "Steigungen_nicht_komplett" 1 "Steigungen_komplett" ;
VAL_ 1124 PSD_Steigung_2_Segment_ID 0 "keine_Segment_Information_vorhanden" 1 "Fehler" ;
VAL_ 1124 PSD_Attribut_5_ID 0 "keine_Information" ;
VAL_ 1124 PSD_Ges_Geschwindigkeit_Std_Ende 25 "kein Ende für stundenweise Einschränkungen" ;
VAL_ 1124 PSD_Steigung_2_Steigung 126 "mehr_als_15_Prozent" 127 "Steigung_unbekannt" ;
VAL_ 1124 PSD_Ges_Ueberholverbot 0 "kein Überholverbot" 1 "alle Fahrzeuge" 2 "Überholverbot für PKW mit Gespann" 3 "Überholverbot für LKW, Busse, etc." ;
VAL_ 1124 PSD_Ges_Wechselverkehrszeichen 0 "Kein Wechselverkehrszeichen" 1 "Wechselverkehrszeichen links" 2 "Wechselverkehrszeichen rechts" 3 "Wechselverkehrszeichen links und rechts" 4 "Wechselverkerhszeichen über der Fahrbahn" ;
VAL_ 1124 PSD_Steigung_2_Vorz 0 "Gefaelle" 1 "Steigung" ;
VAL_ 1124 PSD_Wechselverkehrszeichen_Typ 0 "kein_Wechselverkehrszeichen" 1 "LED_Wechselverkehrszeichen" 2 "nicht_LED_Wechselverkehrszeichen" ;
VAL_ 1124 PSD_Ges_Gesetzlich_Kategorie 0 "kein_legales_Verbot" 1 "innerorts" 2 "ausserorts" 3 "Autobahn" ;
VAL_ 1124 PSD_Attribute_Komplett_06 0 "Attribute_nicht_komplett" 1 "Attribute_komplett" ;
VAL_ 1124 PSD_Ges_Gesetzlich_Zusatz 0 "kein_Zusatz_zu_legalem_Gebot" 1 "Anhaenger_Klasse_1" 2 "Anhaenger_Klasse_2" ;
VAL_ 1124 PSD_Ges_Verkehrszeichen_Quelle 0 "VZA_kein_Onlinedienst" 1 "nur_VZA" 2 "nur_VZO" 3 "VZA_und_VZO" ;
VAL_ 1124 PSD_Steigung_2_Attribute_kompl 0 "Steigungen_nicht_komplett" 1 "Steigungen_komplett" ;
VAL_ 1124 PSD_Ges_Attribute_Komplett 0 "Attribute_nicht_komplett" 1 "Attribute_komplett" ;
VAL_ 695 RCTA_Info_rechts 0 "RCTA_hat_rechts_nichts_erkannt" 1 "RCTA_hat_rechts_blind_erkannt" 2 "RCTA_hat_rechts_frei_erkannt" 3 "RCTA_hat_rechts_unkritisch_erkannt" 4 "RCTA_hat_rechts_relevant_aber_unkritisch_erkannt" 5 "RCTA_hat_rechts_kritisch_erkannt" 6 "RCTA_hat_rechts_sehr_kritisch_erkannt" 7 "RCTA_meldet_rechts_Kollision_steht_bevor" ;
VAL_ 695 RCTA_Anforderung_HMS 0 "keine Anforderung" 1 "halten" 2 "parken" 3 "Halten Standby" 4 "anfahren" 5 "loesen_ueber_Rampe" ;
VAL_ 695 RCTA_Bremsruck_Anforderung 0 "nicht_angefordert" 1 "angefordert" ;
VAL_ 695 RCTA_Bremsruck_Freigabe 0 "keine_Freigabe" 1 "Freigabe" ;
VAL_ 695 RCTA_Info_links 0 "RCTA_hat_links_nichts_erkannt" 1 "RCTA_hat_links_blind_erkannt" 2 "RCTA_hat_links_frei_erkannt" 3 "RCTA_hat_links_unkritisch_erkannt" 4 "RCTA_hat_links_relevant_aber_unkritisch_erkannt" 5 "RCTA_hat_links_kritisch_erkannt" 6 "RCTA_hat_links_sehr_kritisch_erkannt" 7 "RCTA_meldet_links_Kollision_steht_bevor" ;
VAL_ 695 RCTA_Status 0 "Aus" 1 "Passiv" 2 "Aktiv" 3 "Fehler" ;
VAL_ 695 RCTA_Warnton 0 "Aus" 1 "Ein" ;
VAL_ 695 RCTA_Notbremsung_Freigabe 0 "keine_Freigabe" 1 "Freigabe" ;
VAL_ 695 RCTA_Notbremsung_Anforderung 0 "Init" 255 "Fehler" ;
VAL_ 1440 LS_Helligkeit_IR 254 "Init" 255 "Fehler" ;
VAL_ 1440 LS_Helligkeit_FW 1022 "Init" 1023 "Fehler" ;
VAL_ 1440 LS_defekt 0 "OK" 1 "defekt" ;
VAL_ 1440 LS_Verbau 1 "Lichtsensor verbaut" ;
VAL_ 1440 RS_Regenmenge 14 "Init" 15 "Fehler" ;
VAL_ 1440 RS_Verbau 1 "Regensensor verbaut" ;
VAL_ 1440 RS_Verglasung_schliessen 0 "Verglasung nicht schliessen" 1 "Verglasung schliessen" ;
VAL_ 1440 RS_defekt 0 "OK" 1 "defekt" ;
VAL_ 1440 RS_Wischergeschwindigkeit 0 "kein Wischen" 1 "42 Huebe/min" 2 "45 Huebe/min" 3 "48 Huebe/min" 4 "51 Huebe/min" 5 "54 Huebe/min" 6 "57 Huebe/min" 7 "60 Huebe/min" ;
VAL_ 1440 RLS_Vorfeldhelligkeit_Boost 0 "groesser_24413_Lux" 1 "bis_24413_Lux" 2 "bis_22193_Lux" 3 "bis_20176_Lux" 4 "bis_18342_Lux" 5 "bis_16647_Lux" 6 "bis_15158_Lux" 7 "bis_13780_Lux" 8 "bis_12527_Lux" 9 "bis_11388_Lux" 10 "bis_10353_Lux" 11 "bis_9412_Lux" 12 "bis_8556_Lux" 13 "bis_7778_Lux" 14 "bis_7071_Lux" 15 "bis_6428_Lux" ;
VAL_ 684 SDF_PSF_Objektstatus 0 "kein_relevantes_Obj" 1 "relevantes_Obj_vorausfahrend" 2 "relevantes_Obj_stehend" 3 "relevantes_Obj_angehalten" 4 "relevantes_Obj_entgegenkommend" 7 "Fehler" ;
VAL_ 684 SDF_PSF_Fahrer_aktiv 0 "Fahrer_nicht_aktiv" 1 "Fahrer_aktiv" ;
VAL_ 684 SDF_PSF_Time_To_Collision 254 "Init" 255 "Fehler" ;
VAL_ 684 SDF_PSF_v_rel 0 "Objektstatus_0" 254 "Init" 255 "Fehler" ;
VAL_ 684 SDF_PSF_Kollisionsueberdeckung 0 "Keine_Ueberdeckung" 29 "Ueberdeckung_groesser_Maximalwert" 30 "Init" 31 "Fehler" ;
VAL_ 684 SDF_PSF_01_Sendestatus 0 "Senden_mit_langsamer_Zykluszeit" 1 "Senden_mit_schneller_Zykluszeit" ;
VAL_ 684 SDF_PSF_CU_Status 0 "Kollision_vermeidbar" 1 "Kollision_unvermeidbar" ;
VAL_ 684 SDF_PSF_CW 126 "Init" 127 "Fehler" ;
VAL_ 684 SDF_PSF_Guete 0 "Modellguete_niO_keine_Plausi" 1 "Modellguete_niO_plausibilisiert" 2 "Modellguete_iO_keine_Plausi" 3 "Modellguete_iO_plausibilisiert" ;
VAL_ 783 SWA_Anzeigen 0 "keine_Anzeige" 1 "Text_1_SWA_zurzeit_nicht_verfuegbar" 2 "Text_2_SWA_Systemstoerung" 3 "Text_3_SWA_zurzeit_nicht_verfuegbar_Keine_Sensorsicht" 4 "Text_4_SWA_zurzeit_nicht_verfuegbar_Anhaengerbetrieb" ;
VAL_ 783 SWA_Blindheit_erkannt 0 "nicht erkannt" 1 "erkannt" ;
VAL_ 783 SWA_rel_Nichtverf 0 "verfuegbar" 1 "nicht verfuegbar" ;
VAL_ 783 SWA_rel_Fehler 0 "kein Fehler" 1 "Fehler" ;
VAL_ 783 SWA_Sta_aktiv 0 "Aus" 1 "Ein" ;
VAL_ 783 SWA_Sta_passiv 0 "Aus" 1 "Ein" ;
VAL_ 783 SWA_FT_RueckLED 0 "inaktiv" 1 "aktiv" ;
VAL_ 783 ASW_Status 0 "Passiv" 1 "Aktiv" 2 "Fehler" 3 "AUS" ;
VAL_ 783 SWA_Standziele_li 0 "Abstand i.O." 1 "Abstand zu gering" ;
VAL_ 783 SWA_Kolonne_li 0 "zwei_oder_weniger_Fahrzeuge_auf_der_Spur" 1 "mehr_als_zwei_Fahrzeuge_auf_der_Spur" ;
VAL_ 783 SWA_Infostufe_SWA_li 0 "keine_Aktion" 1 "Aktion" ;
VAL_ 783 SWA_Warnung_SWA_li 0 "keine Warnung" 1 "Warnung aktiv" ;
VAL_ 783 ASW_Warnung_FS 0 "inaktiv" 1 "aktiv" ;
VAL_ 783 ASW_Warnung_BFS 0 "inaktiv" 1 "aktiv" ;
VAL_ 783 ASW_Kombitexte 0 "keine Anzeige.    //    Prio 5" 1 "Text_1_ASW_zur_Zeit_nicht_verfuegbar_und_Akustik    //    Prio 2" 2 "Text_2_ASW_Systemfehler_und_Akustik    //    Prio 1" 3 "Text_3_ASW_Sensor_blockiert_und_Akustik    //    Prio 3" 4 "Text_4_ASW_im_Anhaengerbetrieb_nicht_verfuegbar_und_Akustik    //    Prio 4" 5 "reserviert" 6 "reserviert" 7 "Text_7_Vorhalt_ASW_aus" ;
VAL_ 783 SWA_Kolonne_mi 0 "zwei_oder_weniger_Fahrzeuge_auf_der_Spur" 1 "mehr_als_zwei_Fahrzeuge_auf_der_Spur" ;
VAL_ 783 SWA_Standziele_re 0 "Abstand i.O." 1 "Abstand zu gering" ;
VAL_ 783 SWA_Kolonne_re 0 "zwei_oder_weniger_Fahrzeuge_auf_der_Spur" 1 "mehr_als_zwei_Fahrzeuge_auf_der_Spur" ;
VAL_ 783 SWA_Infostufe_SWA_re 0 "keine_Aktion" 1 "Aktion" ;
VAL_ 783 SWA_Warnung_SWA_re 0 "keine Warnung" 1 "Warnung aktiv" ;
VAL_ 783 HRE_Anzeigetexte 0 "keine Anzeige" 1 "HRE zur Zeit nicht verfügbar" 2 "HRE Systemfehler" 3 "HRE nicht verfügbar. Sensor blockiert" 4 "HRE im Anhängerbetrieb nicht verfügbar" 5 "RTA-Warnung" 6 "BSD-Warnung" 7 "Fahrerübernahme Notbremsung" 8 "RTA nicht verfügbar" ;
VAL_ 783 Heckradar_Kombitexte 0 "keine Anzeige.    //    Prio 5" 1 "Text_1_SWA_und_ASW_zur_Zeit_nicht_verfuegbar_und_Akustik    //    Prio 2" 2 "Text_2_SWA_und_ASW_Systemfehler_und_Akustik    //    Prio 1" 3 "Text_3_SWA_und_ASW_Sensor_blockiert_und_Akustik    //    Prio 3" 4 "Text_4_SWA_und_ASW_im_Anhaengerbetrieb_nicht_verfuegbar_und_Akustik    //    Prio 4" 5 "Text_1_SWA_und_RCTA_zur_Zeit_nicht_verfuegbar_und_Akustik // Prio 2" 6 "Text_2_SWA_und_RCTA_Systemfehler_und_Akustik // Prio 1" 7 "		Text_3_SWA_und_RCTA_Sensor_blockiert_und_Akustik // Prio 3" 8 "Text_4_SWA_und_RCTA_im_Anhaengerbetrieb_nicht_verfuegbar_und_Akustik // Prio 4" 9 "Text_1_ASW_und_RCTA_zur_Zeit_nicht_verfuegbar_und_Akustik // Prio 2" 10 "Text_2_ASW_und_RCTA_Systemfehler_und_Akustik // Prio 1" 11 "Text_3_ASW_und_RCTA_Sensor_blockiert_und_Akustik // Prio 3" 12 "Text_4_ASW_und_RCTA_im_Anhaengerbetrieb_nicht_verfuegbar_und_Akustik // Prio 4" 13 "Text_1_SWA_und_ASW_und_RCTA_zur_Zeit_nicht_verfuegbar_und_Akustik // Prio 2" 14 "Text_2_SWA_und_ASW_und_RCTA_Systemfehler_und_Akustik // Prio 1" 15 "Text_3_SWA_und_ASW_und_RCTA_Sensor_blockiert_und_Akustik // Prio 3" 16 "Text_4_SWA_und_ASW_und_RCTA_im_Anhaengerbetrieb_nicht_verfuegbar_und_Akustik // Prio 4" 17 "reserviert" 18 "reserviert" 19 "reserviert" 20 "reserviert" 21 "reserviert" 22 "reserviert" 23 "reserviert" 24 "reserviert" 25 "reserviert" 26 "reserviert" 27 "reserviert" 28 "reserviert" 29 "reserviert" ;
VAL_ 783 RCTA_Kombitexte 0 "keine Anzeige.    //    Prio 7" 1 "Text_1_RCTA_zur_Zeit_nicht_verfuegbar_und_Akustik    //    Prio 4" 2 "Text_2_RCTA_Systemfehler_und_Akustik    //    Prio 3" 3 "Text_3_RCTA_Sensor_blockiert_und_Akustik    //    Prio 5" 4 "Text_4_RCTA_im_Anhaengerbetrieb_nicht_verfuegbar_und_Akustik    //    Prio 6" 5 "Text_5_RTA_Warnung (VW)    //    Prio 1" 6 "Text_6_Fahreruebernahme_Notbremsung (VW)    //    Prio 2" 7 "reserviert" ;
VAL_ 1413 SI_Sammel_SG_Fehler 61 "Reserviert" 62 "Overflow" 63 "ungueltig" ;
VAL_ 1413 SI_Diagnose_Aktiv 0 "inaktiv" 1 "aktiv" ;
VAL_ 1413 SI_QRS_Mode 0 "QRS_Messmodus_nicht_aktiv" 1 "QRS_Messmodus_aktiv" ;
VAL_ 1413 SI_T_Mode 0 "Transportmodus_nicht_aktiv" 1 "Transportmodus_aktiv" ;
VAL_ 1413 SI_NWDF 0 "Ueberwachung_nicht_freigegeben" 1 "Ueberwachung_freigegeben" ;
VAL_ 1413 SI_NWDF_gueltig 0 "NWDF_wird_nicht_unterstuetzt" 1 "NWDF_wird_unterstuetzt" ;
VAL_ 1413 SI_Sammelfehler 0 "kein_Sammelfehler" 1 "Sammelfehler" ;
VAL_ 1413 GW_KD_Fehler 0 "kein_KD_Fehler" 1 "KD_Fehler" ;
VAL_ 1413 SI_T_Schutz 0 "Transportschutz_nicht_aktiv" 1 "Transportschutz_aktiv" ;
VAL_ 1413 SI_BUS_01 0 "keine_Busruhe" 1 "Busruhe" ;
VAL_ 1413 SI_BUS_02 0 "keine_Busruhe" 1 "Busruhe" ;
VAL_ 1413 SI_BUS_03 0 "keine_Busruhe" 1 "Busruhe" ;
VAL_ 1413 SI_BUS_04 0 "keine_Busruhe" 1 "Busruhe" ;
VAL_ 1413 SI_BUS_05 0 "keine_Busruhe" 1 "Busruhe" ;
VAL_ 1413 SI_BUS_06 0 "keine_Busruhe" 1 "Busruhe" ;
VAL_ 1413 SI_BUS_07 0 "keine_Busruhe" 1 "Busruhe" ;
VAL_ 1413 SI_BUS_08 0 "keine_Busruhe" 1 "Busruhe" ;
VAL_ 1413 SI_BUS_09 0 "keine_Busruhe" 1 "Busruhe" ;
VAL_ 1413 SI_BUS_10 0 "keine_Busruhe" 1 "Busruhe" ;
VAL_ 1413 SI_BUS_11 0 "keine_Busruhe" 1 "Busruhe" ;
VAL_ 1413 SI_BUS_12 0 "keine_Busruhe" 1 "Busruhe" ;
VAL_ 1413 SI_BUS_13 0 "keine_Busruhe" 1 "Busruhe" ;
VAL_ 1413 SI_BUS_14 0 "keine_Busruhe" 1 "Busruhe" ;
VAL_ 1413 SI_BUS_15 0 "keine_Busruhe" 1 "Busruhe" ;
VAL_ 1413 SI_Bus_Identifikation 16 "CAN_Diagnose" 17 "CAN_Antrieb" 18 "CAN_Komfort" 19 "CAN_Infotainment" 20 "CAN_Fahrwerk" 21 "CAN_Extended" 22 "CAN_Hybrid" 23 "CAN_Lade" 24 "CAN_Kombi" 25 "CAN_Komfort_2" 48 "FlexRay_A" 49 "FlexRay_B" ;
VAL_ 997 FT_Tuer_Status 0 "Init" 1 "Tuer_geschlossen" 2 "Tuer_offen" 3 "Fehler" ;
VAL_ 997 FT_Tuer_Status_QBit 0 "Status_Tuerkontakt_sicher" 1 "Status_Tuerkontakt_unsicher" ;
VAL_ 997 FT_Lock_Taster_02 0 "nicht_betaetigt" 1 "betaetigt" ;
VAL_ 997 FT_Schluesselschalter_zu_02 0 "nicht_betaetigt" 1 "betaetigt" ;
VAL_ 997 FT_BFS_Tuer_Status 0 "Init" 1 "Tuer_geschlossen" 2 "Tuer_offen" 3 "Fehler" ;
VAL_ 997 FT_HBFS_Tuer_Status 0 "Init" 1 "Tuer geschlossen" 2 "Tuer offen" 3 "Fehler" ;
VAL_ 997 FT_HFS_Tuer_Status 0 "Init" 1 "Tuer geschlossen" 2 "Tuer offen" 3 "Fehler" ;
VAL_ 997 FT_Tuerschloss_verrieg_nicht 0 "Türschloss kann verriegelt werden" 1 "Türschloss kann nicht verriegelt werden" ;
VAL_ 997 FT_SP_Heizung_ein 0 "Aus" 1 "Ein" ;
VAL_ 997 FT_Kisi_Taster_li_02 0 "nicht_betaetigt" 1 "betaetigt" ;
VAL_ 997 FT_Kisi_Taster_re_02 0 "nicht_betaetigt" 1 "betaetigt" ;
VAL_ 997 FT_TD_Taste_Status 0 "kein_Fehler" 1 "Kurzschluss_nach_Minus" 2 "Kurzschluss_nach_Plus" 3 "Leitungsunterbrechung" ;
VAL_ 288 TSK_Status 0 "Hauptschalter_aus" 1 "Init" 2 "passiv" 3 "aktiv" 4 "Uebertreten" 5 "brake_only_Mode" 6 "reversibel_aus" 7 "irreversibel_aus" ;
VAL_ 288 TSK_v_Begrenzung_aktiv 0 "inaktiv" 1 "aktiv" ;
VAL_ 288 TSK_Standby_Anf_ESP 0 "keine_Standby_Anforderung" 1 "Standby_Anforderung" ;
VAL_ 288 TSK_Freig_WU 0 "TSK_Uebersetzungswunsch_nicht_freigegeben" 1 "TSK_Uebersetzungswunsch_freigegeben" ;
VAL_ 288 TSK_Freig_Verzoeg_Anf 0 "Verzoegerungsanforderung_nicht_freigegeben" 1 "Verzoegerungsanforderung_freigegeben" ;
VAL_ 288 TSK_Limiter_ausgewaehlt 0 "kein_Limiter_ausgewaehlt" 1 "Limiter_ausgewaehlt" ;
VAL_ 288 TSK_Wunsch_Uebersetz 0 "Init" ;
VAL_ 288 TSK_Hauptschalter_GRA_ACC 0 "Init" 1 "Aus" 2 "Ein" 3 "Fehler" ;
VAL_ 288 TSK_ax_Getriebe_02 511 "Neutralwert" ;
VAL_ 288 TSK_Zwangszusch_ESP 0 "keine_ESP_ASR_Beeinflussung" 1 "ESP_ASR_Beeinflussung" ;
VAL_ 346 MO_Anforderung_HMS 0 "keine_Anforderung" 1 "halten" 2 "parken" 3 "halten_Standby" 4 "anfahren" 5 "Loesen_ueber_Rampe" ;
VAL_ 346 TSK_Status_EA 0 "Aus" 1 "Init_oder_nicht_verbaut" 3 "Aktiv" 4 "Uebertreten" 5 "Abschaltung_laeuft" 6 "Reversibel_aus" 7 "Irreversibel_Aus" ;
VAL_ 346 TSK_vMax_Fahrerassistenz 511 "Init_ungueltig_keine_Beschraenkung" ;
VAL_ 346 TSK_Einheit_vMax_Fahrerassistenz 0 "kmh" 1 "mph" ;
VAL_ 346 TSK_Status_PLA 0 "Aus_Funktionsbereit" 1 "Init_oder_nicht_verbaut" 2 "aktivierbar" 3 "aktiv" 5 "Abschaltung_laeuft" 6 "reversibel_aus" 7 "Fehler" ;
VAL_ 346 TSK_aktives_System 0 "keine_Funktion_aktiv" 1 "GRA_ACC" 2 "ARA" 3 "Speedlimiter" 4 "IPA" 5 "PLA" 6 "PEA_Ausrollassistent" 7 "EA" ;
VAL_ 346 TSK_erhoehter_Fahrwiderstand 0 "kein_erhoehter_Fahrwiderstand" 1 "erhoehter_Fahrwiderstand" ;
VAL_ 346 TSK_Anf_Antriebsmoment 0 "keine_Anforderung" 1 "Anforderung_aktiv" ;
VAL_ 346 TSK_Status_ARA 0 "Aus" 1 "Init_oder_nicht_verbaut" 2 "aktivierbar" 3 "aktiv" 5 "abschaltung_laeuft" 6 "reversibel_aus" 7 "Fehler" ;
VAL_ 346 TSK_Status_IPA 0 "Aus_Funktionsbereit" 1 "Init_oder_nicht_verbaut" 2 "aktivierbar" 3 "aktiv" 5 "Abschaltung_laueft" 6 "reversibel_aus" 7 "Fehler" ;
VAL_ 1019 TSK_Ausrollkurve_Schub_Reku_01 127 "Init" ;
VAL_ 1019 TSK_Ausrollkurve_Schub_Reku_05 127 "Init" ;
VAL_ 1019 TSK_Ausrollkurve_Schub_Reku_09 127 "Init" ;
VAL_ 1019 TSK_Ausrollkurve_Schub_Reku_13 127 "Init" ;
VAL_ 1019 TSK_Ausrollkurve_Schub_Reku_17 127 "Init" ;
VAL_ 1019 TSK_Ausrollkurve_Schub_Reku_02 127 "Init" ;
VAL_ 1019 TSK_Ausrollkurve_Schub_Reku_06 127 "Init" ;
VAL_ 1019 TSK_Ausrollkurve_Schub_Reku_10 127 "Init" ;
VAL_ 1019 TSK_Ausrollkurve_Schub_Reku_14 127 "Init" ;
VAL_ 1019 TSK_Ausrollkurve_Schub_Reku_18 127 "Init" ;
VAL_ 1019 TSK_Ausrollkurve_Schub_Reku_03 127 "Init" ;
VAL_ 1019 TSK_Ausrollkurve_Schub_Reku_07 127 "Init" ;
VAL_ 1019 TSK_Ausrollkurve_Schub_Reku_11 127 "Init" ;
VAL_ 1019 TSK_Ausrollkurve_Schub_Reku_15 127 "Init" ;
VAL_ 1019 TSK_Ausrollkurve_Schub_Reku_19 127 "Init" ;
VAL_ 1019 TSK_Ausrollkurve_Schub_Reku_04 127 "Init" ;
VAL_ 1019 TSK_Ausrollkurve_Schub_Reku_08 127 "Init" ;
VAL_ 1019 TSK_Ausrollkurve_Schub_Reku_12 127 "Init" ;
VAL_ 1019 TSK_Ausrollkurve_Schub_Reku_16 127 "Init" ;
VAL_ 1019 TSK_Ausrollkurve_Schub_Reku_20 127 "Init" ;
VAL_ 1019 TSK_Ausrollkurve_Segeln_01 127 "Init" ;
VAL_ 1019 TSK_Ausrollkurve_Segeln_05 127 "Init" ;
VAL_ 1019 TSK_Ausrollkurve_Segeln_09 127 "Init" ;
VAL_ 1019 TSK_Ausrollkurve_Segeln_13 127 "Init" ;
VAL_ 1019 TSK_Ausrollkurve_Segeln_17 127 "Init" ;
VAL_ 1019 TSK_Ausrollkurve_Segeln_02 127 "Init" ;
VAL_ 1019 TSK_Ausrollkurve_Segeln_06 127 "Init" ;
VAL_ 1019 TSK_Ausrollkurve_Segeln_10 127 "Init" ;
VAL_ 1019 TSK_Ausrollkurve_Segeln_14 127 "Init" ;
VAL_ 1019 TSK_Ausrollkurve_Segeln_18 127 "Init" ;
VAL_ 1019 TSK_Ausrollkurve_Segeln_03 127 "Init" ;
VAL_ 1019 TSK_Ausrollkurve_Segeln_07 127 "Init" ;
VAL_ 1019 TSK_Ausrollkurve_Segeln_11 127 "Init" ;
VAL_ 1019 TSK_Ausrollkurve_Segeln_15 127 "Init" ;
VAL_ 1019 TSK_Ausrollkurve_Segeln_19 127 "Init" ;
VAL_ 1019 TSK_Ausrollkurve_Segeln_04 127 "Init" ;
VAL_ 1019 TSK_Ausrollkurve_Segeln_08 127 "Init" ;
VAL_ 1019 TSK_Ausrollkurve_Segeln_12 127 "Init" ;
VAL_ 1019 TSK_Ausrollkurve_Segeln_16 127 "Init" ;
VAL_ 1019 TSK_Ausrollkurve_Segeln_20 127 "Init" ;
VAL_ 1019 TSK_Ausrollkurve_Reku 0 "Rekuperation_nicht_beruecksichtigt" 1 "Rekuperation_beruecksichtigt" ;
VAL_ 1019 TSK_Ausrollkurve_Schrittweite 0 "Normale_Schrittweite" 1 "Grosse_Schrittweite" ;
VAL_ 385 VZE_Anzeigemodus 0 "EU_RDW" 1 "USA" 2 "Canada" 3 "reserviert" ;
VAL_ 385 VZE_Hinweistext 0 "kein_Hinweistext" ;
VAL_ 385 VZE_Statuszaehler_1 0 "stoppe_Distanzzaehler_zeige_Zaehler_nicht_an_Initialwert_Fehlerwert" 1 "setze_Distanzzaehler_zurueck_und_zeige_Zaehler_nicht_an" 2 "starte_Distanzzaehler_und_zeige_Zaehler_an" 3 "starte_zurueckgesetzten_Distanzzaehler_und_zeige_Zaehler_an" ;
VAL_ 385 VZE_Statuszaehler_2 0 "stoppe_Distanzzaehler_zeige_Zaehler_nicht_an_Initialwert_Fehlerwert" 1 "setze_Distanzzaehler_zurueck_und_zeige_Zaehler_nicht_an" 2 "starte_Distanzzaehler_und_zeige_Zaehler_an" 3 "starte_zurueckgesetzten_Distanzzaehler_und_zeige_Zaehler_an" ;
VAL_ 385 VZE_Statuszaehler_3 0 "stoppe_Distanzzaehler_zeige_Zaehler_nicht_an_Initialwert_Fehlerwert" 1 "setze_Distanzzaehler_zurueck_und_zeige_Zaehler_nicht_an" 2 "starte_Distanzzaehler_und_zeige_Zaehler_an" 3 "starte_zurueckgesetzten_Distanzzaehler_und_zeige_Zaehler_an" ;
VAL_ 385 VZE_Verkehrszeichen_1 0 "kein_Verkehrszeichen" ;
VAL_ 385 VZE_Verkehrszeichen_2 0 "kein_Verkehrszeichen" ;
VAL_ 385 VZE_Verkehrszeichen_3 0 "kein_Verkehrszeichen" ;
VAL_ 385 VZE_Warnung_Verkehrszeichen_1 0 "keine_Warnung_Initialwert_Fehlerwert" 1 "Warnung" ;
VAL_ 385 VZE_Warnung_Verkehrszeichen_2 0 "keine_Warnung_Initialwert_Fehlerwert" 1 "Warnung" ;
VAL_ 385 VZE_Warnung_Verkehrszeichen_3 0 "keine_Warnung_Initialwert_Fehlerwert" 1 "Warnung" ;
VAL_ 385 VZE_Zusatzschild_1 0 "keine_Zusatzschild_Initialwert_Fehlerwert" ;
VAL_ 385 VZE_Zusatzschild_2 0 "keine_Zusatzschild_Initialwert_Fehlerwert" ;
VAL_ 385 VZE_Zusatzschild_3 0 "keine_Zusatzschild_Initialwert_Fehlerwert" ;
VAL_ 385 VZE_Hinweistext_02 0 "kein_Hinweistext" ;
VAL_ 668 VZE_Statuszaehler_4 0 "stoppe_Distanzzaehler_zeige_Zaehler_nicht_an_Initialwert_Fehlerwert" 1 "setze_Distanzzaehler_zurueck_und_zeige_Zaehler_nicht_an" 2 "starte_Distanzzaehler_und_zeige_Zaehler_an" 3 "starte_zurueckgesetzten_Distanzzaehler_und_zeige_Zaehler_an" ;
VAL_ 668 VZE_Statuszaehler_5 0 "stoppe_Distanzzaehler_zeige_Zaehler_nicht_an_Initialwert_Fehlerwert" 1 "setze_Distanzzaehler_zurueck_und_zeige_Zaehler_nicht_an" 2 "starte_Distanzzaehler_und_zeige_Zaehler_an" 3 "starte_zurueckgesetzten_Distanzzaehler_und_zeige_Zaehler_an" ;
VAL_ 668 VZE_Zeichen_05_KameraWied 0 "inaktiv" 1 "aktiv" ;
VAL_ 668 VZE_Zeichen_05_Kamera 0 "nicht_erkannt" 1 "erkannt" ;
VAL_ 668 VZE_Verkehrszeichen_4 0 "kein_Verkehrszeichen" ;
VAL_ 668 VZE_Verkehrszeichen_5 0 "kein_Verkehrszeichen" ;
VAL_ 668 VZE_Anhaenger_Vmax 14 "Init" 15 "Fehler" ;
VAL_ 668 VZE_Zeichen_04_Gesetz 0 "nicht_erkannt" 1 "erkannt" ;
VAL_ 668 VZE_Zeichen_04_Kamera 0 "nicht_erkannt" 1 "erkannt" ;
VAL_ 668 VZE_Zeichen_04_KameraWied 0 "inaktiv" 1 "aktiv" ;
VAL_ 668 VZE_Zeichen_04_Karte 0 "inaktiv" 1 "aktiv" ;
VAL_ 668 VZE_Warnung_Verkehrszeichen_4 0 "keine_Warnung_Initialwert_Fehlerwert" 1 "Warnung" ;
VAL_ 668 VZE_Warnung_Verkehrszeichen_5 0 "keine_Warnung_Initialwert_Fehlerwert" 1 "Warnung" ;
VAL_ 668 VZE_Zeichen_05_Gesetz 0 "nicht_erkannt" 1 "erkannt" ;
VAL_ 668 VZE_Zusatzschild_4 0 "keine_Zusatzschild_Initialwert_Fehlerwert" ;
VAL_ 668 VZE_Zusatzschild_5 0 "keine_Zusatzschild_Initialwert_Fehlerwert" ;
VAL_ 668 VZE_Baustelle 0 "Keine_Baustelle" 1 "Baustelle_erkannt" ;
VAL_ 668 VZE_Zeichen_05_Karte 0 "inaktiv" 1 "aktiv" ;
